VERSION "HNNBNNNYNNNNNNNNNNNNNNNNNNNNNNNNNNNNNNNNNN/4/%%%/4/'%**4NNN///"

NS_ :

BS_:

BU_: Radar MPC2

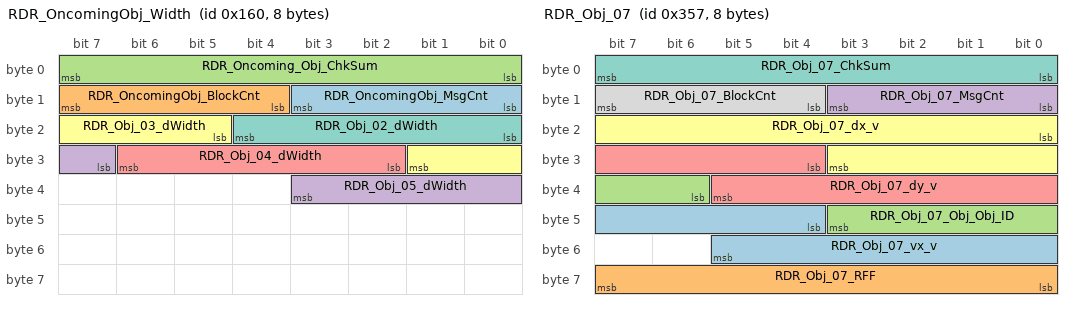
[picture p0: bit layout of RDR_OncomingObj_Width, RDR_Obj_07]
BO_ 352 RDR_OncomingObj_Width: 8 Radar
 SG_ RDR_OncomingObj_MsgCnt : 8|4@1+ (1,0) [0|15] ""  MPC2
 SG_ RDR_OncomingObj_BlockCnt : 12|4@1+ (1,0) [0|15] ""  MPC2
 SG_ RDR_Oncoming_Obj_ChkSum : 0|8@1+ (1,0) [0|255] ""  MPC2
 SG_ RDR_Obj_05_dWidth : 31|5@1+ (0.1,0) [0|3.1] ""  MPC2
 SG_ RDR_Obj_04_dWidth : 26|5@1+ (0.1,0) [0|3.1] ""  MPC2
 SG_ RDR_Obj_03_dWidth : 21|5@1+ (0.1,0) [0|3.1] ""  MPC2
 SG_ RDR_Obj_02_dWidth : 16|5@1+ (0.1,0) [0|3.1] ""  MPC2

BO_ 855 RDR_Obj_07: 8 Radar
 SG_ RDR_Obj_07_vx_v : 44|10@1+ (0.25,-128) [-128|127.75] "Unit_MeterPerSecon"  MPC2
 SG_ RDR_Obj_07_RFF : 56|8@1+ (1,0) [0|255] ""  MPC2
 SG_ RDR_Obj_07_Obj_Obj_ID : 38|6@1+ (1,0) [0|63] ""  MPC2
 SG_ RDR_Obj_07_MsgCnt : 8|4@1+ (1,0) [0|15] ""  MPC2
 SG_ RDR_Obj_07_dy_v : 28|10@1+ (0.0625,-32) [-32|31.9375] "Unit_Meter"  MPC2
 SG_ RDR_Obj_07_dx_v : 16|12@1+ (0.0625,0) [0|255.938] "Unit_Meter"  MPC2
 SG_ RDR_Obj_07_ChkSum : 0|8@1+ (1,0) [0|255] ""  MPC2
 SG_ RDR_Obj_07_BlockCnt : 12|4@1+ (1,0) [0|15] ""  MPC2

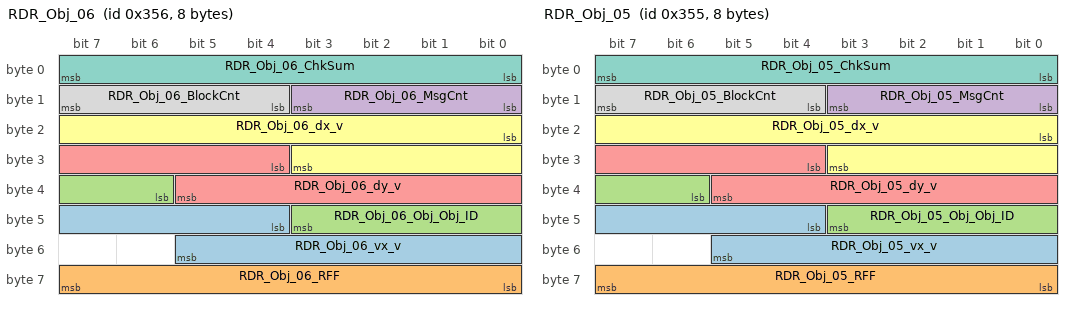
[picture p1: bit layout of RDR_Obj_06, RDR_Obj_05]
BO_ 854 RDR_Obj_06: 8 Radar
 SG_ RDR_Obj_06_vx_v : 44|10@1+ (0.25,-128) [-128|127.75] "Unit_MeterPerSecon"  MPC2
 SG_ RDR_Obj_06_RFF : 56|8@1+ (1,0) [0|255] ""  MPC2
 SG_ RDR_Obj_06_Obj_Obj_ID : 38|6@1+ (1,0) [0|63] ""  MPC2
 SG_ RDR_Obj_06_MsgCnt : 8|4@1+ (1,0) [0|155] ""  MPC2
 SG_ RDR_Obj_06_dy_v : 28|10@1+ (0.0625,-32) [-32|31.9375] "Unit_Meter"  MPC2
 SG_ RDR_Obj_06_dx_v : 16|12@1+ (0.0625,0) [0|255.938] "Unit_Meter"  MPC2
 SG_ RDR_Obj_06_ChkSum : 0|8@1+ (1,0) [0|255] ""  MPC2
 SG_ RDR_Obj_06_BlockCnt : 12|4@1+ (1,0) [0|15] ""  MPC2

BO_ 853 RDR_Obj_05: 8 Radar
 SG_ RDR_Obj_05_vx_v : 44|10@1+ (0.25,-128) [-128|127.75] "Unit_MeterPerSecon"  MPC2
 SG_ RDR_Obj_05_RFF : 56|8@1+ (1,0) [0|255] ""  MPC2
 SG_ RDR_Obj_05_Obj_Obj_ID : 38|6@1+ (1,0) [0|63] ""  MPC2
 SG_ RDR_Obj_05_MsgCnt : 8|4@1+ (1,0) [0|15] ""  MPC2
 SG_ RDR_Obj_05_dy_v : 28|10@1+ (0.0625,-32) [-32|31.9375] "Unit_Meter"  MPC2
 SG_ RDR_Obj_05_dx_v : 16|12@1+ (0.0625,0) [0|255.938] "Unit_Meter"  MPC2
 SG_ RDR_Obj_05_ChkSum : 0|8@1+ (1,0) [0|255] ""  MPC2
 SG_ RDR_Obj_05_BlockCnt : 12|4@1+ (1,0) [0|15] ""  MPC2

BO_ 7 New_Message_167: 8 Vector__XXX
 SG_ New_Signal_913 : 7|8@1+ (1,0) [0|0] "" Vector__XXX

BO_ 6 New_Message_166: 8 Vector__XXX
 SG_ New_Signal_912 : 19|8@1+ (1,0) [0|0] "" Vector__XXX

BO_ 5 New_Message_165: 8 Vector__XXX
 SG_ New_Signal_911 : 3|8@1+ (1,0) [0|0] "" Vector__XXX

BO_ 4 New_Message_164: 8 Vector__XXX
 SG_ New_Signal_910 : 39|8@1+ (1,0) [0|0] "" Vector__XXX

BO_ 3 New_Message_163: 8 Vector__XXX
 SG_ New_Signal_909 : 23|8@1+ (1,0) [0|0] "" Vector__XXX

BO_ 2 New_Message_162: 8 Vector__XXX
 SG_ New_Signal_908 : 7|8@1+ (1,0) [0|0] "" Vector__XXX

BO_ 1 New_Message_161: 8 Vector__XXX
 SG_ New_Signal_907 : 37|8@1+ (1,0) [0|0] "" Vector__XXX

BO_ 0 New_Message_160: 8 Vector__XXX
 SG_ New_Signal_906 : 12|8@1+ (1,0) [0|0] "" Vector__XXX

BO_ 2617162291 DEV_RADAR_I9: 8 Vector__XXX
 SG_ DEV_RADAR_I9_Data : 0|64@1+ (1,0) [0|1.84467440737096E+019] "" Vector__XXX

BO_ 2617162290 DEV_RADAR_I8: 8 Vector__XXX
 SG_ DEV_RADAR_I8_Data : 0|64@1+ (1,0) [0|1.84467440737096E+019] "" Vector__XXX

BO_ 2617162289 DEV_RADAR_I7: 8 Vector__XXX
 SG_ DEV_RADAR_I7_Data : 0|64@1+ (1,0) [0|1.84467440737096E+019] "" Vector__XXX

BO_ 2617162288 DEV_RADAR_I6: 8 Vector__XXX
 SG_ DEV_RADAR_I6_Data : 0|64@1+ (1,0) [0|1.84467440737096E+019] "" Vector__XXX

BO_ 2617162287 DEV_RADAR_I5: 8 Vector__XXX
 SG_ DEV_RADAR_I5_Data : 0|64@1+ (1,0) [0|1.84467440737096E+019] "" Vector__XXX

BO_ 2617162286 DEV_RADAR_I4: 8 Vector__XXX
 SG_ DEV_RADAR_I4_Data : 0|64@1+ (1,0) [0|1.84467440737096E+019] "" Vector__XXX

BO_ 2617162285 DEV_RADAR_I32: 8 Vector__XXX
 SG_ DEV_RADAR_I32_Data : 0|64@1+ (1,0) [0|1.84467440737096E+019] "" Vector__XXX

BO_ 2617162284 DEV_RADAR_I31: 8 Vector__XXX
 SG_ DEV_RADAR_I31_Data : 0|64@1+ (1,0) [0|1.84467440737096E+019] "" Vector__XXX

BO_ 2617162283 DEV_RADAR_I30: 8 Vector__XXX
 SG_ DEV_RADAR_I30_Data : 0|64@1+ (1,0) [0|1.84467440737096E+019] "" Vector__XXX

BO_ 2617162282 DEV_RADAR_I3: 8 Vector__XXX
 SG_ DEV_RADAR_I3_Data : 0|64@1+ (1,0) [0|1.84467440737096E+019] "" Vector__XXX

BO_ 2617162281 DEV_RADAR_I29: 8 Vector__XXX
 SG_ DEV_RADAR_I29_Data : 0|64@1+ (1,0) [0|1.84467440737096E+019] "" Vector__XXX

BO_ 2617162280 DEV_RADAR_I28: 8 Vector__XXX
 SG_ DEV_RADAR_I28_Data : 0|64@1+ (1,0) [0|1.84467440737096E+019] "" Vector__XXX

BO_ 2617162279 DEV_RADAR_I27: 8 Vector__XXX
 SG_ DEV_RADAR_I27_Data : 0|64@1+ (1,0) [0|1.84467440737096E+019] "" Vector__XXX

BO_ 2617162278 DEV_RADAR_I26: 8 Vector__XXX
 SG_ DEV_RADAR_I26_Data : 0|64@1+ (1,0) [0|1.84467440737096E+019] "" Vector__XXX

BO_ 2617162277 DEV_RADAR_I25: 8 Vector__XXX
 SG_ DEV_RADAR_I25_Data : 0|64@1+ (1,0) [0|1.84467440737096E+019] "" Vector__XXX

BO_ 2617162276 DEV_RADAR_I24: 8 Vector__XXX
 SG_ DEV_RADAR_I24_Data : 0|64@1+ (1,0) [0|1.84467440737096E+019] "" Vector__XXX

BO_ 2617162275 DEV_RADAR_I23: 8 Vector__XXX
 SG_ DEV_RADAR_I23_Data : 0|64@1+ (1,0) [0|1.84467440737096E+019] "" Vector__XXX

BO_ 2617162274 DEV_RADAR_I22: 8 Vector__XXX
 SG_ DEV_RADAR_I22_Data : 0|64@1+ (1,0) [0|1.84467440737096E+019] "" Vector__XXX

BO_ 2617162273 DEV_RADAR_I21: 8 Vector__XXX
 SG_ DEV_RADAR_I21_Data : 0|64@1+ (1,0) [0|1.84467440737096E+019] "" Vector__XXX

BO_ 2617162271 DEV_RADAR_I2: 8 Vector__XXX
 SG_ DEV_RADAR_I2_Data : 0|64@1+ (1,0) [0|1.84467440737096E+019] "" Vector__XXX

BO_ 2617162270 DEV_RADAR_I19: 8 Vector__XXX
 SG_ DEV_RADAR_I19_Data : 0|64@1+ (1,0) [0|1.84467440737096E+019] "" Vector__XXX

BO_ 2617162269 DEV_RADAR_I18: 8 Vector__XXX
 SG_ DEV_RADAR_I18_Data : 0|64@1+ (1,0) [0|1.84467440737096E+019] "" Vector__XXX

BO_ 2617162268 DEV_RADAR_I17: 8 Vector__XXX
 SG_ DEV_RADAR_I17_Data : 0|64@1+ (1,0) [0|1.84467440737096E+019] "" Vector__XXX

BO_ 2617162267 DEV_RADAR_I16: 8 Vector__XXX
 SG_ DEV_RADAR_I16_Data : 0|64@1+ (1,0) [0|1.84467440737096E+019] "" Vector__XXX

BO_ 2617162266 DEV_RADAR_I15: 8 Vector__XXX
 SG_ DEV_RADAR_I15_Data : 0|64@1+ (1,0) [0|1.84467440737096E+019] "" Vector__XXX

BO_ 2617162265 DEV_RADAR_I14: 8 Vector__XXX
 SG_ DEV_RADAR_I14_Data : 0|64@1+ (1,0) [0|1.84467440737096E+019] "" Vector__XXX

BO_ 2617162264 DEV_RADAR_I13: 8 Vector__XXX
 SG_ DEV_RADAR_I13_Data : 0|64@1+ (1,0) [0|1.84467440737096E+019] "" Vector__XXX

BO_ 2617162263 DEV_RADAR_I12: 8 Vector__XXX
 SG_ DEV_RADAR_I12_Data : 0|64@1+ (1,0) [0|1.84467440737096E+019] "" Vector__XXX

BO_ 2617162262 DEV_RADAR_I11: 8 Vector__XXX
 SG_ DEV_RADAR_I11_Data : 0|64@1+ (1,0) [0|1.84467440737096E+019] "" Vector__XXX

BO_ 2617162272 DEV_RADAR_I20: 8 Vector__XXX
 SG_ DEV_RADAR_I20_Data : 0|64@1+ (1,0) [0|1.84467440737096E+019] "" Vector__XXX

BO_ 2617162261 DEV_RADAR_I10: 8 Vector__XXX
 SG_ DEV_RADAR_I10_Data : 0|64@1+ (1,0) [0|1.84467440737096E+019] "" Vector__XXX

BO_ 2617162260 DEV_RADAR_I1: 8 Vector__XXX
 SG_ DEV_RADAR_I1_Data : 0|64@1+ (1,0) [0|1.84467440737096E+019] "" Vector__XXX

BO_ 2617162258 DEV_VR_Function_TX: 8 Vector__XXX
 SG_ DEV_VR_Function_TX_Data : 0|64@1+ (1,0) [0|1.84467440737096E+019] "" Vector__XXX

BO_ 2617162259 DEV_ACC_TX_15: 8 Vector__XXX
 SG_ DEV_ACC_TX_15_Data : 0|64@1+ (1,0) [0|1.84467440737096E+019] "" Vector__XXX

BO_ 2617162248 DEV_ACC_TX_06: 8 Vector__XXX
 SG_ DEV_ACC_TX_06_Data : 0|64@1+ (1,0) [0|1.84467440737096E+019] "" Vector__XXX

BO_ 2617162247 DEV_ACC_TX_05: 8 Vector__XXX
 SG_ DEV_ACC_TX_05_Data : 0|64@1+ (1,0) [0|1.84467440737096E+019] "" Vector__XXX

BO_ 2617162246 DEV_ACC_TX_04: 8 Vector__XXX
 SG_ DEV_ACC_TX_04_Data : 0|64@1+ (1,0) [0|1.84467440737096E+019] "" Vector__XXX

BO_ 2617162245 DEV_ACC_TX_03: 8 Vector__XXX
 SG_ DEV_ACC_TX_03_Data : 0|64@1+ (1,0) [0|1.84467440737096E+019] "" Vector__XXX

BO_ 2617162256 DEV_ACC_TX_14: 8 Vector__XXX
 SG_ DEV_ACC_TX_14_Data : 0|64@1+ (1,0) [0|1.84467440737096E+019] "" Vector__XXX

BO_ 2617162254 DEV_ACC_TX_12: 8 Vector__XXX
 SG_ DEV_ACC_TX_12_Data : 0|64@1+ (1,0) [0|1.84467440737096E+019] "" Vector__XXX

BO_ 2617162253 DEV_ACC_TX_11: 8 Vector__XXX
 SG_ DEV_ACC_TX_11_Data : 0|64@1+ (1,0) [0|1.84467440737096E+019] "" Vector__XXX

BO_ 2617162252 DEV_ACC_TX_10: 8 Vector__XXX
 SG_ DEV_ACC_TX_10_Data : 0|64@1+ (1,0) [0|1.84467440737096E+019] "" Vector__XXX

BO_ 2617162251 DEV_ACC_TX_09: 8 Vector__XXX
 SG_ DEV_ACC_TX_09_Data : 0|64@1+ (1,0) [0|1.84467440737096E+019] "" Vector__XXX

BO_ 2617162250 DEV_ACC_TX_08: 8 Vector__XXX
 SG_ DEV_ACC_TX_08_Data : 0|64@1+ (1,0) [0|1.84467440737096E+019] "" Vector__XXX

BO_ 2617162249 DEV_ACC_TX_07: 8 Vector__XXX
 SG_ DEV_ACC_TX_07_Data : 0|64@1+ (1,0) [0|1.84467440737096E+019] "" Vector__XXX

BO_ 2617162244 DEV_ACC_TX_02: 8 Vector__XXX
 SG_ DEV_ACC_TX_02_Data : 0|64@1+ (1,0) [0|1.84467440737096E+019] "" Vector__XXX

BO_ 2617162243 DEV_ACC_TX_01: 8 Vector__XXX
 SG_ DEV_ACC_TX_01_Data : 0|64@1+ (1,0) [0|1.84467440737096E+019] "" Vector__XXX

BO_ 2617162255 DEV_ACC_TX_13: 8 Vector__XXX
 SG_ DEV_ACC_TX_13_Data : 0|64@1+ (1,0) [0|1.84467440737096E+019] "" Vector__XXX

BO_ 2617162257 DEV_VIDEO_Sync_TX: 8 Vector__XXX
 SG_ DEV_VIDEO_Sync_TX_Data : 0|64@1+ (1,0) [0|1.84467E+019] "" Vector__XXX

BO_ 2281601536 Dev_Video_SyncVisor_TX: 8 MPC2
 SG_ ImgTimeDelay : 32|32@1+ (0.1,0) [0|429496729.5] "ms" Vector__XXX
 SG_ ImgFrameCounter : 0|32@1+ (1,0) [0|4294967295] ""  Radar

BO_ 2617145882 BV_TRAMO_01: 8 MPC2
 SG_ BV_Tramo_Yaw : 18|14@1- (2E-005,0) [-0.16384|0.16382] "Unit_Radia" Vector__XXX
 SG_ BV_Tramo_Roll : 32|14@1- (2E-005,0) [-0.16384|0.16382] "Unit_Radia" Vector__XXX
 SG_ BV_Tramo_Pitch : 4|14@1- (2E-005,0) [-0.16384|0.16384] "Unit_Radia" Vector__XXX
 SG_ BV_Tramo_Counter : 48|4@1+ (1,0) [0|15] "" Vector__XXX
 SG_ BV_Tramo_Blockzaehler : 0|4@1+ (1,0) [0|15] "" Vector__XXX

BO_ 2617145883 BV_SUMO_01: 8 MPC2
 SG_ BV_Sumo_ver_Kruemm_Aend : 37|26@1- (1E-008,0) [-0.33554432|0.33554431] "Unit_per_square_meter" Vector__XXX
 SG_ BV_Sumo_ver_Kruemm : 11|26@1- (1E-008,0) [-0.33554432|0.33554431] "Unit_per_meter" Vector__XXX
 SG_ BV_Sumo_Vorausschau : 4|7@1+ (1,0) [0|127] "Unit_meter" Vector__XXX
 SG_ BV_Sumo_Blockzaehler : 0|4@1+ (1,0) [0|15] "" Vector__XXX

BO_ 2617146880 XCP_Kamera_DTO_01: 8 MPC2
 SG_ XCP_Kamera_DTO_01_Data : 0|64@1+ (1,0) [0|1.84467440737096E+019] "" Vector__XXX

BO_ 2617146881 XCP_Kamera_CRO_01: 8 Vector__XXX
 SG_ XCP_Kamera_CRO_01_Data : 0|64@1+ (1,0) [0|1.84467440737096E+019] ""  MPC2

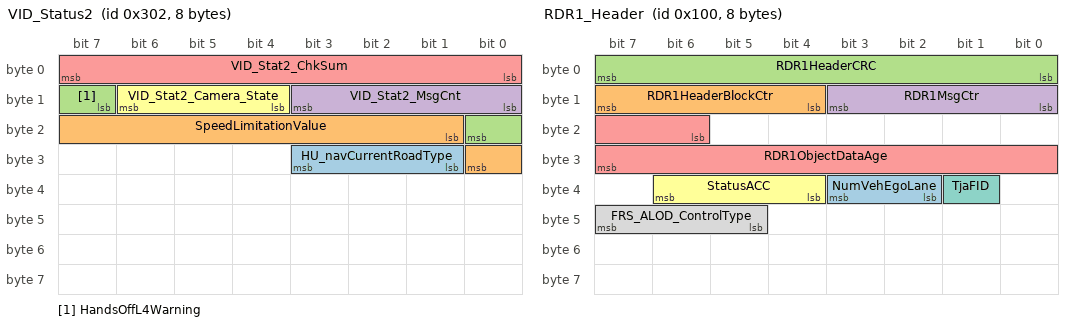
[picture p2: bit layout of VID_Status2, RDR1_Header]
BO_ 770 VID_Status2: 8 MPC2
 SG_ HU_navCurrentRoadType : 25|3@1+ (1,0) [0|7] ""  Radar
 SG_ SpeedLimitationValue : 17|8@1+ (1,0) [0|254] "Km/h"  Radar
 SG_ HandsOffL4Warning : 15|2@1+ (1,0) [0|3] ""  Radar
 SG_ VID_Stat2_MsgCnt : 8|4@1+ (1,0) [0|15] ""  Radar
 SG_ VID_Stat2_ChkSum : 0|8@1+ (1,0) [0|255] ""  Radar
 SG_ VID_Stat2_Camera_State : 12|3@1+ (1,0) [0|7] ""  Radar

BO_ 256 RDR1_Header: 8 Radar
 SG_ NumVehEgoLane : 34|2@1+ (1,0) [0|3] ""  MPC2
 SG_ RDR1HeaderBlockCtr : 12|4@1+ (1,0) [0|15] ""  MPC2
 SG_ RDR1HeaderCRC : 0|8@1+ (1,0) [0|255] ""  MPC2
 SG_ RDR1MsgCtr : 8|4@1+ (1,0) [0|15] ""  MPC2
 SG_ RDR1ObjectDataAge : 22|10@1+ (0.0009765625,0) [0|0.998046875] "Seconds"  MPC2
 SG_ StatusACC : 36|3@1+ (1,0) [0|7] ""  MPC2
 SG_ TjaFID : 33|1@1+ (1,0) [0|1] ""  MPC2
 SG_ FRS_ALOD_ControlType : 45|3@1+ (1,0) [0|7] ""  MPC2

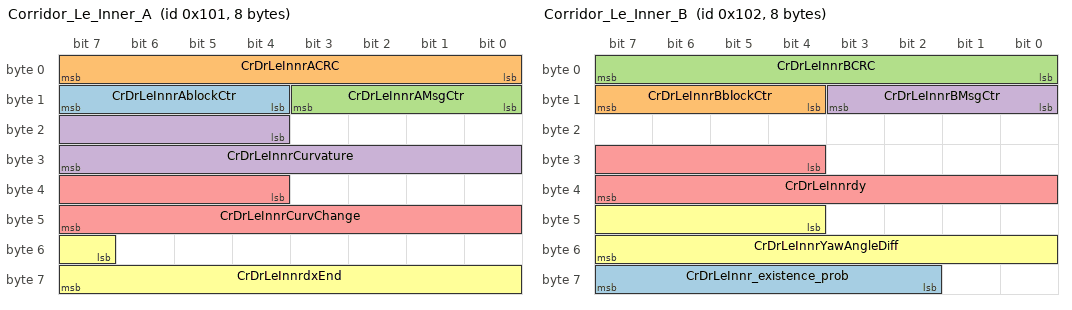
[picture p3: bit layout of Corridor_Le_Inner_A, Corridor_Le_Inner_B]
BO_ 257 Corridor_Le_Inner_A: 8 Radar
 SG_ CrDrLeInnrAblockCtr : 12|4@1+ (1,0) [0|15] ""  MPC2
 SG_ CrDrLeInnrACRC : 0|8@1+ (1,0) [0|255] ""  MPC2
 SG_ CrDrLeInnrAMsgCtr : 8|4@1+ (1,0) [0|15] ""  MPC2
 SG_ CrDrLeInnrCurvature : 20|12@1+ (1,-2047) [-2047|2048] "per_meter"  MPC2
 SG_ CrDrLeInnrCurvChange : 36|12@1+ (1,-2047) [-2047|2048] "per_square_meter"  MPC2
 SG_ CrDrLeInnrdxEnd : 55|9@1+ (0.25,0) [0|127.75] "Unit_Meter"  MPC2

BO_ 258 Corridor_Le_Inner_B: 8 Radar
 SG_ CrDrLeInnr_existence_prob : 58|6@1+ (0.015625,0) [0|0.984375] ""  MPC2
 SG_ CrDrLeInnrBblockCtr : 12|4@1+ (1,0) [0|15] ""  MPC2
 SG_ CrDrLeInnrBCRC : 0|8@1+ (1,0) [0|255] ""  MPC2
 SG_ CrDrLeInnrBMsgCtr : 8|4@1+ (1,0) [0|15] ""  MPC2
 SG_ CrDrLeInnrdy : 28|12@1+ (0.00390625,-8) [-8|7.99609375] "Unit_Meter"  MPC2
 SG_ CrDrLeInnrYawAngleDiff : 44|12@1+ (0.00048828125,-1) [-1|0.99951171875] "Radians"  MPC2

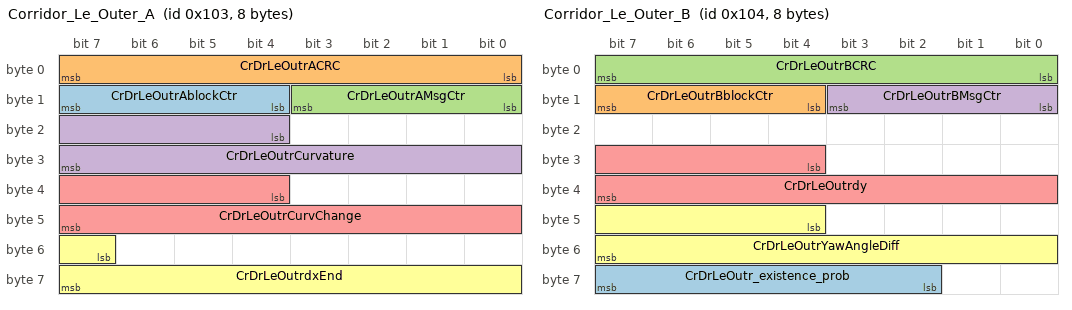
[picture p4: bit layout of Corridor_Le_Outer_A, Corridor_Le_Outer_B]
BO_ 259 Corridor_Le_Outer_A: 8 Radar
 SG_ CrDrLeOutrAblockCtr : 12|4@1+ (1,0) [0|15] ""  MPC2
 SG_ CrDrLeOutrACRC : 0|8@1+ (1,0) [0|255] ""  MPC2
 SG_ CrDrLeOutrAMsgCtr : 8|4@1+ (1,0) [0|15] ""  MPC2
 SG_ CrDrLeOutrCurvature : 20|12@1+ (1,-2047) [-2047|2048] "per_meter"  MPC2
 SG_ CrDrLeOutrCurvChange : 36|12@1+ (1,-2047) [-2047|2048] "per_square_meter"  MPC2
 SG_ CrDrLeOutrdxEnd : 55|9@1+ (0.25,0) [0|127.75] "Unit_Meter"  MPC2

BO_ 260 Corridor_Le_Outer_B: 8 Radar
 SG_ CrDrLeOutr_existence_prob : 58|6@1+ (0.015625,0) [0|0.984375] ""  MPC2
 SG_ CrDrLeOutrBblockCtr : 12|4@1+ (1,0) [0|15] ""  MPC2
 SG_ CrDrLeOutrBCRC : 0|8@1+ (1,0) [0|255] ""  MPC2
 SG_ CrDrLeOutrBMsgCtr : 8|4@1+ (1,0) [0|15] ""  MPC2
 SG_ CrDrLeOutrdy : 28|12@1+ (0.00390625,-8) [-8|7.99609375] "Unit_Meter"  MPC2
 SG_ CrDrLeOutrYawAngleDiff : 44|12@1+ (0.00048828125,-1) [-1|0.99951171875] "Radians"  MPC2

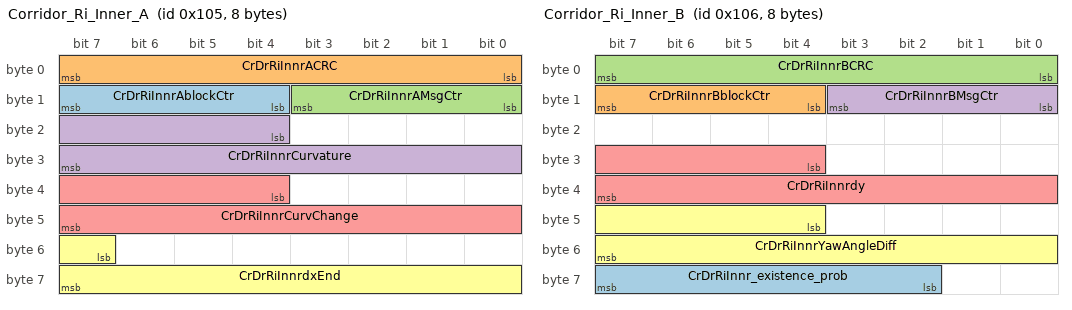
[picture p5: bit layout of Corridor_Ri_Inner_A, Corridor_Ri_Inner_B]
BO_ 261 Corridor_Ri_Inner_A: 8 Radar
 SG_ CrDrRiInnrAblockCtr : 12|4@1+ (1,0) [0|15] ""  MPC2
 SG_ CrDrRiInnrACRC : 0|8@1+ (1,0) [0|255] ""  MPC2
 SG_ CrDrRiInnrAMsgCtr : 8|4@1+ (1,0) [0|15] ""  MPC2
 SG_ CrDrRiInnrCurvature : 20|12@1+ (1,-2047) [-2047|2048] "per_meter"  MPC2
 SG_ CrDrRiInnrCurvChange : 36|12@1+ (1,-2047) [-2047|2048] "per_square_meter"  MPC2
 SG_ CrDrRiInnrdxEnd : 55|9@1+ (0.25,0) [0|127.75] "Unit_Meter"  MPC2

BO_ 262 Corridor_Ri_Inner_B: 8 Radar
 SG_ CrDrRiInnr_existence_prob : 58|6@1+ (0.015625,0) [0|0.984375] ""  MPC2
 SG_ CrDrRiInnrBblockCtr : 12|4@1+ (1,0) [0|15] ""  MPC2
 SG_ CrDrRiInnrBCRC : 0|8@1+ (1,0) [0|255] ""  MPC2
 SG_ CrDrRiInnrBMsgCtr : 8|4@1+ (1,0) [0|15] ""  MPC2
 SG_ CrDrRiInnrdy : 28|12@1+ (0.00390625,-8) [-8|7.99609375] "Unit_Meter"  MPC2
 SG_ CrDrRiInnrYawAngleDiff : 44|12@1+ (0.00048828125,-1) [-1|0.99951171875] "Radians"  MPC2

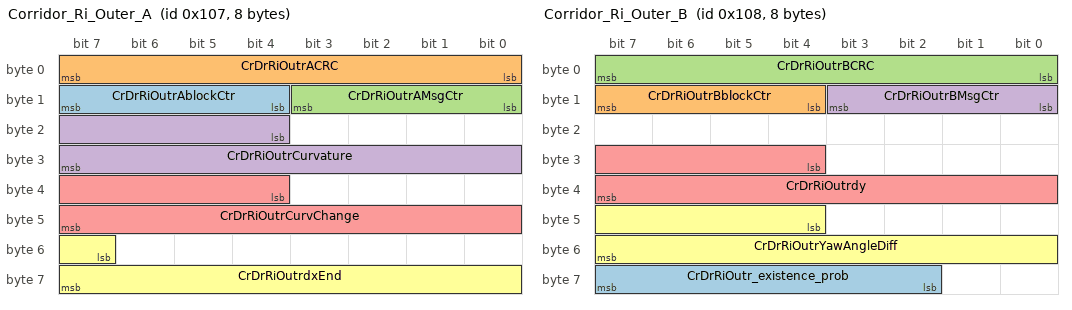
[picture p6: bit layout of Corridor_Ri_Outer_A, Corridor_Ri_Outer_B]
BO_ 263 Corridor_Ri_Outer_A: 8 Radar
 SG_ CrDrRiOutrAblockCtr : 12|4@1+ (1,0) [0|15] ""  MPC2
 SG_ CrDrRiOutrACRC : 0|8@1+ (1,0) [0|255] ""  MPC2
 SG_ CrDrRiOutrAMsgCtr : 8|4@1+ (1,0) [0|15] ""  MPC2
 SG_ CrDrRiOutrCurvature : 20|12@1+ (1,-2047) [-2047|2048] "per_meter"  MPC2
 SG_ CrDrRiOutrCurvChange : 36|12@1+ (1,-2047) [-2047|2048] "per_square_meter"  MPC2
 SG_ CrDrRiOutrdxEnd : 55|9@1+ (0.25,0) [0|127.75] "Unit_Meter"  MPC2

BO_ 264 Corridor_Ri_Outer_B: 8 Radar
 SG_ CrDrRiOutr_existence_prob : 58|6@1+ (0.015625,0) [0|0.984375] ""  MPC2
 SG_ CrDrRiOutrBblockCtr : 12|4@1+ (1,0) [0|15] ""  MPC2
 SG_ CrDrRiOutrBCRC : 0|8@1+ (1,0) [0|255] ""  MPC2
 SG_ CrDrRiOutrBMsgCtr : 8|4@1+ (1,0) [0|15] ""  MPC2
 SG_ CrDrRiOutrdy : 28|12@1+ (0.00390625,-8) [-8|7.99609375] "Unit_Meter"  MPC2
 SG_ CrDrRiOutrYawAngleDiff : 44|12@1+ (0.00048828125,-1) [-1|0.99951171875] "Radians"  MPC2

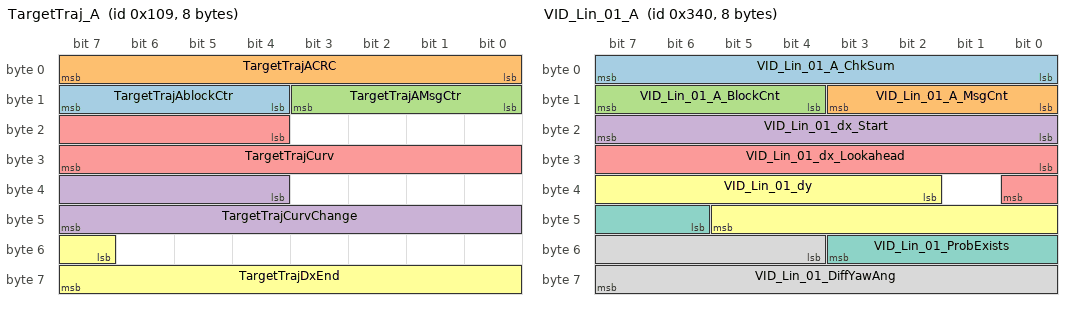
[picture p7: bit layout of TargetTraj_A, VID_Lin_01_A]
BO_ 265 TargetTraj_A: 8 Radar
 SG_ TargetTrajAblockCtr : 12|4@1+ (1,0) [0|15] ""  MPC2
 SG_ TargetTrajACRC : 0|8@1+ (1,0) [0|255] ""  MPC2
 SG_ TargetTrajAMsgCtr : 8|4@1+ (1,0) [0|15] ""  MPC2
 SG_ TargetTrajCurvChange : 36|12@1+ (1,-2047) [-2047|2048] ""  MPC2
 SG_ TargetTrajCurv : 20|12@1+ (1,-2047) [-2047|2048] ""  MPC2
 SG_ TargetTrajDxEnd : 55|9@1+ (0.25,0) [0|127.75] "Unit_Meter"  MPC2

BO_ 266 TargetTraj_B: 8 Radar
 SG_ TargetTrajBblockCtr : 12|4@1+ (1,0) [0|15] ""  MPC2
 SG_ TargetTrajBCRC : 0|8@1+ (1,0) [0|255] ""  MPC2
 SG_ TargetTrajBMsgCtr : 8|4@1+ (1,0) [0|15] ""  MPC2
 SG_ TargetTrajDy : 52|12@1+ (0.00390625,-8) [-8|7.99609375] "Unit_Meter"  MPC2
 SG_ TargetTrajExistnceProb : 26|6@1+ (0.015625,0) [0|0.984375] ""  MPC2
 SG_ TargetTrajYawAngleDiff : 36|12@1+ (0.00048828125,-1) [-1|0.99951171875] "Radians"  MPC2

BO_ 769 VID_Status: 8 MPC2
 SG_ VID_Stat_ChkSum : 0|8@1+ (1,0) [0|255] ""  Radar
 SG_ VID_Stat_MsgCnt : 8|4@1+ (1,0) [0|15] ""  Radar
 SG_ VID_Stat_BlockCnt : 12|4@1+ (1,0) [0|15] ""  Radar
 SG_ VID_Stat_ObjDataAge : 16|10@1+ (0.0009765625,0) [0|0.998046875] "Unit_Secon"  Radar
 SG_ VID_Stat_Upd_Cnt : 26|4@1+ (1,0) [0|15] ""  Radar
 SG_ VID_Stat_Intruder : 30|1@1+ (1,0) [0|1] ""  Radar
 SG_ VID_LDA_Counter : 32|4@1+ (1,0) [0|15] ""  Radar
 SG_ VID_Stat_MOD_Cnt : 36|4@1+ (1,0) [0|15] ""  Radar
 SG_ VID_Stat_PED_Warning : 40|2@1+ (1,0) [0|3] ""  Radar
 SG_ VID_Stat_RFD_notAvail : 42|2@1+ (1,0) [0|3] ""  Radar
 SG_ VID_Stat_PED_Config : 44|3@1+ (1,0) [0|7] ""  Radar
 SG_ VID_Stat_LaneDataAge : 47|10@1+ (0.0009765625,0) [0|0.998046875] "Unit_Secon"  Radar
 SG_ VID_Stat_blindness_det : 61|1@1+ (1,0) [0|1] ""  Radar
 SG_ VID_Stat_Freesight_nOK : 60|1@1+ (1,0) [0|1] ""  Radar
 SG_ VID_Stat_Error : 62|1@1+ (1,0) [0|1] ""  Radar
 SG_ VID_Stat_NotAvail : 63|1@1+ (1,0) [0|1] ""  Radar
 SG_ VID_Stat_TJAICAStatus : 57|3@1+ (1,0) [0|7] ""  Radar

BO_ 832 VID_Lin_01_A: 8 MPC2
 SG_ VID_Lin_01_A_ChkSum : 0|8@1+ (1,0) [0|255] ""  Radar
 SG_ VID_Lin_01_A_MsgCnt : 8|4@1+ (1,0) [0|15] ""  Radar
 SG_ VID_Lin_01_A_BlockCnt : 12|4@1+ (1,0) [0|15] ""  Radar
 SG_ VID_Lin_01_dx_Start : 16|8@1+ (0.25,0) [0|63.75] "Unit_Meter"  Radar
 SG_ VID_Lin_01_dx_Lookahead : 24|9@1+ (0.25,0) [0|127.75] "Unit_Meter"  Radar
 SG_ VID_Lin_01_dy : 34|12@1+ (0.00390625,-8) [-8|7.99609375] "Unit_Meter"  Radar
 SG_ VID_Lin_01_ProbExists : 46|6@1+ (0.015625,0) [0|0.984375] "Unit_Meter"  Radar
 SG_ VID_Lin_01_DiffYawAng : 52|12@1+ (0.00048828125,-1) [-1|0.99951171875] "Unit_Radia"  Radar

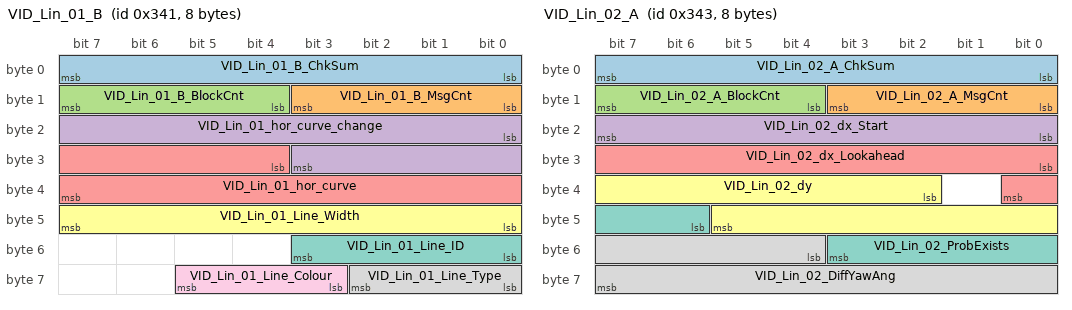
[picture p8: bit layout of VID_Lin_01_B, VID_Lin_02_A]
BO_ 833 VID_Lin_01_B: 8 MPC2
 SG_ VID_Lin_01_B_ChkSum : 0|8@1+ (1,0) [0|255] ""  Radar
 SG_ VID_Lin_01_B_MsgCnt : 8|4@1+ (1,0) [0|15] ""  Radar
 SG_ VID_Lin_01_B_BlockCnt : 12|4@1+ (1,0) [0|15] ""  Radar
 SG_ VID_Lin_01_hor_curve_change : 16|12@1+ (1,-2047) [-2047|2048] ""  Radar
 SG_ VID_Lin_01_hor_curve : 28|12@1+ (1,-2047) [-2047|2048] ""  Radar
 SG_ VID_Lin_01_Line_Width : 40|8@1+ (0.00390625,0) [0|0.99609375] "Unit_Meter"  Radar
 SG_ VID_Lin_01_Line_ID : 48|4@1+ (1,0) [1|15] ""  Radar
 SG_ VID_Lin_01_Line_Type : 56|3@1+ (1,0) [0|7] ""  Radar
 SG_ VID_Lin_01_Line_Colour : 59|3@1+ (1,0) [0|7] ""  Radar

BO_ 835 VID_Lin_02_A: 8 MPC2
 SG_ VID_Lin_02_A_ChkSum : 0|8@1+ (1,0) [0|255] ""  Radar
 SG_ VID_Lin_02_A_MsgCnt : 8|4@1+ (1,0) [0|15] ""  Radar
 SG_ VID_Lin_02_A_BlockCnt : 12|4@1+ (1,0) [0|15] ""  Radar
 SG_ VID_Lin_02_dx_Start : 16|8@1+ (0.25,0) [0|63.75] "Unit_Meter"  Radar
 SG_ VID_Lin_02_dx_Lookahead : 24|9@1+ (0.25,0) [0|127.75] "Unit_Meter"  Radar
 SG_ VID_Lin_02_dy : 34|12@1+ (0.00390625,-8) [-8|7.99609375] "Unit_Meter"  Radar
 SG_ VID_Lin_02_ProbExists : 46|6@1+ (0.015625,0) [0|0.984375] "Unit_Meter"  Radar
 SG_ VID_Lin_02_DiffYawAng : 52|12@1+ (0.00048828125,-1) [-1|0.99951171875] "Unit_Radia"  Radar

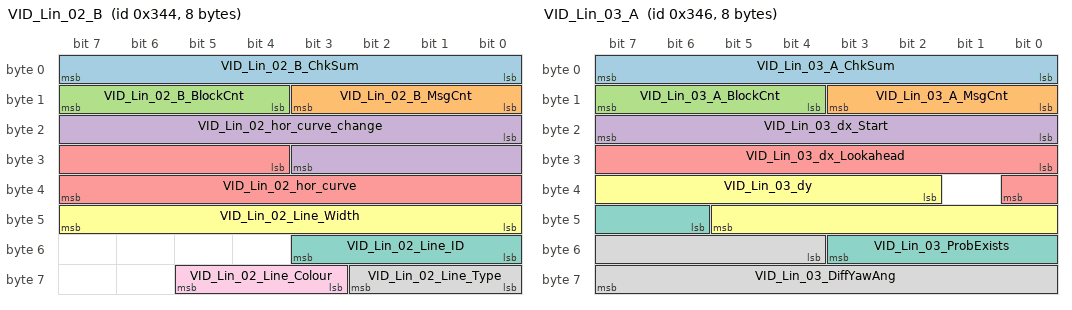
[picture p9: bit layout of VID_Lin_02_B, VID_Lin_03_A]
BO_ 836 VID_Lin_02_B: 8 MPC2
 SG_ VID_Lin_02_B_ChkSum : 0|8@1+ (1,0) [0|255] ""  Radar
 SG_ VID_Lin_02_B_MsgCnt : 8|4@1+ (1,0) [0|15] ""  Radar
 SG_ VID_Lin_02_B_BlockCnt : 12|4@1+ (1,0) [0|15] ""  Radar
 SG_ VID_Lin_02_hor_curve_change : 16|12@1+ (1,-2047) [-2047|2048] ""  Radar
 SG_ VID_Lin_02_hor_curve : 28|12@1+ (1,-2047) [-2047|2048] ""  Radar
 SG_ VID_Lin_02_Line_Width : 40|8@1+ (0.00390625,0) [0|0.99609375] "Unit_Meter"  Radar
 SG_ VID_Lin_02_Line_ID : 48|4@1+ (1,0) [1|15] ""  Radar
 SG_ VID_Lin_02_Line_Type : 56|3@1+ (1,0) [0|7] ""  Radar
 SG_ VID_Lin_02_Line_Colour : 59|3@1+ (1,0) [0|7] ""  Radar

BO_ 838 VID_Lin_03_A: 8 MPC2
 SG_ VID_Lin_03_A_ChkSum : 0|8@1+ (1,0) [0|255] ""  Radar
 SG_ VID_Lin_03_A_MsgCnt : 8|4@1+ (1,0) [0|15] ""  Radar
 SG_ VID_Lin_03_A_BlockCnt : 12|4@1+ (1,0) [0|15] ""  Radar
 SG_ VID_Lin_03_dx_Start : 16|8@1+ (0.25,0) [0|63.75] "Unit_Meter"  Radar
 SG_ VID_Lin_03_dx_Lookahead : 24|9@1+ (0.25,0) [0|127.75] "Unit_Meter"  Radar
 SG_ VID_Lin_03_dy : 34|12@1+ (0.00390625,-8) [-8|7.99609375] "Unit_Meter"  Radar
 SG_ VID_Lin_03_ProbExists : 46|6@1+ (0.015625,0) [0|0.984375] "Unit_Meter"  Radar
 SG_ VID_Lin_03_DiffYawAng : 52|12@1+ (0.00048828125,-1) [-1|0.99951171875] "Unit_Radia"  Radar

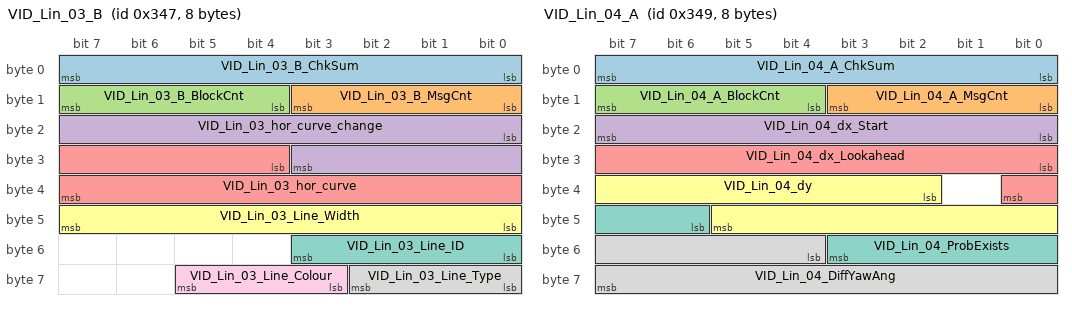
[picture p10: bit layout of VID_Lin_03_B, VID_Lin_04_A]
BO_ 839 VID_Lin_03_B: 8 MPC2
 SG_ VID_Lin_03_B_ChkSum : 0|8@1+ (1,0) [0|255] ""  Radar
 SG_ VID_Lin_03_B_MsgCnt : 8|4@1+ (1,0) [0|15] ""  Radar
 SG_ VID_Lin_03_B_BlockCnt : 12|4@1+ (1,0) [0|15] ""  Radar
 SG_ VID_Lin_03_hor_curve_change : 16|12@1+ (1,-2047) [-2047|2048] ""  Radar
 SG_ VID_Lin_03_hor_curve : 28|12@1+ (1,-2047) [-2047|2048] ""  Radar
 SG_ VID_Lin_03_Line_Width : 40|8@1+ (0.00390625,0) [0|0.99609375] "Unit_Meter"  Radar
 SG_ VID_Lin_03_Line_ID : 48|4@1+ (1,0) [1|15] ""  Radar
 SG_ VID_Lin_03_Line_Type : 56|3@1+ (1,0) [0|7] ""  Radar
 SG_ VID_Lin_03_Line_Colour : 59|3@1+ (1,0) [0|7] ""  Radar

BO_ 841 VID_Lin_04_A: 8 MPC2
 SG_ VID_Lin_04_A_ChkSum : 0|8@1+ (1,0) [0|255] ""  Radar
 SG_ VID_Lin_04_A_MsgCnt : 8|4@1+ (1,0) [0|15] ""  Radar
 SG_ VID_Lin_04_A_BlockCnt : 12|4@1+ (1,0) [0|15] ""  Radar
 SG_ VID_Lin_04_dx_Start : 16|8@1+ (0.25,0) [0|63.75] "Unit_Meter"  Radar
 SG_ VID_Lin_04_dx_Lookahead : 24|9@1+ (0.25,0) [0|127.75] "Unit_Meter"  Radar
 SG_ VID_Lin_04_dy : 34|12@1+ (0.00390625,-8) [-8|7.99609375] "Unit_Meter"  Radar
 SG_ VID_Lin_04_ProbExists : 46|6@1+ (0.015625,0) [0|0.984375] "Unit_Meter"  Radar
 SG_ VID_Lin_04_DiffYawAng : 52|12@1+ (0.00048828125,-1) [-1|0.99951171875] "Unit_Radia"  Radar

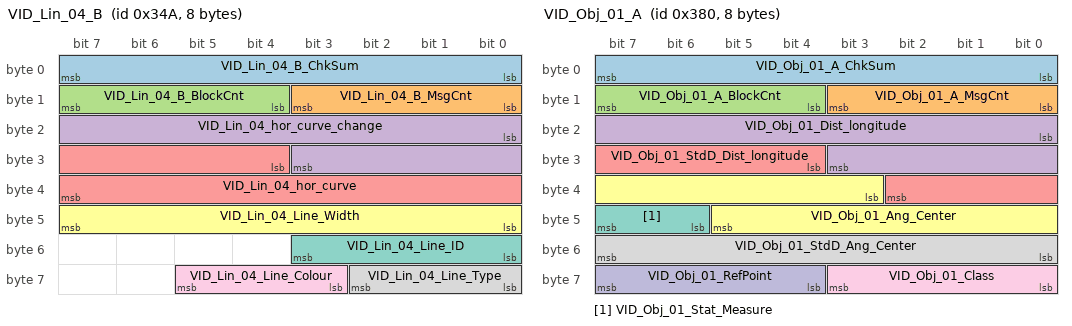
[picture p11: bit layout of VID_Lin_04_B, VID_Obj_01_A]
BO_ 842 VID_Lin_04_B: 8 MPC2
 SG_ VID_Lin_04_B_ChkSum : 0|8@1+ (1,0) [0|255] ""  Radar
 SG_ VID_Lin_04_B_MsgCnt : 8|4@1+ (1,0) [0|15] ""  Radar
 SG_ VID_Lin_04_B_BlockCnt : 12|4@1+ (1,0) [0|15] ""  Radar
 SG_ VID_Lin_04_hor_curve_change : 16|12@1+ (1,-2047) [-2047|2048] ""  Radar
 SG_ VID_Lin_04_hor_curve : 28|12@1+ (1,-2047) [-2047|2048] ""  Radar
 SG_ VID_Lin_04_Line_Width : 40|8@1+ (0.00390625,0) [0|0.99609375] "Unit_Meter"  Radar
 SG_ VID_Lin_04_Line_ID : 48|4@1+ (1,0) [1|15] ""  Radar
 SG_ VID_Lin_04_Line_Type : 56|3@1+ (1,0) [0|7] ""  Radar
 SG_ VID_Lin_04_Line_Colour : 59|3@1+ (1,0) [0|7] ""  Radar

BO_ 1385 VID_Mounting: 8 MPC2
 SG_ VID_MountPos_MsgCnt : 8|4@1+ (1,0) [0|15] "" Vector__XXX
 SG_ VID_MountPos_ChkSum : 0|8@1+ (1,0) [0|255] "" Vector__XXX
 SG_ VID_MountPos_x : 12|12@1+ (0.0009765625,-1.5) [-1.5|2.498046875] "Unit_Meter"  Radar
 SG_ VID_MountPos_y : 24|12@1+ (0.0009765625,-2) [-2|1.998046875] "Unit_Meter"  Radar
 SG_ VID_MountPos_z : 36|12@1+ (0.0009765625,-1) [-1|2.998046875] "Unit_Meter"  Radar

BO_ 896 VID_Obj_01_A: 8 MPC2
 SG_ VID_Obj_01_A_ChkSum : 0|8@1+ (1,0) [0|255] ""  Radar
 SG_ VID_Obj_01_A_MsgCnt : 8|4@1+ (1,0) [0|15] ""  Radar
 SG_ VID_Obj_01_A_BlockCnt : 12|4@1+ (1,0) [0|15] ""  Radar
 SG_ VID_Obj_01_Dist_longitude : 16|12@1+ (0.0625,0) [0|255.875] "Unit_Meter"  Radar
 SG_ VID_Obj_01_StdD_Dist_longitude : 28|7@1+ (0.25,0) [0|31.5] "Unit_Meter"  Radar
 SG_ VID_Obj_01_Ang_Center : 35|11@1+ (0.00048828125,-0.5) [-0.5|0.4990234375] "Unit_Radia"  Radar
 SG_ VID_Obj_01_Stat_Measure : 46|2@1+ (1,0) [0|3] ""  Radar
 SG_ VID_Obj_01_StdD_Ang_Center : 48|8@1+ (0.0009765625,0) [0|0.248046875] "Unit_Radia"  Radar
 SG_ VID_Obj_01_Class : 56|4@1+ (1,0) [0|15] ""  Radar
 SG_ VID_Obj_01_RefPoint : 60|4@1+ (1,0) [0|15] ""  Radar

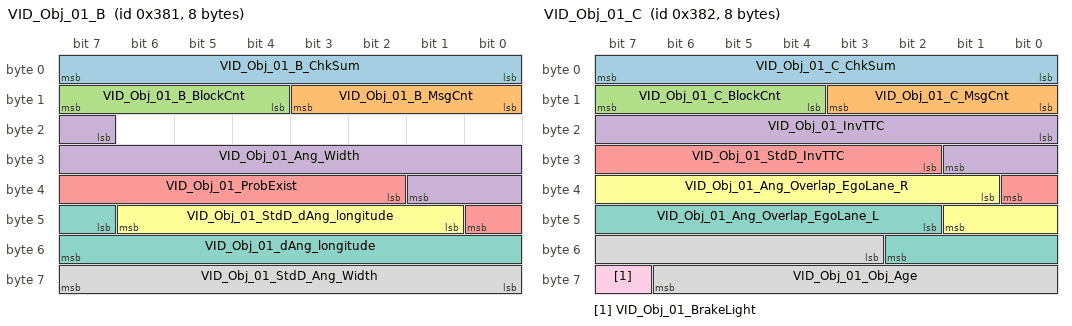
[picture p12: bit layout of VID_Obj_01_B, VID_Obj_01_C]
BO_ 897 VID_Obj_01_B: 8 MPC2
 SG_ VID_Obj_01_B_ChkSum : 0|8@1+ (1,0) [0|255] ""  Radar
 SG_ VID_Obj_01_B_MsgCnt : 8|4@1+ (1,0) [0|15] ""  Radar
 SG_ VID_Obj_01_B_BlockCnt : 12|4@1+ (1,0) [0|15] ""  Radar
 SG_ VID_Obj_01_Ang_Width : 23|11@1+ (0.00048828125,0) [0|0.9990234375] "Unit_Radia"  Radar
 SG_ VID_Obj_01_ProbExist : 34|7@1+ (0.0078125,0.015625) [0.015625|1] ""  Radar
 SG_ VID_Obj_01_StdD_dAng_longitude : 41|6@1+ (0.01,0) [0|0.62] "Unit_RadiaPerSecon"  Radar
 SG_ VID_Obj_01_dAng_longitude : 47|9@1+ (0.005,-1.25) [-1.25|1.3] "Unit_RadiaPerSecon"  Radar
 SG_ VID_Obj_01_StdD_Ang_Width : 56|8@1+ (0.0009765625,0) [0|0.248046875] "Unit_Radia"  Radar

BO_ 898 VID_Obj_01_C: 8 MPC2
 SG_ VID_Obj_01_C_ChkSum : 0|8@1+ (1,0) [0|255] ""  Radar
 SG_ VID_Obj_01_C_MsgCnt : 8|4@1+ (1,0) [0|15] ""  Radar
 SG_ VID_Obj_01_C_BlockCnt : 12|4@1+ (1,0) [0|15] ""  Radar
 SG_ VID_Obj_01_InvTTC : 16|10@1+ (0.015625,-8) [-8|7.96875] "Unit_Hertz"  Radar
 SG_ VID_Obj_01_StdD_InvTTC : 26|7@1+ (0.0625,0) [0|7.875] "Unit_Hertz"  Radar
 SG_ VID_Obj_01_Ang_Overlap_EgoLane_R : 33|9@1+ (0.0009765625,-0.25) [-0.25|0.248046875] "Unit_Radia"  Radar
 SG_ VID_Obj_01_Ang_Overlap_EgoLane_L : 42|9@1+ (0.0009765625,-0.25) [-0.25|0.248046875] "Unit_Radia"  Radar
 SG_ VID_Obj_01_Obj_Age : 51|12@1+ (1,0) [0|4094] ""  Radar
 SG_ VID_Obj_01_BrakeLight : 63|1@1+ (1,0) [0|1] ""  Radar

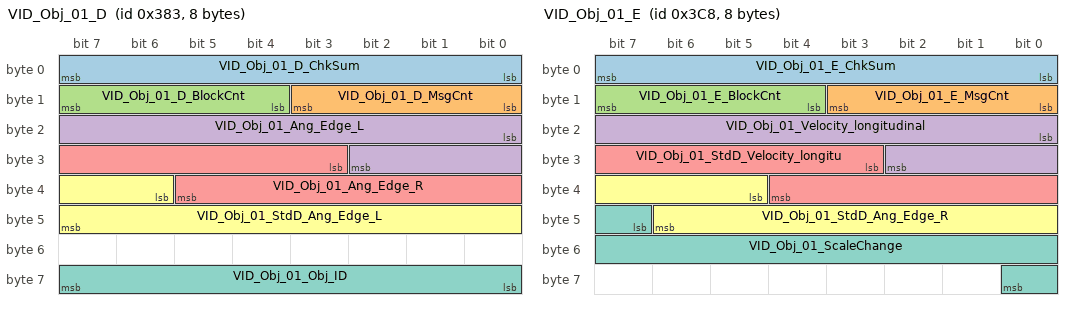
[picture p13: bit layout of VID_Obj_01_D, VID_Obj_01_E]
BO_ 899 VID_Obj_01_D: 8 MPC2
 SG_ VID_Obj_01_D_ChkSum : 0|8@1+ (1,0) [0|255] ""  Radar
 SG_ VID_Obj_01_D_MsgCnt : 8|4@1+ (1,0) [0|15] ""  Radar
 SG_ VID_Obj_01_D_BlockCnt : 12|4@1+ (1,0) [0|15] ""  Radar
 SG_ VID_Obj_01_Ang_Edge_L : 16|11@1+ (0.00048828125,-0.5) [-0.5|0.49951171875] "Unit_Radia"  Radar
 SG_ VID_Obj_01_Ang_Edge_R : 27|11@1+ (0.00048828125,-0.5) [-0.5|0.49951171875] "Unit_Radia"  Radar
 SG_ VID_Obj_01_StdD_Ang_Edge_L : 38|10@1+ (0.00048828125,-0.25) [-0.25|0.24951171875] "Unit_Radia"  Radar
 SG_ VID_Obj_01_Obj_ID : 56|8@1+ (1,0) [1|254] ""  Radar

BO_ 968 VID_Obj_01_E: 8 MPC2
 SG_ VID_Obj_01_E_ChkSum : 0|8@1+ (1,0) [0|255] ""  Radar
 SG_ VID_Obj_01_E_MsgCnt : 8|4@1+ (1,0) [0|15] ""  Radar
 SG_ VID_Obj_01_E_BlockCnt : 12|4@1+ (1,0) [0|15] ""  Radar
 SG_ VID_Obj_01_Velocity_longitudinal : 16|11@1+ (0.01388889,-12) [-12|12.00000192] "Unit_MeterPerSecon"  Radar
 SG_ VID_Obj_01_StdD_Velocity_longitu : 27|10@1+ (0.00694444,0) [0|6.0069406] "Unit_MeterPerSecon"  Radar
 SG_ VID_Obj_01_StdD_Ang_Edge_R : 37|10@1+ (0.00048828125,-0.25) [-0.25|0.24951171875] "Unit_Radia"  Radar
 SG_ VID_Obj_01_ScaleChange : 47|10@1+ (0.001,0.5) [0.5|1.5] ""  Radar

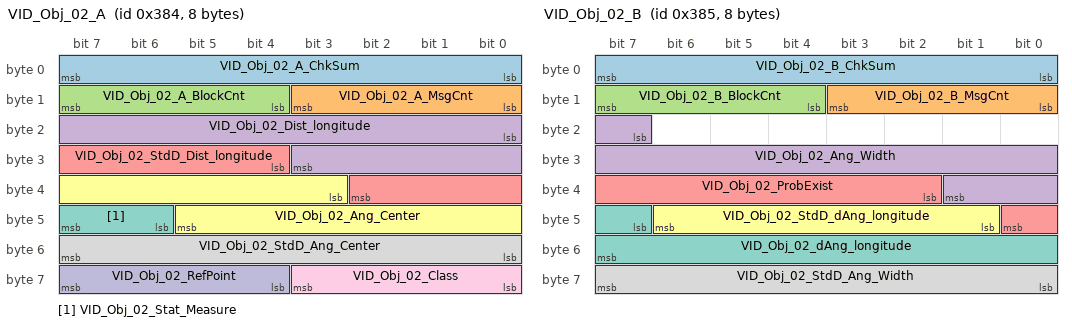
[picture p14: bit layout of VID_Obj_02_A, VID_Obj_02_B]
BO_ 900 VID_Obj_02_A: 8 MPC2
 SG_ VID_Obj_02_A_ChkSum : 0|8@1+ (1,0) [0|255] ""  Radar
 SG_ VID_Obj_02_A_MsgCnt : 8|4@1+ (1,0) [0|15] ""  Radar
 SG_ VID_Obj_02_A_BlockCnt : 12|4@1+ (1,0) [0|15] ""  Radar
 SG_ VID_Obj_02_Dist_longitude : 16|12@1+ (0.0625,0) [0|255.875] "Unit_Meter"  Radar
 SG_ VID_Obj_02_StdD_Dist_longitude : 28|7@1+ (0.25,0) [0|31.5] "Unit_Meter"  Radar
 SG_ VID_Obj_02_Ang_Center : 35|11@1+ (0.00048828125,-0.5) [-0.5|0.4990234375] "Unit_Radia"  Radar
 SG_ VID_Obj_02_Stat_Measure : 46|2@1+ (1,0) [0|3] ""  Radar
 SG_ VID_Obj_02_StdD_Ang_Center : 48|8@1+ (0.0009765625,0) [0|0.248046875] "Unit_Radia"  Radar
 SG_ VID_Obj_02_Class : 56|4@1+ (1,0) [0|15] ""  Radar
 SG_ VID_Obj_02_RefPoint : 60|4@1+ (1,0) [0|15] ""  Radar

BO_ 901 VID_Obj_02_B: 8 MPC2
 SG_ VID_Obj_02_B_ChkSum : 0|8@1+ (1,0) [0|255] ""  Radar
 SG_ VID_Obj_02_B_MsgCnt : 8|4@1+ (1,0) [0|15] ""  Radar
 SG_ VID_Obj_02_B_BlockCnt : 12|4@1+ (1,0) [0|15] ""  Radar
 SG_ VID_Obj_02_Ang_Width : 23|11@1+ (0.00048828125,0) [0|0.9990234375] "Unit_Radia"  Radar
 SG_ VID_Obj_02_ProbExist : 34|7@1+ (0.0078125,0.015625) [0.015625|1] ""  Radar
 SG_ VID_Obj_02_StdD_dAng_longitude : 41|6@1+ (0.01,0) [0|0.62] "Unit_RadiaPerSecon"  Radar
 SG_ VID_Obj_02_dAng_longitude : 47|9@1+ (0.005,-1.25) [-1.25|1.3] "Unit_RadiaPerSecon"  Radar
 SG_ VID_Obj_02_StdD_Ang_Width : 56|8@1+ (0.0009765625,0) [0|0.248046875] "Unit_Radia"  Radar

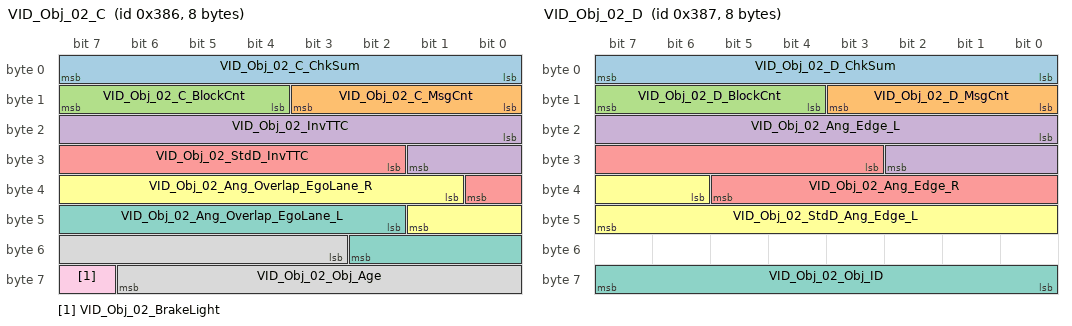
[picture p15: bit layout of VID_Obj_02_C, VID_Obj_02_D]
BO_ 902 VID_Obj_02_C: 8 MPC2
 SG_ VID_Obj_02_C_ChkSum : 0|8@1+ (1,0) [0|255] ""  Radar
 SG_ VID_Obj_02_C_MsgCnt : 8|4@1+ (1,0) [0|15] ""  Radar
 SG_ VID_Obj_02_C_BlockCnt : 12|4@1+ (1,0) [0|15] ""  Radar
 SG_ VID_Obj_02_InvTTC : 16|10@1+ (0.015625,-8) [-8|7.96875] "Unit_Hertz"  Radar
 SG_ VID_Obj_02_StdD_InvTTC : 26|7@1+ (0.0625,0) [0|7.875] "Unit_Hertz"  Radar
 SG_ VID_Obj_02_Ang_Overlap_EgoLane_R : 33|9@1+ (0.0009765625,-0.25) [-0.25|0.248046875] "Unit_Radia"  Radar
 SG_ VID_Obj_02_Ang_Overlap_EgoLane_L : 42|9@1+ (0.0009765625,-0.25) [-0.25|0.248046875] "Unit_Radia"  Radar
 SG_ VID_Obj_02_Obj_Age : 51|12@1+ (1,0) [0|4094] ""  Radar
 SG_ VID_Obj_02_BrakeLight : 63|1@1+ (1,0) [0|1] ""  Radar

BO_ 903 VID_Obj_02_D: 8 MPC2
 SG_ VID_Obj_02_D_ChkSum : 0|8@1+ (1,0) [0|255] ""  Radar
 SG_ VID_Obj_02_D_MsgCnt : 8|4@1+ (1,0) [0|15] ""  Radar
 SG_ VID_Obj_02_D_BlockCnt : 12|4@1+ (1,0) [0|15] ""  Radar
 SG_ VID_Obj_02_Ang_Edge_L : 16|11@1+ (0.00048828125,-0.5) [-0.5|0.49951171875] "Unit_Radia"  Radar
 SG_ VID_Obj_02_Ang_Edge_R : 27|11@1+ (0.00048828125,-0.5) [-0.5|0.49951171875] "Unit_Radia"  Radar
 SG_ VID_Obj_02_StdD_Ang_Edge_L : 38|10@1+ (0.00048828125,-0.25) [-0.25|0.24951171875] "Unit_Radia"  Radar
 SG_ VID_Obj_02_Obj_ID : 56|8@1+ (1,0) [1|254] ""  Radar

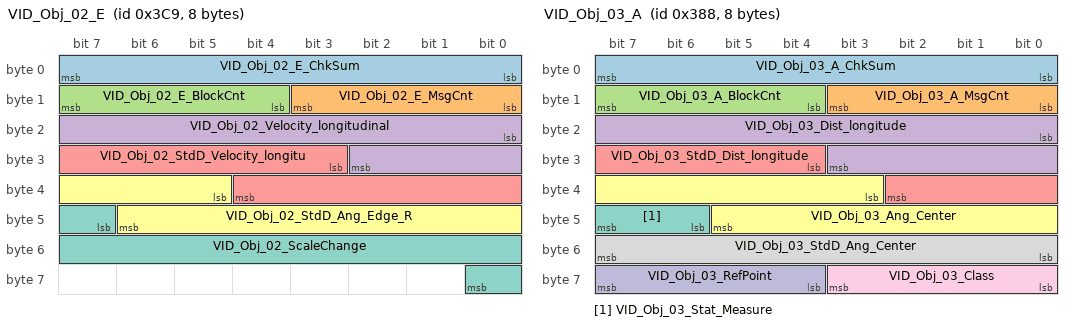
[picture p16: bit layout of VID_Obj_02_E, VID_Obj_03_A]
BO_ 969 VID_Obj_02_E: 8 MPC2
 SG_ VID_Obj_02_E_ChkSum : 0|8@1+ (1,0) [0|255] ""  Radar
 SG_ VID_Obj_02_E_MsgCnt : 8|4@1+ (1,0) [0|15] ""  Radar
 SG_ VID_Obj_02_E_BlockCnt : 12|4@1+ (1,0) [0|15] ""  Radar
 SG_ VID_Obj_02_Velocity_longitudinal : 16|11@1+ (0.01388889,-12) [-12|12.00000192] "Unit_MeterPerSecon"  Radar
 SG_ VID_Obj_02_StdD_Velocity_longitu : 27|10@1+ (0.00694444,0) [0|6.0069406] "Unit_MeterPerSecon"  Radar
 SG_ VID_Obj_02_StdD_Ang_Edge_R : 37|10@1+ (0.00048828125,-0.25) [-0.25|0.24951171875] "Unit_Radia"  Radar
 SG_ VID_Obj_02_ScaleChange : 47|10@1+ (0.001,0.5) [0.5|1.5] ""  Radar

BO_ 904 VID_Obj_03_A: 8 MPC2
 SG_ VID_Obj_03_A_ChkSum : 0|8@1+ (1,0) [0|255] ""  Radar
 SG_ VID_Obj_03_A_MsgCnt : 8|4@1+ (1,0) [0|15] ""  Radar
 SG_ VID_Obj_03_A_BlockCnt : 12|4@1+ (1,0) [0|15] ""  Radar
 SG_ VID_Obj_03_Dist_longitude : 16|12@1+ (0.0625,0) [0|255.875] "Unit_Meter"  Radar
 SG_ VID_Obj_03_StdD_Dist_longitude : 28|7@1+ (0.25,0) [0|31.5] "Unit_Meter"  Radar
 SG_ VID_Obj_03_Ang_Center : 35|11@1+ (0.00048828125,-0.5) [-0.5|0.4990234375] "Unit_Radia"  Radar
 SG_ VID_Obj_03_Stat_Measure : 46|2@1+ (1,0) [0|3] ""  Radar
 SG_ VID_Obj_03_StdD_Ang_Center : 48|8@1+ (0.0009765625,0) [0|0.248046875] "Unit_Radia"  Radar
 SG_ VID_Obj_03_Class : 56|4@1+ (1,0) [0|15] ""  Radar
 SG_ VID_Obj_03_RefPoint : 60|4@1+ (1,0) [0|15] ""  Radar

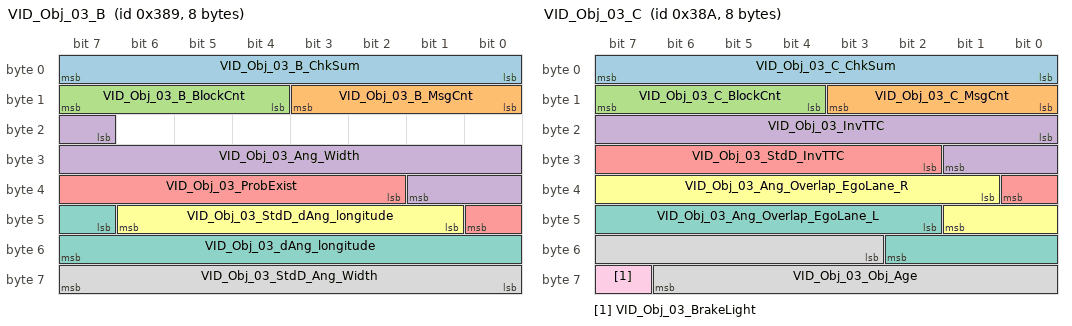
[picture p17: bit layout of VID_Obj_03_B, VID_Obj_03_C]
BO_ 905 VID_Obj_03_B: 8 MPC2
 SG_ VID_Obj_03_B_ChkSum : 0|8@1+ (1,0) [0|255] ""  Radar
 SG_ VID_Obj_03_B_MsgCnt : 8|4@1+ (1,0) [0|15] ""  Radar
 SG_ VID_Obj_03_B_BlockCnt : 12|4@1+ (1,0) [0|15] ""  Radar
 SG_ VID_Obj_03_Ang_Width : 23|11@1+ (0.00048828125,0) [0|0.9990234375] "Unit_Radia"  Radar
 SG_ VID_Obj_03_ProbExist : 34|7@1+ (0.0078125,0.015625) [0.015625|1] ""  Radar
 SG_ VID_Obj_03_StdD_dAng_longitude : 41|6@1+ (0.01,0) [0|0.62] "Unit_RadiaPerSecon"  Radar
 SG_ VID_Obj_03_dAng_longitude : 47|9@1+ (0.005,-1.25) [-1.25|1.3] "Unit_RadiaPerSecon"  Radar
 SG_ VID_Obj_03_StdD_Ang_Width : 56|8@1+ (0.0009765625,0) [0|0.248046875] "Unit_Radia"  Radar

BO_ 906 VID_Obj_03_C: 8 MPC2
 SG_ VID_Obj_03_C_ChkSum : 0|8@1+ (1,0) [0|255] ""  Radar
 SG_ VID_Obj_03_C_MsgCnt : 8|4@1+ (1,0) [0|15] ""  Radar
 SG_ VID_Obj_03_C_BlockCnt : 12|4@1+ (1,0) [0|15] ""  Radar
 SG_ VID_Obj_03_InvTTC : 16|10@1+ (0.015625,-8) [-8|7.96875] "Unit_Hertz"  Radar
 SG_ VID_Obj_03_StdD_InvTTC : 26|7@1+ (0.0625,0) [0|7.875] "Unit_Hertz"  Radar
 SG_ VID_Obj_03_Ang_Overlap_EgoLane_R : 33|9@1+ (0.0009765625,-0.25) [-0.25|0.248046875] "Unit_Radia"  Radar
 SG_ VID_Obj_03_Ang_Overlap_EgoLane_L : 42|9@1+ (0.0009765625,-0.25) [-0.25|0.248046875] "Unit_Radia"  Radar
 SG_ VID_Obj_03_Obj_Age : 51|12@1+ (1,0) [0|4094] ""  Radar
 SG_ VID_Obj_03_BrakeLight : 63|1@1+ (1,0) [0|1] ""  Radar

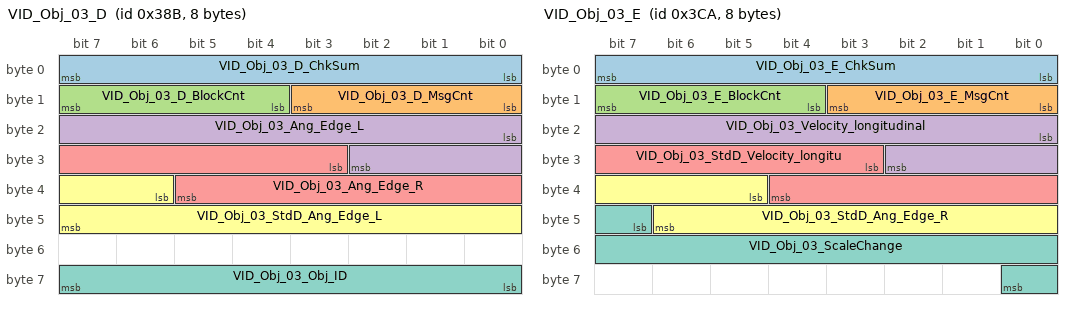
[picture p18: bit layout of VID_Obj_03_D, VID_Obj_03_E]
BO_ 907 VID_Obj_03_D: 8 MPC2
 SG_ VID_Obj_03_D_ChkSum : 0|8@1+ (1,0) [0|255] ""  Radar
 SG_ VID_Obj_03_D_MsgCnt : 8|4@1+ (1,0) [0|15] ""  Radar
 SG_ VID_Obj_03_D_BlockCnt : 12|4@1+ (1,0) [0|15] ""  Radar
 SG_ VID_Obj_03_Ang_Edge_L : 16|11@1+ (0.00048828125,-0.5) [-0.5|0.49951171875] "Unit_Radia"  Radar
 SG_ VID_Obj_03_Ang_Edge_R : 27|11@1+ (0.00048828125,-0.5) [-0.5|0.49951171875] "Unit_Radia"  Radar
 SG_ VID_Obj_03_StdD_Ang_Edge_L : 38|10@1+ (0.00048828125,-0.25) [-0.25|0.24951171875] "Unit_Radia"  Radar
 SG_ VID_Obj_03_Obj_ID : 56|8@1+ (1,0) [1|254] ""  Radar

BO_ 970 VID_Obj_03_E: 8 MPC2
 SG_ VID_Obj_03_E_ChkSum : 0|8@1+ (1,0) [0|255] ""  Radar
 SG_ VID_Obj_03_E_MsgCnt : 8|4@1+ (1,0) [0|15] ""  Radar
 SG_ VID_Obj_03_E_BlockCnt : 12|4@1+ (1,0) [0|15] ""  Radar
 SG_ VID_Obj_03_Velocity_longitudinal : 16|11@1+ (0.01388889,-12) [-12|12.00000192] "Unit_MeterPerSecon"  Radar
 SG_ VID_Obj_03_StdD_Velocity_longitu : 27|10@1+ (0.00694444,0) [0|6.0069406] "Unit_MeterPerSecon"  Radar
 SG_ VID_Obj_03_StdD_Ang_Edge_R : 37|10@1+ (0.00048828125,-0.25) [-0.25|0.24951171875] "Unit_Radia"  Radar
 SG_ VID_Obj_03_ScaleChange : 47|10@1+ (0.001,0.5) [0.5|1.5] ""  Radar

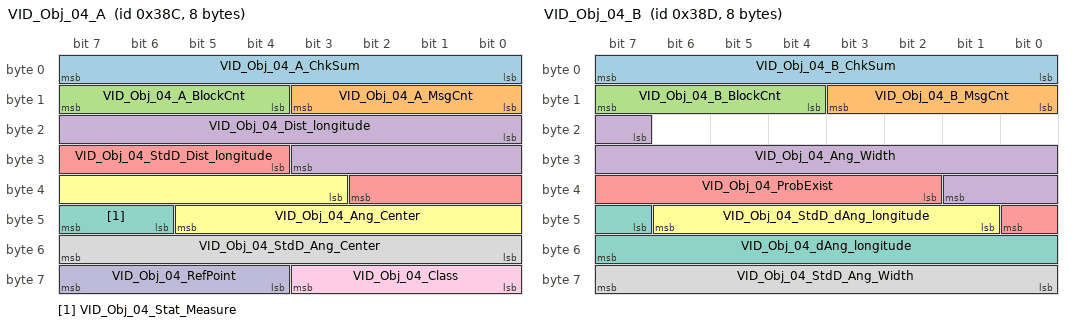
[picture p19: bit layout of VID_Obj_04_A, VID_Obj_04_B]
BO_ 908 VID_Obj_04_A: 8 MPC2
 SG_ VID_Obj_04_A_ChkSum : 0|8@1+ (1,0) [0|255] ""  Radar
 SG_ VID_Obj_04_A_MsgCnt : 8|4@1+ (1,0) [0|15] ""  Radar
 SG_ VID_Obj_04_A_BlockCnt : 12|4@1+ (1,0) [0|15] ""  Radar
 SG_ VID_Obj_04_Dist_longitude : 16|12@1+ (0.0625,0) [0|255.875] "Unit_Meter"  Radar
 SG_ VID_Obj_04_StdD_Dist_longitude : 28|7@1+ (0.25,0) [0|31.5] "Unit_Meter"  Radar
 SG_ VID_Obj_04_Ang_Center : 35|11@1+ (0.00048828125,-0.5) [-0.5|0.4990234375] "Unit_Radia"  Radar
 SG_ VID_Obj_04_Stat_Measure : 46|2@1+ (1,0) [0|3] ""  Radar
 SG_ VID_Obj_04_StdD_Ang_Center : 48|8@1+ (0.0009765625,0) [0|0.248046875] "Unit_Radia"  Radar
 SG_ VID_Obj_04_Class : 56|4@1+ (1,0) [0|15] ""  Radar
 SG_ VID_Obj_04_RefPoint : 60|4@1+ (1,0) [0|15] ""  Radar

BO_ 909 VID_Obj_04_B: 8 MPC2
 SG_ VID_Obj_04_B_ChkSum : 0|8@1+ (1,0) [0|255] ""  Radar
 SG_ VID_Obj_04_B_MsgCnt : 8|4@1+ (1,0) [0|15] ""  Radar
 SG_ VID_Obj_04_B_BlockCnt : 12|4@1+ (1,0) [0|15] ""  Radar
 SG_ VID_Obj_04_Ang_Width : 23|11@1+ (0.00048828125,0) [0|0.9990234375] "Unit_Radia"  Radar
 SG_ VID_Obj_04_ProbExist : 34|7@1+ (0.0078125,0.015625) [0.015625|1] ""  Radar
 SG_ VID_Obj_04_StdD_dAng_longitude : 41|6@1+ (0.01,0) [0|0.62] "Unit_RadiaPerSecon"  Radar
 SG_ VID_Obj_04_dAng_longitude : 47|9@1+ (0.005,-1.25) [-1.25|1.3] "Unit_RadiaPerSecon"  Radar
 SG_ VID_Obj_04_StdD_Ang_Width : 56|8@1+ (0.0009765625,0) [0|0.248046875] "Unit_Radia"  Radar

CM_ "MRR_MPC2xx_FusionCan";
CM_ BU_ Radar "Front Radar ECU (MRR1.5)";
CM_ BU_ MPC2 "Video ECU (MPC2 Premium/Plus)";
CM_ SG_ 855 RDR_Obj_07_vx_v " Relative velocity in longitudinal direction (dx) relative to the ego vehicle trajectory and the detected 3D-object block ";
CM_ SG_ 855 RDR_Obj_07_RFF "ID of the video object that has been fused with the current object";
CM_ SG_ 855 RDR_Obj_07_Obj_Obj_ID "Object/Track ID (internal)";
CM_ SG_ 855 RDR_Obj_07_MsgCnt "Message counter (rolling counter)";
CM_ SG_ 855 RDR_Obj_07_dy_v "Lateral distance (dy) relative to the ego vehicle trajectory and the detected 3D-object block";
CM_ SG_ 855 RDR_Obj_07_dx_v "Longitudinal distance (dx) relative to the ego vehicle trajectory and the detected 3D-object block";
CM_ SG_ 855 RDR_Obj_07_ChkSum "CRC8 Checksum";
CM_ SG_ 855 RDR_Obj_07_BlockCnt "Control signal to synchronize segmented blocks of object data";
CM_ SG_ 854 RDR_Obj_06_vx_v "Relative velocity in longitudinal direction (dx) relative to the ego vehicle trajectory and the detected 3D-object block 
";
CM_ SG_ 854 RDR_Obj_06_RFF "ID of the video object that has been fused with the current object";
CM_ SG_ 854 RDR_Obj_06_Obj_Obj_ID "Object/Track ID (internal)";
CM_ SG_ 854 RDR_Obj_06_MsgCnt "Message counter (rolling counter)";
CM_ SG_ 854 RDR_Obj_06_dy_v "Lateral distance (dy) relative to the ego vehicle trajectory and the detected 3D-object block";
CM_ SG_ 854 RDR_Obj_06_dx_v "Longitudinal distance (dx) relative to the ego vehicle trajectory and the detected 3D-object block";
CM_ SG_ 854 RDR_Obj_06_ChkSum "CRC8 Checksum";
CM_ SG_ 854 RDR_Obj_06_BlockCnt "Control signal to synchronize segmented blocks of object data";
CM_ SG_ 853 RDR_Obj_05_vx_v "Relative velocity in longitudinal direction (dx) relative to the ego vehicle trajectory and the detected 3D-object block ";
CM_ SG_ 853 RDR_Obj_05_RFF "ID of the video object that has been fused with the current object";
CM_ SG_ 853 RDR_Obj_05_Obj_Obj_ID "Object/Track ID (internal)";
CM_ SG_ 853 RDR_Obj_05_MsgCnt "Message counter (rolling counter)";
CM_ SG_ 853 RDR_Obj_05_dy_v "Lateral distance (dy) relative to the ego vehicle trajectory and the detected 3D-object block";
CM_ SG_ 853 RDR_Obj_05_dx_v "Longitudinal distance (dx) relative to the ego vehicle trajectory and the detected 3D-object block";
CM_ SG_ 853 RDR_Obj_05_ChkSum "CRC8 Checksum";
CM_ SG_ 853 RDR_Obj_05_BlockCnt "Control signal to synchronize segmented blocks of object data";
CM_ SG_ 2281601536 ImgFrameCounter "Zugriff auf den aktuellen Bildzähler vom OMAP aus (HAL-Funktion).";
CM_ BO_ 2617145883 "sumo kruemmung und kruemmung änderung";
CM_ SG_ 2617145883 BV_Sumo_ver_Kruemm_Aend "sumo kruemmung aenderung (per square meter)";
CM_ SG_ 2617145883 BV_Sumo_ver_Kruemm "sumo kruemmung (per meter)";
CM_ SG_ 770 VID_Stat2_MsgCnt "Message counter (rolling counter)";
CM_ SG_ 770 VID_Stat2_ChkSum "CRC8 Checksum";
CM_ SG_ 770 VID_Stat2_Camera_State "Operation State of the Camera";
CM_ SG_ 256 FRS_ALOD_ControlType "The type of the automatic longitude driving";
CM_ SG_ 257 CrDrLeInnrAblockCtr "Block counter for synchronisation
";
CM_ SG_ 257 CrDrLeInnrACRC "CRC
";
CM_ SG_ 257 CrDrLeInnrAMsgCtr "Alive Counter
";
CM_ SG_ 257 CrDrLeInnrCurvature "Inner curvature of the predicted corridor on left side
";
CM_ SG_ 257 CrDrLeInnrCurvChange "Inner curvature change of the predicted corridor on left side
";
CM_ SG_ 257 CrDrLeInnrdxEnd "Inner curvature lateral position of the predicted corridor on left side
";
CM_ SG_ 258 CrDrLeInnr_existence_prob "Existance probability of the predicted inner corridor on left side
";
CM_ SG_ 258 CrDrLeInnrBblockCtr "Block counter for synchronisation
";
CM_ SG_ 258 CrDrLeInnrBCRC "CRC
";
CM_ SG_ 258 CrDrLeInnrBMsgCtr "Alive Counter
";
CM_ SG_ 258 CrDrLeInnrdy "Inner curvature longitudinal position on left side
";
CM_ SG_ 258 CrDrLeInnrYawAngleDiff "Yaw angle difference of inner corridor with reference to vehicle position on left side
";
CM_ SG_ 259 CrDrLeOutrAblockCtr "Block counter for synchronisation
";
CM_ SG_ 259 CrDrLeOutrACRC "CRC
";
CM_ SG_ 259 CrDrLeOutrAMsgCtr "Alive Counter
";
CM_ SG_ 259 CrDrLeOutrCurvature "Outer curvature of the predicted corridor on left side
";
CM_ SG_ 259 CrDrLeOutrCurvChange "Outer curvature change of the predicted corridor on left side
";
CM_ SG_ 259 CrDrLeOutrdxEnd "Outer curvature lateral position of the predicted corridor on left side
";
CM_ SG_ 260 CrDrLeOutr_existence_prob "Existance probability of the predicted inner corridor on left side
";
CM_ SG_ 260 CrDrLeOutrBblockCtr "Block counter for synchronisation
";
CM_ SG_ 260 CrDrLeOutrBCRC "CRC
";
CM_ SG_ 260 CrDrLeOutrBMsgCtr "Alive Counter
";
CM_ SG_ 260 CrDrLeOutrdy "Outer curvature longitudinal position
";
CM_ SG_ 260 CrDrLeOutrYawAngleDiff "Yaw angle difference of Outer corridor with reference to vehicle position on left side
";
CM_ SG_ 261 CrDrRiInnrAblockCtr "Block counter for synchronisation
";
CM_ SG_ 261 CrDrRiInnrACRC "CRC
";
CM_ SG_ 261 CrDrRiInnrAMsgCtr "Alive Counter
";
CM_ SG_ 261 CrDrRiInnrCurvature "Inner curvature of the predicted corridor on right side
";
CM_ SG_ 261 CrDrRiInnrdxEnd "Inner curvature lateral position of the predicted corridor on right side
";
CM_ SG_ 262 CrDrRiInnr_existence_prob "Existance probability of the predicted inner corridor on right side
";
CM_ SG_ 262 CrDrRiInnrBblockCtr "Block counter for synchronisation
";
CM_ SG_ 262 CrDrRiInnrBCRC "CRC
";
CM_ SG_ 262 CrDrRiInnrBMsgCtr "Alive Counter
";
CM_ SG_ 262 CrDrRiInnrdy "Inner curvature longitudinal position on right side
";
CM_ SG_ 262 CrDrRiInnrYawAngleDiff "Yaw angle difference of inner corridor with reference to vehicle position on right
";
CM_ SG_ 263 CrDrRiOutrAblockCtr "Block counter for synchronisation
";
CM_ SG_ 263 CrDrRiOutrACRC "CRC
";
CM_ SG_ 263 CrDrRiOutrAMsgCtr "Alive Counter
";
CM_ SG_ 263 CrDrRiOutrCurvature "Outer curvature of the predicted corridor on right side
";
CM_ SG_ 263 CrDrRiOutrCurvChange "Outer curvature change of the predicted corridor on right side
";
CM_ SG_ 263 CrDrRiOutrdxEnd "Outer curvature lateral position of the predicted corridor on left side
";
CM_ SG_ 264 CrDrRiOutr_existence_prob "Existance probability of the predicted inner corridor on right side
";
CM_ SG_ 264 CrDrRiOutrBblockCtr "Block counter for synchronisation
";
CM_ SG_ 264 CrDrRiOutrBCRC "CRC
";
CM_ SG_ 264 CrDrRiOutrBMsgCtr "Alive Counter
";
CM_ SG_ 264 CrDrRiOutrdy "Outer curvature longitudinal position on right side
";
CM_ SG_ 264 CrDrRiOutrYawAngleDiff "Yaw angle difference of Outer corridor with reference to vehicle position on right side
";
CM_ SG_ 265 TargetTrajAblockCtr "Block counter for synchronisation
";
CM_ SG_ 265 TargetTrajACRC "Check Sum
";
CM_ SG_ 265 TargetTrajAMsgCtr "Alive counter
";
CM_ SG_ 265 TargetTrajCurvChange "Change in curvature of the target trajectory
";
CM_ SG_ 265 TargetTrajCurv "Target Trajectory Curvature
";
CM_ SG_ 266 TargetTrajBblockCtr "Block counter for synchronisation
";
CM_ SG_ 266 TargetTrajBCRC "Check Sum
";
CM_ SG_ 266 TargetTrajBMsgCtr "Alive counter
";
CM_ SG_ 266 TargetTrajExistnceProb "Existance Probability of the determined target trajectory
";
CM_ SG_ 266 TargetTrajYawAngleDiff "Yaw Angle difference of the Target Trajectory
";
CM_ SG_ 769 VID_Stat_ChkSum "CRC8 Checksum";
CM_ SG_ 769 VID_Stat_MsgCnt "Message counter (rolling counter)";
CM_ SG_ 769 VID_Stat_BlockCnt "Control signal to synchronize segmented blocks of object data";
CM_ SG_ 769 VID_Stat_ObjDataAge "Time differece between middle of measurement and broadcast on the vehicle bus";
CM_ SG_ 769 VID_Stat_Upd_Cnt "Update counter for Object and Line data";
CM_ SG_ 769 VID_Stat_Intruder "Bit is set if any object enters the monitored area (lane in front of the vehicle)";
CM_ SG_ 769 VID_LDA_Counter "Counter that represents the analyzed frame (encoded) for LDA";
CM_ SG_ 769 VID_Stat_MOD_Cnt "Counter that represents the analyzed frame (encoded) for LDA";
CM_ SG_ 769 VID_Stat_PED_Warning "System status for pedestrian warning";
CM_ SG_ 769 VID_Stat_RFD_notAvail "Intruder detection is temporary not available";
CM_ SG_ 769 VID_Stat_PED_Config "System configuration for PED protection (predictive protection)";
CM_ SG_ 769 VID_Stat_LaneDataAge "Time differece between middle of measurement and broadcast on the vehicle bus";
CM_ SG_ 769 VID_Stat_blindness_det "Blindness detection: Blindness was detected after freesight has been detected earlier";
CM_ SG_ 769 VID_Stat_Freesight_nOK "Blindness detection: Freesight has not been detected yet (after KL15 cycle)
Nach KL15-Ein konnte Freisichtprüfung noch nicht erfüllt werden";
CM_ SG_ 769 VID_Stat_Error "VideoSGU has detected an error with pending DTC";
CM_ SG_ 769 VID_Stat_NotAvail "VideoSGU has detected a temporary non availability without pending DTC";
CM_ SG_ 832 VID_Lin_01_A_ChkSum "CRC8 Checksum";
CM_ SG_ 832 VID_Lin_01_A_MsgCnt "Message counter (rolling counter)";
CM_ SG_ 832 VID_Lin_01_A_BlockCnt "Control signal to synchronize segmented blocks of object data";
CM_ SG_ 832 VID_Lin_01_dx_Start "Longitudinal distance (dx) to center of vehicle coordinate system";
CM_ SG_ 832 VID_Lin_01_dx_Lookahead "Longitudinal distance (dx) of the last measurement sample, Phys. output '0 m' if vehicle has already crossed the start of the line";
CM_ SG_ 832 VID_Lin_01_dy "Lateral distance (dy) to center of vehicle coordinate system";
CM_ SG_ 832 VID_Lin_01_ProbExists "Probability of existance for a line (or marking)
Conversion factor 2^-6";
CM_ SG_ 832 VID_Lin_01_DiffYawAng "Angle between vehicle longitudinal axis (x) and the tangent on the starting point of the track
Conversion factor 2^-11";
CM_ SG_ 833 VID_Lin_01_B_ChkSum "CRC8 Checksum";
CM_ SG_ 833 VID_Lin_01_B_MsgCnt "Message counter (rolling counter)";
CM_ SG_ 833 VID_Lin_01_B_BlockCnt "Control signal to synchronize segmented blocks of object data";
CM_ SG_ 833 VID_Lin_01_hor_curve_change "change of the horizontal curvature of the line";
CM_ SG_ 833 VID_Lin_01_hor_curve "horizontal curvature of the line";
CM_ SG_ 833 VID_Lin_01_Line_Width "Width of the line.";
CM_ SG_ 833 VID_Lin_01_Line_ID "Left master line: Line ID (image processing)";
CM_ SG_ 833 VID_Lin_01_Line_Type "Style of the line";
CM_ SG_ 833 VID_Lin_01_Line_Colour "Colour of the line";
CM_ SG_ 835 VID_Lin_02_A_ChkSum "CRC8 Checksum";
CM_ SG_ 835 VID_Lin_02_A_MsgCnt "Message counter (rolling counter)";
CM_ SG_ 835 VID_Lin_02_A_BlockCnt "Control signal to synchronize segmented blocks of object data";
CM_ SG_ 835 VID_Lin_02_dx_Start "Longitudinal distance (dx) to center of vehicle coordinate system";
CM_ SG_ 835 VID_Lin_02_dx_Lookahead "Longitudinal distance (dx) of the last measurement sample, Phys. output '0 m' if vehicle has already crossed the start of the line";
CM_ SG_ 835 VID_Lin_02_dy "Lateral distance (dy) to center of vehicle coordinate system";
CM_ SG_ 835 VID_Lin_02_ProbExists "Probability of existance for a line (or marking)
Conversion factor 2^-6";
CM_ SG_ 835 VID_Lin_02_DiffYawAng "Angle between vehicle longitudinal axis (x) and the tangent on the starting point of the track
Conversion factor 2^-11";
CM_ SG_ 836 VID_Lin_02_B_ChkSum "CRC8 Checksum";
CM_ SG_ 836 VID_Lin_02_B_MsgCnt "Message counter (rolling counter)";
CM_ SG_ 836 VID_Lin_02_B_BlockCnt "Control signal to synchronize segmented blocks of object data";
CM_ SG_ 836 VID_Lin_02_hor_curve_change "change of the horizontal curvature of the line";
CM_ SG_ 836 VID_Lin_02_hor_curve "horizontal curvature of the line";
CM_ SG_ 836 VID_Lin_02_Line_Width "Width of the line.";
CM_ SG_ 836 VID_Lin_02_Line_ID "Right master line: Line ID (image processing)";
CM_ SG_ 836 VID_Lin_02_Line_Type "Style of the line";
CM_ SG_ 836 VID_Lin_02_Line_Colour "Colour of the line";
CM_ SG_ 838 VID_Lin_03_A_ChkSum "CRC8 Checksum";
CM_ SG_ 838 VID_Lin_03_A_MsgCnt "Message counter (rolling counter)";
CM_ SG_ 838 VID_Lin_03_A_BlockCnt "Control signal to synchronize segmented blocks of object data";
CM_ SG_ 838 VID_Lin_03_dx_Start "Longitudinal distance (dx) to center of vehicle coordinate system";
CM_ SG_ 838 VID_Lin_03_dx_Lookahead "Longitudinal distance (dx) of the last measurement sample, Phys. output '0 m' if vehicle has already crossed the start of the line";
CM_ SG_ 838 VID_Lin_03_dy "Lateral distance (dy) to center of vehicle coordinate system";
CM_ SG_ 838 VID_Lin_03_ProbExists "Probability of existance for a line (or marking)
Conversion factor 2^-6";
CM_ SG_ 838 VID_Lin_03_DiffYawAng "Angle between vehicle longitudinal axis (x) and the tangent on the starting point of the track
Conversion factor 2^-11";
CM_ SG_ 839 VID_Lin_03_B_ChkSum "CRC8 Checksum";
CM_ SG_ 839 VID_Lin_03_B_MsgCnt "Message counter (rolling counter)";
CM_ SG_ 839 VID_Lin_03_B_BlockCnt "Control signal to synchronize segmented blocks of object data";
CM_ SG_ 839 VID_Lin_03_hor_curve_change "change of the horizontal curvature of the line";
CM_ SG_ 839 VID_Lin_03_hor_curve "horizontal curvature of the line
Multiplikation des Rohwerts mit 2^-16";
CM_ SG_ 839 VID_Lin_03_Line_Width "Width of the line.";
CM_ SG_ 839 VID_Lin_03_Line_ID "Line ID (image processing)";
CM_ SG_ 839 VID_Lin_03_Line_Type "Style of the line";
CM_ SG_ 839 VID_Lin_03_Line_Colour "Colour of the line";
CM_ SG_ 841 VID_Lin_04_A_ChkSum "CRC8 Checksum";
CM_ SG_ 841 VID_Lin_04_A_MsgCnt "Message counter (rolling counter)";
CM_ SG_ 841 VID_Lin_04_A_BlockCnt "Control signal to synchronize segmented blocks of object data";
CM_ SG_ 841 VID_Lin_04_dx_Start "Longitudinal distance (dx) to center of vehicle coordinate system";
CM_ SG_ 841 VID_Lin_04_dx_Lookahead "Longitudinal distance (dx) of the last measurement sample, Phys. output '0 m' if vehicle has already crossed the start of the line";
CM_ SG_ 841 VID_Lin_04_dy "Lateral distance (dy) to center of vehicle coordinate system";
CM_ SG_ 841 VID_Lin_04_ProbExists "Probability of existance for a line (or marking)
Conversion factor 2^-6";
CM_ SG_ 841 VID_Lin_04_DiffYawAng "Angle between vehicle longitudinal axis (x) and the tangent on the starting point of the track
Conversion factor 2^-11";
CM_ SG_ 842 VID_Lin_04_B_ChkSum "CRC8 Checksum";
CM_ SG_ 842 VID_Lin_04_B_MsgCnt "Message counter (rolling counter)";
CM_ SG_ 842 VID_Lin_04_B_BlockCnt "Control signal to synchronize segmented blocks of object data";
CM_ SG_ 842 VID_Lin_04_hor_curve_change "change of the horizontal curvature of the line";
CM_ SG_ 842 VID_Lin_04_hor_curve "horizontal curvature of the line";
CM_ SG_ 842 VID_Lin_04_Line_Width "Width of the line.";
CM_ SG_ 842 VID_Lin_04_Line_ID "Line ID (image processing)";
CM_ SG_ 842 VID_Lin_04_Line_Type "Style of the line";
CM_ SG_ 842 VID_Lin_04_Line_Colour "Colour of the line";
CM_ SG_ 1385 VID_MountPos_MsgCnt "Message counter (rolling counter)";
CM_ SG_ 1385 VID_MountPos_ChkSum "CRC8 Checksum";
CM_ SG_ 1385 VID_MountPos_x "Camera position in coordinate system (Vehicle mesh position). 
- x-coordinates of the optical camera focus point
- Conversion factor 2base: 2^-10";
CM_ SG_ 1385 VID_MountPos_y "Camera position in coordinate system (Vehicle mesh position). 
- y-coordinates of the optical camera focus point
- Conversion factor 2base: 2^-10";
CM_ SG_ 1385 VID_MountPos_z "Camera position in coordinate system (Vehicle mesh position). 
- z-coordinates of the optical camera focus point
- Conversion factor 2base: 2^-10";
CM_ SG_ 896 VID_Obj_01_A_ChkSum "CRC8 Checksum";
CM_ SG_ 896 VID_Obj_01_A_MsgCnt "Message counter (rolling counter)";
CM_ SG_ 896 VID_Obj_01_A_BlockCnt "Control signal to synchronize segmented blocks of object data";
CM_ SG_ 896 VID_Obj_01_Dist_longitude "Longitudinal distance relative to vehicle coordinate system";
CM_ SG_ 896 VID_Obj_01_StdD_Dist_longitude "Standard deviation for VID_Obj_01_Dist_longitude";
CM_ SG_ 896 VID_Obj_01_Ang_Center "Center of the recorded side of the 3D-object box (positive angle left of x-axis).
(Mono-Video: Rear view for vehicles). In combination with Obj_Angle_low the center
base point of the objectis described.
Coordinate system: transformed";
CM_ SG_ 896 VID_Obj_01_Stat_Measure "Object measured tracked

0 Object not measured but predicted based on 3D-model
1 Object was measured in current sample cycle
2 Object not measured but re-matched based on feature tracking";
CM_ SG_ 896 VID_Obj_01_StdD_Ang_Center "Standard deviation for VID_Obj_01_Ang_Center";
CM_ SG_ 896 VID_Obj_01_Class "Object class";
CM_ SG_ 896 VID_Obj_01_RefPoint "Index of the reference point for the 3D-object box
Info: The wording front/rear right/left relates to the indicated object orientation.
If this data is not available then a orienntation can be chosen.";
CM_ SG_ 897 VID_Obj_01_B_ChkSum "CRC8 Checksum";
CM_ SG_ 897 VID_Obj_01_B_MsgCnt "Message counter (rolling counter)";
CM_ SG_ 897 VID_Obj_01_B_BlockCnt "Control signal to synchronize segmented blocks of object data";
CM_ SG_ 897 VID_Obj_01_Ang_Width "Width of the recorded side of the 3D-object box (positive angle left of x-axis)
Monovideo: Rear view for vehicles
Coordinate system: Transformed coordinate system with camera being origin
! Ego-movement has to be compensated !";
CM_ SG_ 897 VID_Obj_01_ProbExist "Probability for the existence of an object for the given time and position (in 3sigma-area)";
CM_ SG_ 897 VID_Obj_01_StdD_dAng_longitude "Standard deviation for VID_Obj_01_dAng_longitude";
CM_ SG_ 897 VID_Obj_01_dAng_longitude "Lateral velocity of the object (related to the reference point), calculated as change of angle in the frame";
CM_ SG_ 897 VID_Obj_01_StdD_Ang_Width "Standard deviation for VID_Obj_01_Ang_Width";
CM_ SG_ 898 VID_Obj_01_C_ChkSum "CRC8 Checksum";
CM_ SG_ 898 VID_Obj_01_C_MsgCnt "Message counter (rolling counter)";
CM_ SG_ 898 VID_Obj_01_C_BlockCnt "Control signal to synchronize segmented blocks of object data";
CM_ SG_ 898 VID_Obj_01_InvTTC "Inverted value of the time-to-collision with the vertical plane of the camera ";
CM_ SG_ 898 VID_Obj_01_StdD_InvTTC "Standard deviation for VID_Obj_01_InvTTC";
CM_ SG_ 898 VID_Obj_01_Ang_Overlap_EgoLane_R "Object Line Assignment (angle based indicator for the overlap of a an object with the ego lane from the right corner)";
CM_ SG_ 898 VID_Obj_01_Ang_Overlap_EgoLane_L "Object Line Assignment (angle based indicator for the overlap of a an object with the ego lane from the left corner)";
CM_ SG_ 898 VID_Obj_01_Obj_Age "Cycle counter for the existence of the object (object sampled)";
CM_ SG_ 898 VID_Obj_01_BrakeLight "Brake light recognized on the object";
CM_ SG_ 899 VID_Obj_01_D_ChkSum "CRC8 Checksum";
CM_ SG_ 899 VID_Obj_01_D_MsgCnt "Message counter (rolling counter)";
CM_ SG_ 899 VID_Obj_01_D_BlockCnt "Control signal to synchronize segmented blocks of object data";
CM_ SG_ 899 VID_Obj_01_Ang_Edge_L "Angle of the left edge of the object
Conversion factor 2^-11";
CM_ SG_ 899 VID_Obj_01_Ang_Edge_R "Angle of the right edge of the object
Conversion factor 2^-11";
CM_ SG_ 899 VID_Obj_01_StdD_Ang_Edge_L "Standard deviation for the Angle of the left edge of the object";
CM_ SG_ 899 VID_Obj_01_Obj_ID "ID of the object";
CM_ SG_ 968 VID_Obj_01_E_ChkSum "CRC8 Checksum";
CM_ SG_ 968 VID_Obj_01_E_MsgCnt "Message counter (rolling counter)";
CM_ SG_ 968 VID_Obj_01_E_BlockCnt "Control signal to synchronize segmented blocks of object data";
CM_ SG_ 968 VID_Obj_01_Velocity_longitudinal "Longitudinal velocity of the detected object (Vehicle coordinate system)";
CM_ SG_ 968 VID_Obj_01_StdD_Velocity_longitu "Standard deviation of the Longitudinal velocity of the detected object (Vehicle coordinate system)";
CM_ SG_ 968 VID_Obj_01_StdD_Ang_Edge_R "Standard deviation for the Angle of the right edge of the object";
CM_ SG_ 968 VID_Obj_01_ScaleChange "In order to fuse a video object with a radar object at higher distance (>60m), a higher resolution for the  relative velocity is needed in that range. This signal indicates the required change of the scale.";
CM_ SG_ 900 VID_Obj_02_A_ChkSum "CRC8 Checksum";
CM_ SG_ 900 VID_Obj_02_A_MsgCnt "Message counter (rolling counter)";
CM_ SG_ 900 VID_Obj_02_A_BlockCnt "Control signal to synchronize segmented blocks of object data";
CM_ SG_ 900 VID_Obj_02_Dist_longitude "Longitudinal distance relative to vehicle coordinate system";
CM_ SG_ 900 VID_Obj_02_StdD_Dist_longitude "Standard deviation for VID_Obj_02_Dist_longitude";
CM_ SG_ 900 VID_Obj_02_Ang_Center "Center of the recorded side of the 3D-object box (positive angle left of x-axis).
(Mono-Video: Rear view for vehicles). In combination with Obj_Angle_low the center
base point of the objectis described.
Coordinate system: transformed";
CM_ SG_ 900 VID_Obj_02_Stat_Measure "Object measured tracked

0 Object not measured but predicted based on 3D-model
1 Object was measured in current sample cycle
2 Object not measured but re-matched based on feature tracking";
CM_ SG_ 900 VID_Obj_02_StdD_Ang_Center "Standard deviation for VID_Obj_02_Ang_Center";
CM_ SG_ 900 VID_Obj_02_Class "Object class";
CM_ SG_ 900 VID_Obj_02_RefPoint "Index of the reference point for the 3D-object box
Info: The wording front/rear right/left relates to the indicated object orientation.
If this data is not available then a orienntation can be chosen.";
CM_ SG_ 901 VID_Obj_02_B_ChkSum "CRC8 Checksum";
CM_ SG_ 901 VID_Obj_02_B_MsgCnt "Message counter (rolling counter)";
CM_ SG_ 901 VID_Obj_02_B_BlockCnt "Control signal to synchronize segmented blocks of object data";
CM_ SG_ 901 VID_Obj_02_Ang_Width "Width of the recorded side of the 3D-object box (positive angle left of x-axis)
Monovideo: Rear view for vehicles
Coordinate system: Transformed coordinate system with camera being origin
! Ego-movement has to be compensated !";
CM_ SG_ 901 VID_Obj_02_ProbExist "Probability for the existence of an object for the given time and position (in 3sigma-area)";
CM_ SG_ 901 VID_Obj_02_StdD_dAng_longitude "Standard deviation for VID_Obj_02_dAng_longitude";
CM_ SG_ 901 VID_Obj_02_dAng_longitude "Lateral velocity of the object (related to the reference point), calculated as change of angle in the frame";
CM_ SG_ 901 VID_Obj_02_StdD_Ang_Width "Standard deviation for VID_Obj_02_Ang_Width";
CM_ SG_ 902 VID_Obj_02_C_ChkSum "CRC8 Checksum";
CM_ SG_ 902 VID_Obj_02_C_MsgCnt "Message counter (rolling counter)";
CM_ SG_ 902 VID_Obj_02_C_BlockCnt "Control signal to synchronize segmented blocks of object data";
CM_ SG_ 902 VID_Obj_02_InvTTC "Inverted value of the time-to-collision with the vertical plane of the camera ";
CM_ SG_ 902 VID_Obj_02_StdD_InvTTC "Standard deviation for VID_Obj_02_InvTTC";
CM_ SG_ 902 VID_Obj_02_Ang_Overlap_EgoLane_R "Object Line Assignment (angle based indicator for the overlap of a an object with the ego lane from the right corner)";
CM_ SG_ 902 VID_Obj_02_Ang_Overlap_EgoLane_L "Object Line Assignment (angle based indicator for the overlap of a an object with the ego lane from the left corner)";
CM_ SG_ 902 VID_Obj_02_Obj_Age "Cycle counter for the existence of the object (object sampled)";
CM_ SG_ 902 VID_Obj_02_BrakeLight "Brake light recognized on the object";
CM_ SG_ 903 VID_Obj_02_D_ChkSum "CRC8 Checksum";
CM_ SG_ 903 VID_Obj_02_D_MsgCnt "Message counter (rolling counter)";
CM_ SG_ 903 VID_Obj_02_D_BlockCnt "Control signal to synchronize segmented blocks of object data";
CM_ SG_ 903 VID_Obj_02_Ang_Edge_L "Angle of the left edge of the object
Conversion factor 2^-11";
CM_ SG_ 903 VID_Obj_02_Ang_Edge_R "Angle of the right edge of the object
Conversion factor 2^-11";
CM_ SG_ 903 VID_Obj_02_StdD_Ang_Edge_L "Standard deviation for the Angle of the left edge of the object";
CM_ SG_ 903 VID_Obj_02_Obj_ID "ID of the object";
CM_ SG_ 969 VID_Obj_02_E_ChkSum "CRC8 Checksum";
CM_ SG_ 969 VID_Obj_02_E_MsgCnt "Message counter (rolling counter)";
CM_ SG_ 969 VID_Obj_02_E_BlockCnt "Control signal to synchronize segmented blocks of object data";
CM_ SG_ 969 VID_Obj_02_Velocity_longitudinal "Longitudinal velocity of the detected object (Vehicle coordinate system)";
CM_ SG_ 969 VID_Obj_02_StdD_Velocity_longitu "Standard deviation of the Longitudinal velocity of the detected object (Vehicle coordinate system)";
CM_ SG_ 969 VID_Obj_02_StdD_Ang_Edge_R "Standard deviation for the Angle of the right edge of the object";
CM_ SG_ 969 VID_Obj_02_ScaleChange "In order to fuse a video object with a radar object at higher distance (>60m), a higher resolution for the  relative velocity is needed in that range. This signal indicates the required change of the scale.";
CM_ SG_ 904 VID_Obj_03_A_ChkSum "CRC8 Checksum";
CM_ SG_ 904 VID_Obj_03_A_MsgCnt "Message counter (rolling counter)";
CM_ SG_ 904 VID_Obj_03_A_BlockCnt "Control signal to synchronize segmented blocks of object data";
CM_ SG_ 904 VID_Obj_03_Dist_longitude "Longitudinal distance relative to vehicle coordinate system";
CM_ SG_ 904 VID_Obj_03_StdD_Dist_longitude "Standard deviation for VID_Obj_03_Dist_longitude";
CM_ SG_ 904 VID_Obj_03_Ang_Center "Center of the recorded side of the 3D-object box (positive angle left of x-axis).
(Mono-Video: Rear view for vehicles). In combination with Obj_Angle_low the center
base point of the objectis described.
Coordinate system: transformed";
CM_ SG_ 904 VID_Obj_03_Stat_Measure "Object measured tracked

0 Object not measured but predicted based on 3D-model
1 Object was measured in current sample cycle
2 Object not measured but re-matched based on feature tracking";
CM_ SG_ 904 VID_Obj_03_StdD_Ang_Center "Standard deviation for VID_Obj_03_Ang_Center";
CM_ SG_ 904 VID_Obj_03_Class "Object class";
CM_ SG_ 904 VID_Obj_03_RefPoint "Index of the reference point for the 3D-object box
Info: The wording front/rear right/left relates to the indicated object orientation.
If this data is not available then a orienntation can be chosen.";
CM_ SG_ 905 VID_Obj_03_B_ChkSum "CRC8 Checksum";
CM_ SG_ 905 VID_Obj_03_B_MsgCnt "Message counter (rolling counter)";
CM_ SG_ 905 VID_Obj_03_B_BlockCnt "Control signal to synchronize segmented blocks of object data";
CM_ SG_ 905 VID_Obj_03_Ang_Width "Width of the recorded side of the 3D-object box (positive angle left of x-axis)
Monovideo: Rear view for vehicles
Coordinate system: Transformed coordinate system with camera being origin
! Ego-movement has to be compensated !";
CM_ SG_ 905 VID_Obj_03_ProbExist "Probability for the existence of an object for the given time and position (in 3sigma-area)";
CM_ SG_ 905 VID_Obj_03_StdD_dAng_longitude "Standard deviation for VID_Obj_03_dAng_longitude";
CM_ SG_ 905 VID_Obj_03_dAng_longitude "Lateral velocity of the object (related to the reference point), calculated as change of angle in the frame";
CM_ SG_ 905 VID_Obj_03_StdD_Ang_Width "Standard deviation for VID_Obj_03_Ang_Width";
CM_ SG_ 906 VID_Obj_03_C_ChkSum "CRC8 Checksum";
CM_ SG_ 906 VID_Obj_03_C_MsgCnt "Message counter (rolling counter)";
CM_ SG_ 906 VID_Obj_03_C_BlockCnt "Control signal to synchronize segmented blocks of object data";
CM_ SG_ 906 VID_Obj_03_InvTTC "Inverted value of the time-to-collision with the vertical plane of the camera ";
CM_ SG_ 906 VID_Obj_03_StdD_InvTTC "Standard deviation for VID_Obj_03_InvTTC";
CM_ SG_ 906 VID_Obj_03_Ang_Overlap_EgoLane_R "Object Line Assignment (angle based indicator for the overlap of a an object with the ego lane from the right corner)";
CM_ SG_ 906 VID_Obj_03_Ang_Overlap_EgoLane_L "Object Line Assignment (angle based indicator for the overlap of a an object with the ego lane from the left corner)";
CM_ SG_ 906 VID_Obj_03_Obj_Age "Cycle counter for the existence of the object (object sampled)";
CM_ SG_ 906 VID_Obj_03_BrakeLight "Brake light recognized on the object";
CM_ SG_ 907 VID_Obj_03_D_ChkSum "CRC8 Checksum";
CM_ SG_ 907 VID_Obj_03_D_MsgCnt "Message counter (rolling counter)";
CM_ SG_ 907 VID_Obj_03_D_BlockCnt "Control signal to synchronize segmented blocks of object data";
CM_ SG_ 907 VID_Obj_03_Ang_Edge_L "Angle of the left edge of the object
Conversion factor 2^-11";
CM_ SG_ 907 VID_Obj_03_Ang_Edge_R "Angle of the right edge of the object
Conversion factor 2^-11";
CM_ SG_ 907 VID_Obj_03_StdD_Ang_Edge_L "Standard deviation for the Angle of the left edge of the object";
CM_ SG_ 907 VID_Obj_03_Obj_ID "ID of the object";
CM_ SG_ 970 VID_Obj_03_E_ChkSum "CRC8 Checksum";
CM_ SG_ 970 VID_Obj_03_E_MsgCnt "Message counter (rolling counter)";
CM_ SG_ 970 VID_Obj_03_E_BlockCnt "Control signal to synchronize segmented blocks of object data";
CM_ SG_ 970 VID_Obj_03_Velocity_longitudinal "Longitudinal velocity of the detected object (Vehicle coordinate system)";
CM_ SG_ 970 VID_Obj_03_StdD_Velocity_longitu "Standard deviation of the Longitudinal velocity of the detected object (Vehicle coordinate system)";
CM_ SG_ 970 VID_Obj_03_StdD_Ang_Edge_R "Standard deviation for the Angle of the right edge of the object";
CM_ SG_ 970 VID_Obj_03_ScaleChange "In order to fuse a video object with a radar object at higher distance (>60m), a higher resolution for the  relative velocity is needed in that range. This signal indicates the required change of the scale.";
CM_ SG_ 908 VID_Obj_04_A_ChkSum "CRC8 Checksum";
CM_ SG_ 908 VID_Obj_04_A_MsgCnt "Message counter (rolling counter)";
CM_ SG_ 908 VID_Obj_04_A_BlockCnt "Control signal to synchronize segmented blocks of object data";
CM_ SG_ 908 VID_Obj_04_Dist_longitude "Longitudinal distance relative to vehicle coordinate system";
CM_ SG_ 908 VID_Obj_04_StdD_Dist_longitude "Standard deviation for VID_Obj_04_Dist_longitude";
CM_ SG_ 908 VID_Obj_04_Ang_Center "Center of the recorded side of the 3D-object box (positive angle left of x-axis).
(Mono-Video: Rear view for vehicles). In combination with Obj_Angle_low the center
base point of the objectis described.
Coordinate system: transformed";
CM_ SG_ 908 VID_Obj_04_Stat_Measure "Object measured tracked

0 Object not measured but predicted based on 3D-model
1 Object was measured in current sample cycle
2 Object not measured but re-matched based on feature tracking";
CM_ SG_ 908 VID_Obj_04_StdD_Ang_Center "Standard deviation for VID_Obj_04_Ang_Center";
CM_ SG_ 908 VID_Obj_04_Class "Object class";
CM_ SG_ 908 VID_Obj_04_RefPoint "Index of the reference point for the 3D-object box
Info: The wording front/rear right/left relates to the indicated object orientation.
If this data is not available then a orienntation can be chosen.";
CM_ SG_ 909 VID_Obj_04_B_ChkSum "CRC8 Checksum";
CM_ SG_ 909 VID_Obj_04_B_MsgCnt "Message counter (rolling counter)";
CM_ SG_ 909 VID_Obj_04_B_BlockCnt "Control signal to synchronize segmented blocks of object data";
CM_ SG_ 909 VID_Obj_04_Ang_Width "Width of the recorded side of the 3D-object box (positive angle left of x-axis)
Monovideo: Rear view for vehicles
Coordinate system: Transformed coordinate system with camera being origin
! Ego-movement has to be compensated !";
CM_ SG_ 909 VID_Obj_04_ProbExist "Probability for the existence of an object for the given time and position (in 3sigma-area)";
CM_ SG_ 909 VID_Obj_04_StdD_dAng_longitude "Standard deviation for VID_Obj_04_dAng_longitude";
CM_ SG_ 909 VID_Obj_04_dAng_longitude "Lateral velocity of the object (related to the reference point), calculated as change of angle in the frame";
CM_ SG_ 909 VID_Obj_04_StdD_Ang_Width "Standard deviation for VID_Obj_04_Ang_Width";
BA_DEF_  "BusType" STRING ;
BA_DEF_ BO_  "PF_Msg_ID" HEX 0 4095;
BA_DEF_ BO_  "PF_Msg_Name" STRING ;
BA_DEF_ SG_  "PF_Sig_Name" STRING ;
BA_DEF_  "DBName" STRING ;
BA_DEF_  "GenNWMApBusSleep" STRING ;
BA_DEF_  "GenNWMApCanNormal" STRING ;
BA_DEF_  "GenNWMApCanOff" STRING ;
BA_DEF_  "GenNWMApCanOn" STRING ;
BA_DEF_  "GenNWMApCanSleep" STRING ;
BA_DEF_  "GenNWMApCanWakeUp" STRING ;
BA_DEF_  "GenNWMGotoMode_Awake" STRING ;
BA_DEF_  "GenNWMGotoMode_BusSleep" STRING ;
BA_DEF_  "GenNWMSleepTime" INT 0 1000000;
BA_DEF_  "GenNWMTalkNM" STRING ;
BA_DEF_  "Manufacturer" STRING ;
BA_DEF_  "NmType" STRING ;
BA_DEF_  "VersionDay" INT 1 31;
BA_DEF_  "VersionMonth" INT 1 12;
BA_DEF_  "VersionWeek" INT 1 52;
BA_DEF_  "VersionYear" INT 0 99;
BA_DEF_  "VersionNumber" INT 0 65535;
BA_DEF_  "Baudrate" INT 0 1000000;
BA_DEF_  "SamplePointMin" INT 1 100;
BA_DEF_  "SamplePointMax" INT 1 100;
BA_DEF_  "SyncJumpWidthMin" INT 1 4;
BA_DEF_  "SyncJumpWidthMax" INT 1 4;
BA_DEF_ BU_  "GenNodAutoGenDsp" ENUM  "No","Yes";
BA_DEF_ BU_  "GenNodAutoGenSnd" ENUM  "No","Yes";
BA_DEF_ BU_  "GenNodSleepTime" INT 0 1000000;
BA_DEF_ BU_  "ILUsed" ENUM  "No","Yes";
BA_DEF_ BU_  "NodeLayerModules" STRING ;
BA_DEF_ BU_  "NmhNode" ENUM  "No","Yes";
BA_DEF_ BU_  "NmNode" ENUM  "No","Yes";
BA_DEF_ BO_  "DiagRequest" ENUM  "No","Yes";
BA_DEF_ BO_  "DiagResponse" ENUM  "No","Yes";
BA_DEF_ BO_  "DiagState" ENUM  "No","Yes";
BA_DEF_ BO_  "GenMsgCycleTime" INT 0 65535;
BA_DEF_ BO_  "GenMsgDelayTime" INT 0 100000;
BA_DEF_ BO_  "GenMsgILSupport" ENUM  "No","Yes";
BA_DEF_ BO_  "GenMsgPDUConstants" STRING ;
BA_DEF_ BO_  "GenMsgSendType" ENUM  "Cyclic","not_used","not_used","not_used","not_used","not_used","not_used","IfActive","NoMsgSendType";
BA_DEF_ BO_  "GenMsgStartDelayTime" INT 0 100000;
BA_DEF_ BO_  "NmMessage" ENUM  "No","Yes";
BA_DEF_ BO_  "NmhMessage" ENUM  "No","Yes";
BA_DEF_ BO_  "MsgType" ENUM  "Application","NM ","NMH","TP2.0","ISO-TP ","BAP","EID";
BA_DEF_ SG_  "GenSigActiveRepetitions" INT -2147483648 2147483647;
BA_DEF_ SG_  "GenSigSendType" ENUM  "Cyclic","OnWrite","OnWriteWithRepetition","OnChange","OnChangeWithRepetition","IfActive","IfActiveWithRepetition","NoSigSendType","OnChangeAndIfActive","OnChangeAndIfActiveWithRepetition";
BA_DEF_ SG_  "GenSigStartValue" INT -2147483648 2147483647;
BA_DEF_ SG_  "NWMWakeupAllowed" ENUM  "No","Yes";
BA_DEF_ SG_  "GenSigFuncType" ENUM  "NoFunction","MsgCounter","CRC-8","XOR","XOR-2","DatedBit","SW-Kl15","CHK","Constant","Protocol","CRC-8-SAE_J1850";
BA_DEF_ SG_  "GenSigSwitchedByIgnition" ENUM  "No","Yes";
BA_DEF_ SG_  "Fehlerwert" HEX 0 2147483647;
BA_DEF_ SG_  "GenSigMissingSourceValue" HEX 0 2147483647;
BA_DEF_ SG_  "SystemSignalLongSymbol" STRING ;
BA_DEF_REL_ BU_SG_REL_  "GenSigTimeoutTime" INT 0 65535;
BA_DEF_DEF_  "BusType" "";
BA_DEF_DEF_  "PF_Msg_ID" 0;
BA_DEF_DEF_  "PF_Msg_Name" "";
BA_DEF_DEF_  "PF_Sig_Name" ".";
BA_DEF_DEF_  "DBName" "";
BA_DEF_DEF_  "GenNWMApBusSleep" "";
BA_DEF_DEF_  "GenNWMApCanNormal" "";
BA_DEF_DEF_  "GenNWMApCanOff" "";
BA_DEF_DEF_  "GenNWMApCanOn" "";
BA_DEF_DEF_  "GenNWMApCanSleep" "";
BA_DEF_DEF_  "GenNWMApCanWakeUp" "";
BA_DEF_DEF_  "GenNWMGotoMode_Awake" "";
BA_DEF_DEF_  "GenNWMGotoMode_BusSleep" "";
BA_DEF_DEF_  "GenNWMSleepTime" 0;
BA_DEF_DEF_  "GenNWMTalkNM" "";
BA_DEF_DEF_  "Manufacturer" "";
BA_DEF_DEF_  "NmType" "None";
BA_DEF_DEF_  "VersionDay" 21;
BA_DEF_DEF_  "VersionMonth" 5;
BA_DEF_DEF_  "VersionWeek" 21;
BA_DEF_DEF_  "VersionYear" 13;
BA_DEF_DEF_  "VersionNumber" 0;
BA_DEF_DEF_  "Baudrate" 0;
BA_DEF_DEF_  "SamplePointMin" 1;
BA_DEF_DEF_  "SamplePointMax" 1;
BA_DEF_DEF_  "SyncJumpWidthMin" 1;
BA_DEF_DEF_  "SyncJumpWidthMax" 1;
BA_DEF_DEF_  "GenNodAutoGenDsp" "Yes";
BA_DEF_DEF_  "GenNodAutoGenSnd" "Yes";
BA_DEF_DEF_  "GenNodSleepTime" 0;
BA_DEF_DEF_  "ILUsed" "Yes";
BA_DEF_DEF_  "NodeLayerModules" "";
BA_DEF_DEF_  "NmhNode" "Yes";
BA_DEF_DEF_  "NmNode" "No";
BA_DEF_DEF_  "DiagRequest" "No";
BA_DEF_DEF_  "DiagResponse" "No";
BA_DEF_DEF_  "DiagState" "No";
BA_DEF_DEF_  "GenMsgCycleTime" 0;
BA_DEF_DEF_  "GenMsgDelayTime" 0;
BA_DEF_DEF_  "GenMsgILSupport" "No";
BA_DEF_DEF_  "GenMsgPDUConstants" "";
BA_DEF_DEF_  "GenMsgSendType" "NoMsgSendType";
BA_DEF_DEF_  "GenMsgStartDelayTime" 0;
BA_DEF_DEF_  "NmMessage" "No";
BA_DEF_DEF_  "NmhMessage" "No";
BA_DEF_DEF_  "MsgType" "Application";
BA_DEF_DEF_  "GenSigActiveRepetitions" 0;
BA_DEF_DEF_  "GenSigSendType" "NoSigSendType";
BA_DEF_DEF_  "GenSigStartValue" 0;
BA_DEF_DEF_  "NWMWakeupAllowed" "No";
BA_DEF_DEF_  "GenSigFuncType" "NoFunction";
BA_DEF_DEF_  "GenSigSwitchedByIgnition" "Yes";
BA_DEF_DEF_  "Fehlerwert" 0;
BA_DEF_DEF_  "GenSigMissingSourceValue" 0;
BA_DEF_DEF_REL_ "GenSigTimeoutTime" 0;
BA_DEF_DEF_  "SystemSignalLongSymbol" "";
BA_ "BusType" "CAN";
BA_ "SyncJumpWidthMax" 4;
BA_ "SyncJumpWidthMin" 2;
BA_ "SamplePointMax" 84;
BA_ "SamplePointMin" 80;
BA_ "Baudrate" 500000;
BA_ "Manufacturer" "VAG";
BA_ "GenNWMSleepTime" 4000;
BA_ "DBName" "SFCAN";
BA_ "NmhNode" BU_ Radar 0;
BA_ "GenNodSleepTime" BU_ Radar 4000;
BA_ "NmhNode" BU_ MPC2 0;
BA_ "GenNodSleepTime" BU_ MPC2 4000;
BA_ "PF_Msg_Name" BO_ 855 "RDR1_Obj_07";
BA_ "GenMsgSendType" BO_ 855 7;
BA_ "PF_Msg_Name" BO_ 854 "RDR1_Obj_06";
BA_ "GenMsgSendType" BO_ 854 7;
BA_ "GenMsgSendType" BO_ 853 7;
BA_ "PF_Msg_Name" BO_ 853 "RDR1_Obj_05";
BA_ "MsgType" BO_ 2617162255 6;
BA_ "MsgType" BO_ 2281601536 6;
BA_ "PF_Msg_Name" BO_ 2617145882 "BV_TRAMO_01";
BA_ "GenMsgCycleTime" BO_ 2617145882 40;
BA_ "GenMsgSendType" BO_ 2617145882 0;
BA_ "GenMsgCycleTime" BO_ 2617145883 40;
BA_ "GenMsgSendType" BO_ 2617145883 0;
BA_ "GenMsgSendType" BO_ 770 0;
BA_ "GenMsgPDUConstants" BO_ 770 "0x8e,0xf0,0xda,0x97,0x7c,0x5b,0x65,0x07,0x82,0xf6,0xa6,0x66,0x36,0x96,0x2e,0x6f";
BA_ "GenMsgILSupport" BO_ 770 1;
BA_ "GenMsgCycleTime" BO_ 770 80;
BA_ "PF_Msg_Name" BO_ 770 "Kamera_Status";
BA_ "PF_Msg_ID" BO_ 770 792;
BA_ "GenMsgSendType" BO_ 256 0;
BA_ "GenMsgCycleTime" BO_ 256 40;
BA_ "GenMsgSendType" BO_ 257 7;
BA_ "GenMsgSendType" BO_ 258 7;
BA_ "GenMsgSendType" BO_ 259 7;
BA_ "GenMsgSendType" BO_ 260 7;
BA_ "GenMsgSendType" BO_ 261 7;
BA_ "GenMsgSendType" BO_ 262 7;
BA_ "GenMsgSendType" BO_ 263 7;
BA_ "GenMsgSendType" BO_ 264 7;
BA_ "GenMsgSendType" BO_ 265 7;
BA_ "GenMsgSendType" BO_ 266 7;
BA_ "GenMsgSendType" BO_ 769 0;
BA_ "GenMsgPDUConstants" BO_ 769 "0x8e,0xf0,0xda,0x97,0x7c,0x5b,0x65,0x07,0x82,0xf6,0xa6,0x66,0x36,0x96,0x2e,0x6f";
BA_ "GenMsgILSupport" BO_ 769 1;
BA_ "GenMsgDelayTime" BO_ 769 30;
BA_ "GenMsgCycleTime" BO_ 769 100;
BA_ "PF_Msg_Name" BO_ 769 "BV1_Header";
BA_ "PF_Msg_ID" BO_ 769 513;
BA_ "GenMsgSendType" BO_ 832 0;
BA_ "GenMsgPDUConstants" BO_ 832 "0x6c,0xe7,0xc3,0x5a,0xf7,0x79,0x7d,0x04,0xbf,0xd9,0x07,0xdb,0x0a,0xa9,0xe9,0x4c";
BA_ "GenMsgILSupport" BO_ 832 1;
BA_ "GenMsgDelayTime" BO_ 832 30;
BA_ "GenMsgCycleTime" BO_ 832 100;
BA_ "PF_Msg_Name" BO_ 832 "BV1_Lin_01_A";
BA_ "PF_Msg_ID" BO_ 832 576;
BA_ "GenMsgSendType" BO_ 833 0;
BA_ "GenMsgPDUConstants" BO_ 833 "0x86,0x0d,0xbd,0xab,0x23,0xa5,0xea,0xe1,0x2c,0x51,0x0a,0x73,0x0b,0xe0,0xa8,0x9e";
BA_ "GenMsgILSupport" BO_ 833 1;
BA_ "GenMsgDelayTime" BO_ 833 30;
BA_ "GenMsgCycleTime" BO_ 833 100;
BA_ "PF_Msg_Name" BO_ 833 "BV1_Lin_01_B";
BA_ "PF_Msg_ID" BO_ 833 577;
BA_ "GenMsgSendType" BO_ 835 0;
BA_ "GenMsgPDUConstants" BO_ 835 "0x72,0x57,0x59,0x0c,0xb5,0x56,0xcf,0x8b,0x17,0x06,0xac,0x6d,0x1e,0x6a,0xe7,0x23";
BA_ "GenMsgILSupport" BO_ 835 1;
BA_ "GenMsgDelayTime" BO_ 835 30;
BA_ "GenMsgCycleTime" BO_ 835 100;
BA_ "PF_Msg_Name" BO_ 835 "BV1_Lin_02_A";
BA_ "PF_Msg_ID" BO_ 835 579;
BA_ "GenMsgSendType" BO_ 836 0;
BA_ "GenMsgPDUConstants" BO_ 836 "0x33,0xd4,0x06,0x78,0x88,0xc1,0x53,0x03,0xe9,0xe3,0x2c,0xf0,0x39,0x8c,0xde,0xc9";
BA_ "GenMsgILSupport" BO_ 836 1;
BA_ "GenMsgDelayTime" BO_ 836 30;
BA_ "GenMsgCycleTime" BO_ 836 100;
BA_ "PF_Msg_Name" BO_ 836 "BV1_Lin_02_B";
BA_ "PF_Msg_ID" BO_ 836 580;
BA_ "GenMsgSendType" BO_ 838 0;
BA_ "GenMsgPDUConstants" BO_ 838 "0x0e,0x0b,0x58,0x9e,0x3a,0x61,0xe3,0x1f,0xcf,0x76,0xd0,0x30,0xd5,0xe8,0x69,0x28";
BA_ "GenMsgILSupport" BO_ 838 1;
BA_ "GenMsgDelayTime" BO_ 838 30;
BA_ "GenMsgCycleTime" BO_ 838 100;
BA_ "PF_Msg_Name" BO_ 838 "BV1_Lin_03_A";
BA_ "PF_Msg_ID" BO_ 838 582;
BA_ "GenMsgSendType" BO_ 839 0;
BA_ "GenMsgPDUConstants" BO_ 839 "0xa2,0x75,0xa6,0xa1,0xaf,0x26,0x06,0x77,0x29,0x58,0x60,0xe4,0x68,0xc1,0x89,0x8a";
BA_ "GenMsgILSupport" BO_ 839 1;
BA_ "GenMsgDelayTime" BO_ 839 30;
BA_ "GenMsgCycleTime" BO_ 839 100;
BA_ "PF_Msg_Name" BO_ 839 "BV1_Lin_03_B";
BA_ "PF_Msg_ID" BO_ 839 583;
BA_ "GenMsgSendType" BO_ 841 0;
BA_ "GenMsgPDUConstants" BO_ 841 "0x1b,0x86,0x99,0xd3,0xf6,0x1d,0x9a,0x37,0x46,0x92,0xb9,0xa4,0xc9,0x41,0x4b,0x11";
BA_ "GenMsgILSupport" BO_ 841 1;
BA_ "GenMsgDelayTime" BO_ 841 30;
BA_ "GenMsgCycleTime" BO_ 841 100;
BA_ "PF_Msg_Name" BO_ 841 "BV1_Lin_04_A";
BA_ "PF_Msg_ID" BO_ 841 585;
BA_ "GenMsgSendType" BO_ 842 0;
BA_ "GenMsgPDUConstants" BO_ 842 "0x8d,0x89,0x82,0xcf,0x18,0x3b,0xdc,0x6a,0x2c,0x8f,0x43,0xb2,0x27,0x7b,0x40,0xb6";
BA_ "GenMsgILSupport" BO_ 842 1;
BA_ "GenMsgDelayTime" BO_ 842 30;
BA_ "GenMsgCycleTime" BO_ 842 100;
BA_ "PF_Msg_Name" BO_ 842 "BV1_Lin_04_B";
BA_ "PF_Msg_ID" BO_ 842 586;
BA_ "GenMsgSendType" BO_ 1385 0;
BA_ "GenMsgILSupport" BO_ 1385 1;
BA_ "GenMsgCycleTime" BO_ 1385 1000;
BA_ "PF_Msg_Name" BO_ 1385 "BV1_Position";
BA_ "PF_Msg_ID" BO_ 1385 1641;
BA_ "GenMsgSendType" BO_ 896 0;
BA_ "GenMsgPDUConstants" BO_ 896 "0x62,0xa0,0x0a,0x7c,0x55,0x1f,0x49,0xf6,0x15,0x43,0x33,0x2e,0x78,0xc0,0x53,0x74";
BA_ "GenMsgILSupport" BO_ 896 1;
BA_ "GenMsgDelayTime" BO_ 896 30;
BA_ "GenMsgCycleTime" BO_ 896 100;
BA_ "PF_Msg_Name" BO_ 896 "BV_Obj_01_A";
BA_ "PF_Msg_ID" BO_ 896 640;
BA_ "GenMsgSendType" BO_ 897 0;
BA_ "GenMsgPDUConstants" BO_ 897 "0x62,0xa0,0x0a,0x7c,0x55,0x1f,0x49,0xf6,0x15,0x43,0x33,0x2e,0x78,0xc0,0x53,0x74";
BA_ "GenMsgILSupport" BO_ 897 1;
BA_ "GenMsgDelayTime" BO_ 897 30;
BA_ "GenMsgCycleTime" BO_ 897 100;
BA_ "PF_Msg_Name" BO_ 897 "BV_Obj_01_B";
BA_ "PF_Msg_ID" BO_ 897 641;
BA_ "GenMsgSendType" BO_ 898 0;
BA_ "GenMsgPDUConstants" BO_ 898 "0x62,0xa0,0x0a,0x7c,0x55,0x1f,0x49,0xf6,0x15,0x43,0x33,0x2e,0x78,0xc0,0x53,0x74";
BA_ "GenMsgILSupport" BO_ 898 1;
BA_ "GenMsgDelayTime" BO_ 898 30;
BA_ "GenMsgCycleTime" BO_ 898 100;
BA_ "PF_Msg_Name" BO_ 898 "BV_Obj_01_C";
BA_ "PF_Msg_ID" BO_ 898 642;
BA_ "GenMsgSendType" BO_ 899 0;
BA_ "GenMsgPDUConstants" BO_ 899 "0x62,0xa0,0x0a,0x7c,0x55,0x1f,0x49,0xf6,0x15,0x43,0x33,0x2e,0x78,0xc0,0x53,0x74";
BA_ "GenMsgILSupport" BO_ 899 1;
BA_ "GenMsgDelayTime" BO_ 899 30;
BA_ "GenMsgCycleTime" BO_ 899 100;
BA_ "PF_Msg_Name" BO_ 899 "BV_Obj_01_D";
BA_ "PF_Msg_ID" BO_ 899 643;
BA_ "GenMsgSendType" BO_ 968 0;
BA_ "GenMsgPDUConstants" BO_ 968 "0x62,0xa0,0x0a,0x7c,0x55,0x1f,0x49,0xf6,0x15,0x43,0x33,0x2e,0x78,0xc0,0x53,0x74";
BA_ "GenMsgILSupport" BO_ 968 1;
BA_ "GenMsgDelayTime" BO_ 968 30;
BA_ "GenMsgCycleTime" BO_ 968 100;
BA_ "PF_Msg_Name" BO_ 968 "BV_Obj_01_E";
BA_ "PF_Msg_ID" BO_ 968 712;
BA_ "GenMsgSendType" BO_ 900 0;
BA_ "GenMsgPDUConstants" BO_ 900 "0x62,0xa0,0x0a,0x7c,0x55,0x1f,0x49,0xf6,0x15,0x43,0x33,0x2e,0x78,0xc0,0x53,0x74";
BA_ "GenMsgILSupport" BO_ 900 1;
BA_ "GenMsgDelayTime" BO_ 900 30;
BA_ "GenMsgCycleTime" BO_ 900 100;
BA_ "PF_Msg_Name" BO_ 900 "BV_Obj_02_A";
BA_ "PF_Msg_ID" BO_ 900 644;
BA_ "GenMsgSendType" BO_ 901 0;
BA_ "GenMsgPDUConstants" BO_ 901 "0x62,0xa0,0x0a,0x7c,0x55,0x1f,0x49,0xf6,0x15,0x43,0x33,0x2e,0x78,0xc0,0x53,0x74";
BA_ "GenMsgILSupport" BO_ 901 1;
BA_ "GenMsgDelayTime" BO_ 901 30;
BA_ "GenMsgCycleTime" BO_ 901 100;
BA_ "PF_Msg_Name" BO_ 901 "BV_Obj_02_B";
BA_ "PF_Msg_ID" BO_ 901 645;
BA_ "GenMsgSendType" BO_ 902 0;
BA_ "GenMsgPDUConstants" BO_ 902 "0x62,0xa0,0x0a,0x7c,0x55,0x1f,0x49,0xf6,0x15,0x43,0x33,0x2e,0x78,0xc0,0x53,0x74";
BA_ "GenMsgILSupport" BO_ 902 1;
BA_ "GenMsgDelayTime" BO_ 902 30;
BA_ "GenMsgCycleTime" BO_ 902 100;
BA_ "PF_Msg_Name" BO_ 902 "BV_Obj_02_C";
BA_ "PF_Msg_ID" BO_ 902 646;
BA_ "GenMsgSendType" BO_ 903 0;
BA_ "GenMsgPDUConstants" BO_ 903 "0x62,0xa0,0x0a,0x7c,0x55,0x1f,0x49,0xf6,0x15,0x43,0x33,0x2e,0x78,0xc0,0x53,0x74";
BA_ "GenMsgILSupport" BO_ 903 1;
BA_ "GenMsgDelayTime" BO_ 903 30;
BA_ "GenMsgCycleTime" BO_ 903 100;
BA_ "PF_Msg_Name" BO_ 903 "BV_Obj_02_D";
BA_ "PF_Msg_ID" BO_ 903 647;
BA_ "GenMsgSendType" BO_ 969 0;
BA_ "GenMsgPDUConstants" BO_ 969 "0x62,0xa0,0x0a,0x7c,0x55,0x1f,0x49,0xf6,0x15,0x43,0x33,0x2e,0x78,0xc0,0x53,0x74";
BA_ "GenMsgILSupport" BO_ 969 1;
BA_ "GenMsgDelayTime" BO_ 969 30;
BA_ "GenMsgCycleTime" BO_ 969 100;
BA_ "PF_Msg_Name" BO_ 969 "BV_Obj_02_E";
BA_ "PF_Msg_ID" BO_ 969 713;
BA_ "GenMsgSendType" BO_ 904 0;
BA_ "GenMsgPDUConstants" BO_ 904 "0x62,0xa0,0x0a,0x7c,0x55,0x1f,0x49,0xf6,0x15,0x43,0x33,0x2e,0x78,0xc0,0x53,0x74";
BA_ "GenMsgILSupport" BO_ 904 1;
BA_ "GenMsgDelayTime" BO_ 904 30;
BA_ "GenMsgCycleTime" BO_ 904 100;
BA_ "PF_Msg_Name" BO_ 904 "BV_Obj_03_A";
BA_ "PF_Msg_ID" BO_ 904 648;
BA_ "GenMsgSendType" BO_ 905 0;
BA_ "GenMsgPDUConstants" BO_ 905 "0x62,0xa0,0x0a,0x7c,0x55,0x1f,0x49,0xf6,0x15,0x43,0x33,0x2e,0x78,0xc0,0x53,0x74";
BA_ "GenMsgILSupport" BO_ 905 1;
BA_ "GenMsgDelayTime" BO_ 905 30;
BA_ "GenMsgCycleTime" BO_ 905 100;
BA_ "PF_Msg_Name" BO_ 905 "BV_Obj_03_B";
BA_ "PF_Msg_ID" BO_ 905 649;
BA_ "GenMsgSendType" BO_ 906 0;
BA_ "GenMsgPDUConstants" BO_ 906 "0x62,0xa0,0x0a,0x7c,0x55,0x1f,0x49,0xf6,0x15,0x43,0x33,0x2e,0x78,0xc0,0x53,0x74";
BA_ "GenMsgILSupport" BO_ 906 1;
BA_ "GenMsgDelayTime" BO_ 906 30;
BA_ "GenMsgCycleTime" BO_ 906 100;
BA_ "PF_Msg_Name" BO_ 906 "BV_Obj_03_C";
BA_ "PF_Msg_ID" BO_ 906 650;
BA_ "GenMsgSendType" BO_ 907 0;
BA_ "GenMsgPDUConstants" BO_ 907 "0x62,0xa0,0x0a,0x7c,0x55,0x1f,0x49,0xf6,0x15,0x43,0x33,0x2e,0x78,0xc0,0x53,0x74";
BA_ "GenMsgILSupport" BO_ 907 1;
BA_ "GenMsgDelayTime" BO_ 907 30;
BA_ "GenMsgCycleTime" BO_ 907 100;
BA_ "PF_Msg_Name" BO_ 907 "BV_Obj_03_D";
BA_ "PF_Msg_ID" BO_ 907 651;
BA_ "GenMsgSendType" BO_ 970 0;
BA_ "GenMsgPDUConstants" BO_ 970 "0x62,0xa0,0x0a,0x7c,0x55,0x1f,0x49,0xf6,0x15,0x43,0x33,0x2e,0x78,0xc0,0x53,0x74";
BA_ "GenMsgILSupport" BO_ 970 1;
BA_ "GenMsgDelayTime" BO_ 970 30;
BA_ "GenMsgCycleTime" BO_ 970 100;
BA_ "PF_Msg_Name" BO_ 970 "BV_Obj_03_E";
BA_ "PF_Msg_ID" BO_ 970 714;
BA_ "GenMsgSendType" BO_ 908 0;
BA_ "GenMsgPDUConstants" BO_ 908 "0x62,0xa0,0x0a,0x7c,0x55,0x1f,0x49,0xf6,0x15,0x43,0x33,0x2e,0x78,0xc0,0x53,0x74";
BA_ "GenMsgILSupport" BO_ 908 1;
BA_ "GenMsgDelayTime" BO_ 908 30;
BA_ "GenMsgCycleTime" BO_ 908 100;
BA_ "PF_Msg_Name" BO_ 908 "BV_Obj_04_A";
BA_ "PF_Msg_ID" BO_ 908 652;
BA_ "GenMsgSendType" BO_ 909 0;
BA_ "GenMsgPDUConstants" BO_ 909 "0x62,0xa0,0x0a,0x7c,0x55,0x1f,0x49,0xf6,0x15,0x43,0x33,0x2e,0x78,0xc0,0x53,0x74";
BA_ "GenMsgILSupport" BO_ 909 1;
BA_ "GenMsgDelayTime" BO_ 909 30;
BA_ "GenMsgCycleTime" BO_ 909 100;
BA_ "PF_Msg_Name" BO_ 909 "BV_Obj_04_B";
BA_ "PF_Msg_ID" BO_ 909 653;
BA_ "GenSigStartValue" SG_ 855 RDR_Obj_07_vx_v 512;
BA_ "GenSigSendType" SG_ 855 RDR_Obj_07_vx_v 0;
BA_ "GenSigSendType" SG_ 855 RDR_Obj_07_RFF 0;
BA_ "GenSigSendType" SG_ 855 RDR_Obj_07_Obj_Obj_ID 0;
BA_ "GenSigSendType" SG_ 855 RDR_Obj_07_MsgCnt 0;
BA_ "GenSigStartValue" SG_ 855 RDR_Obj_07_dy_v 512;
BA_ "GenSigSendType" SG_ 855 RDR_Obj_07_dy_v 0;
BA_ "GenSigSendType" SG_ 855 RDR_Obj_07_dx_v 0;
BA_ "GenSigSendType" SG_ 855 RDR_Obj_07_ChkSum 0;
BA_ "GenSigSendType" SG_ 855 RDR_Obj_07_BlockCnt 0;
BA_ "GenSigSendType" SG_ 854 RDR_Obj_06_vx_v 0;
BA_ "GenSigStartValue" SG_ 854 RDR_Obj_06_vx_v 512;
BA_ "GenSigSendType" SG_ 854 RDR_Obj_06_RFF 0;
BA_ "GenSigSendType" SG_ 854 RDR_Obj_06_Obj_Obj_ID 0;
BA_ "GenSigSendType" SG_ 854 RDR_Obj_06_MsgCnt 0;
BA_ "GenSigStartValue" SG_ 854 RDR_Obj_06_dy_v 512;
BA_ "GenSigSendType" SG_ 854 RDR_Obj_06_dx_v 0;
BA_ "GenSigSendType" SG_ 854 RDR_Obj_06_ChkSum 0;
BA_ "GenSigSendType" SG_ 854 RDR_Obj_06_BlockCnt 0;
BA_ "GenSigStartValue" SG_ 853 RDR_Obj_05_vx_v 512;
BA_ "GenSigSendType" SG_ 853 RDR_Obj_05_vx_v 0;
BA_ "PF_Sig_Name" SG_ 853 RDR_Obj_05_vx_v "RDR1_Obj_05_vx_v";
BA_ "GenSigSendType" SG_ 853 RDR_Obj_05_RFF 0;
BA_ "PF_Sig_Name" SG_ 853 RDR_Obj_05_RFF "RDR1_Obj_05_RFF";
BA_ "GenSigSendType" SG_ 853 RDR_Obj_05_Obj_Obj_ID 0;
BA_ "PF_Sig_Name" SG_ 853 RDR_Obj_05_Obj_Obj_ID "RDR1_Obj_05_Nummer";
BA_ "GenSigFuncType" SG_ 853 RDR_Obj_05_MsgCnt 1;
BA_ "GenSigSendType" SG_ 853 RDR_Obj_05_MsgCnt 0;
BA_ "PF_Sig_Name" SG_ 853 RDR_Obj_05_MsgCnt "RDR1_Obj_05_BZ";
BA_ "GenSigStartValue" SG_ 853 RDR_Obj_05_dy_v 512;
BA_ "GenSigSendType" SG_ 853 RDR_Obj_05_dy_v 0;
BA_ "PF_Sig_Name" SG_ 853 RDR_Obj_05_dy_v "RDR1_Obj_05_dy_v";
BA_ "GenSigSendType" SG_ 853 RDR_Obj_05_dx_v 0;
BA_ "PF_Sig_Name" SG_ 853 RDR_Obj_05_dx_v "RDR1_Obj_05_dx_v";
BA_ "GenSigFuncType" SG_ 853 RDR_Obj_05_ChkSum 2;
BA_ "PF_Sig_Name" SG_ 853 RDR_Obj_05_ChkSum "RDR1_Obj_05_CRC";
BA_ "GenSigSendType" SG_ 853 RDR_Obj_05_BlockCnt 0;
BA_ "PF_Sig_Name" SG_ 853 RDR_Obj_05_BlockCnt "RDR1_Obj_05_BlockZaehler";
BA_ "PF_Sig_Name" SG_ 2281601536 ImgTimeDelay "ImgTimeDelay";
BA_ "PF_Sig_Name" SG_ 2281601536 ImgFrameCounter "ImgFrameCounter";
BA_ "PF_Sig_Name" SG_ 2617145882 BV_Tramo_Yaw "BV_Tramo_Yaw";
BA_ "PF_Sig_Name" SG_ 2617145882 BV_Tramo_Roll "BV_Tramo_Roll";
BA_ "PF_Sig_Name" SG_ 2617145882 BV_Tramo_Pitch "BV_Tramo_Pitch";
BA_ "PF_Sig_Name" SG_ 2617145882 BV_Tramo_Counter "BV_Tramo_Counter";
BA_ "PF_Sig_Name" SG_ 2617145882 BV_Tramo_Blockzaehler "BV_Tramo_Blockzaehler";
BA_ "PF_Sig_Name" SG_ 2617145883 BV_Sumo_ver_Kruemm_Aend "BV_Sumo_ver_Kruemm_Aend";
BA_ "PF_Sig_Name" SG_ 2617145883 BV_Sumo_Blockzaehler "BV_Sumo_Blockzaehler";
BA_ "PF_Sig_Name" SG_ 2617146880 XCP_Kamera_DTO_01_Data "XCP_Kamera_DTO_01_Data";
BA_ "PF_Sig_Name" SG_ 2617146881 XCP_Kamera_CRO_01_Data "XCP_Kamera_CRO_01_Data";
BA_ "GenSigStartValue" SG_ 770 SpeedLimitationValue 255;
BA_ "PF_Sig_Name" SG_ 770 VID_Stat2_MsgCnt "N/A";
BA_ "GenSigSendType" SG_ 770 VID_Stat2_MsgCnt 0;
BA_ "GenSigFuncType" SG_ 770 VID_Stat2_MsgCnt 1;
BA_ "PF_Sig_Name" SG_ 770 VID_Stat2_ChkSum "N/A";
BA_ "GenSigSendType" SG_ 770 VID_Stat2_ChkSum 0;
BA_ "GenSigFuncType" SG_ 770 VID_Stat2_ChkSum 2;
BA_ "GenSigSendType" SG_ 770 VID_Stat2_Camera_State 0;
BA_ "PF_Sig_Name" SG_ 770 VID_Stat2_Camera_State "Kamera_Systemzustand";
BA_ "GenSigFuncType" SG_ 769 VID_Stat_ChkSum 2;
BA_ "GenSigSendType" SG_ 769 VID_Stat_ChkSum 0;
BA_ "PF_Sig_Name" SG_ 769 VID_Stat_ChkSum "BV1_Header_CRC";
BA_ "GenSigFuncType" SG_ 769 VID_Stat_MsgCnt 1;
BA_ "GenSigSendType" SG_ 769 VID_Stat_MsgCnt 0;
BA_ "PF_Sig_Name" SG_ 769 VID_Stat_MsgCnt "BV1_Header_BZ";
BA_ "PF_Sig_Name" SG_ 769 VID_Stat_BlockCnt "BV1_Header_BlockZaehler";
BA_ "GenSigSendType" SG_ 769 VID_Stat_BlockCnt 3;
BA_ "GenSigSendType" SG_ 769 VID_Stat_ObjDataAge 0;
BA_ "PF_Sig_Name" SG_ 769 VID_Stat_ObjDataAge "BV1_Objektdatenalter";
BA_ "GenSigSendType" SG_ 769 VID_Stat_Upd_Cnt 0;
BA_ "PF_Sig_Name" SG_ 769 VID_Stat_Upd_Cnt "BV1_Update_Zaehler";
BA_ "GenSigSendType" SG_ 769 VID_Stat_Intruder 0;
BA_ "PF_Sig_Name" SG_ 769 VID_Stat_Intruder "BV_Objekt_Master_RFD_intruder";
BA_ "GenSigSendType" SG_ 769 VID_LDA_Counter 0;
BA_ "PF_Sig_Name" SG_ 769 VID_LDA_Counter "BV_LDA_Counter";
BA_ "GenSigSendType" SG_ 769 VID_Stat_MOD_Cnt 0;
BA_ "PF_Sig_Name" SG_ 769 VID_Stat_MOD_Cnt "BV_MOD_Counter";
BA_ "Fehlerwert" SG_ 769 VID_Stat_PED_Warning 3;
BA_ "GenSigSendType" SG_ 769 VID_Stat_PED_Warning 0;
BA_ "PF_Sig_Name" SG_ 769 VID_Stat_PED_Warning "FGW_Status";
BA_ "Fehlerwert" SG_ 769 VID_Stat_RFD_notAvail 3;
BA_ "GenSigSendType" SG_ 769 VID_Stat_RFD_notAvail 0;
BA_ "PF_Sig_Name" SG_ 769 VID_Stat_RFD_notAvail "BV1_RFD_nicht_verfuegbar";
BA_ "GenSigSendType" SG_ 769 VID_Stat_PED_Config 0;
BA_ "PF_Sig_Name" SG_ 769 VID_Stat_PED_Config "FGS_Konfiguration";
BA_ "GenSigSendType" SG_ 769 VID_Stat_LaneDataAge 0;
BA_ "PF_Sig_Name" SG_ 769 VID_Stat_LaneDataAge "BV1_Spurdatenalter";
BA_ "GenSigSendType" SG_ 769 VID_Stat_blindness_det 0;
BA_ "PF_Sig_Name" SG_ 769 VID_Stat_blindness_det "BV_blindness_detected";
BA_ "GenSigSendType" SG_ 769 VID_Stat_Freesight_nOK 0;
BA_ "PF_Sig_Name" SG_ 769 VID_Stat_Freesight_nOK "BV_Freisicht_niO";
BA_ "GenSigSendType" SG_ 769 VID_Stat_Error 0;
BA_ "PF_Sig_Name" SG_ 769 VID_Stat_Error "BV_relevanter_Fehler";
BA_ "GenSigSendType" SG_ 769 VID_Stat_NotAvail 0;
BA_ "PF_Sig_Name" SG_ 769 VID_Stat_NotAvail "BV_relevante_Nichtverfuegbarkeit";
BA_ "GenSigFuncType" SG_ 832 VID_Lin_01_A_ChkSum 2;
BA_ "GenSigSendType" SG_ 832 VID_Lin_01_A_ChkSum 0;
BA_ "PF_Sig_Name" SG_ 832 VID_Lin_01_A_ChkSum "BV1_Lin_01_A_CRC";
BA_ "GenSigFuncType" SG_ 832 VID_Lin_01_A_MsgCnt 1;
BA_ "GenSigSendType" SG_ 832 VID_Lin_01_A_MsgCnt 0;
BA_ "PF_Sig_Name" SG_ 832 VID_Lin_01_A_MsgCnt "BV1_Lin_01_A_BZ";
BA_ "GenSigSendType" SG_ 832 VID_Lin_01_A_BlockCnt 3;
BA_ "PF_Sig_Name" SG_ 832 VID_Lin_01_A_BlockCnt "BV1_Lin_01_A_BlockZaehler";
BA_ "GenSigSendType" SG_ 832 VID_Lin_01_dx_Start 0;
BA_ "PF_Sig_Name" SG_ 832 VID_Lin_01_dx_Start "BV_Linie_01_dx_Beginn";
BA_ "GenSigSendType" SG_ 832 VID_Lin_01_dx_Lookahead 0;
BA_ "PF_Sig_Name" SG_ 832 VID_Lin_01_dx_Lookahead "BV_Linie_01_dx_Vorausschau";
BA_ "GenSigStartValue" SG_ 832 VID_Lin_01_dy 2048;
BA_ "GenSigSendType" SG_ 832 VID_Lin_01_dy 0;
BA_ "PF_Sig_Name" SG_ 832 VID_Lin_01_dy "BV_Linie_01_dy";
BA_ "GenSigSendType" SG_ 832 VID_Lin_01_ProbExists 0;
BA_ "PF_Sig_Name" SG_ 832 VID_Lin_01_ProbExists "BV_Linie_01_Existenzmass";
BA_ "GenSigStartValue" SG_ 832 VID_Lin_01_DiffYawAng 2048;
BA_ "GenSigSendType" SG_ 832 VID_Lin_01_DiffYawAng 0;
BA_ "PF_Sig_Name" SG_ 832 VID_Lin_01_DiffYawAng "BV_Linie_01_Gierw_diff";
BA_ "GenSigFuncType" SG_ 833 VID_Lin_01_B_ChkSum 2;
BA_ "GenSigSendType" SG_ 833 VID_Lin_01_B_ChkSum 0;
BA_ "PF_Sig_Name" SG_ 833 VID_Lin_01_B_ChkSum "BV1_Lin_01_B_CRC";
BA_ "GenSigFuncType" SG_ 833 VID_Lin_01_B_MsgCnt 1;
BA_ "GenSigSendType" SG_ 833 VID_Lin_01_B_MsgCnt 0;
BA_ "PF_Sig_Name" SG_ 833 VID_Lin_01_B_MsgCnt "BV1_Lin_01_B_BZ";
BA_ "GenSigSendType" SG_ 833 VID_Lin_01_B_BlockCnt 3;
BA_ "PF_Sig_Name" SG_ 833 VID_Lin_01_B_BlockCnt "BV1_Lin_01_B_BlockZaehler";
BA_ "GenSigStartValue" SG_ 833 VID_Lin_01_hor_curve_change 2047;
BA_ "GenSigSendType" SG_ 833 VID_Lin_01_hor_curve_change 0;
BA_ "PF_Sig_Name" SG_ 833 VID_Lin_01_hor_curve_change "BV_Linie_01_hor_Kruemm_Aend";
BA_ "GenSigStartValue" SG_ 833 VID_Lin_01_hor_curve 2047;
BA_ "GenSigSendType" SG_ 833 VID_Lin_01_hor_curve 0;
BA_ "PF_Sig_Name" SG_ 833 VID_Lin_01_hor_curve "BV_Linie_01_hor_Kruemmung";
BA_ "GenSigSendType" SG_ 833 VID_Lin_01_Line_Width 0;
BA_ "PF_Sig_Name" SG_ 833 VID_Lin_01_Line_Width "BV_Linie_01_Linienbreite";
BA_ "GenSigSendType" SG_ 833 VID_Lin_01_Line_ID 0;
BA_ "PF_Sig_Name" SG_ 833 VID_Lin_01_Line_ID "BV_Linie_01_Liniennummer";
BA_ "GenSigSendType" SG_ 833 VID_Lin_01_Line_Type 0;
BA_ "PF_Sig_Name" SG_ 833 VID_Lin_01_Line_Type "BV_Linie_01_Typ";
BA_ "GenSigSendType" SG_ 833 VID_Lin_01_Line_Colour 0;
BA_ "PF_Sig_Name" SG_ 833 VID_Lin_01_Line_Colour "BV_Linie_01_Farbe";
BA_ "GenSigFuncType" SG_ 835 VID_Lin_02_A_ChkSum 2;
BA_ "GenSigSendType" SG_ 835 VID_Lin_02_A_ChkSum 0;
BA_ "PF_Sig_Name" SG_ 835 VID_Lin_02_A_ChkSum "BV1_Lin_02_A_CRC";
BA_ "GenSigFuncType" SG_ 835 VID_Lin_02_A_MsgCnt 1;
BA_ "GenSigSendType" SG_ 835 VID_Lin_02_A_MsgCnt 0;
BA_ "PF_Sig_Name" SG_ 835 VID_Lin_02_A_MsgCnt "BV1_Lin_02_A_BZ";
BA_ "GenSigSendType" SG_ 835 VID_Lin_02_A_BlockCnt 3;
BA_ "PF_Sig_Name" SG_ 835 VID_Lin_02_A_BlockCnt "BV1_Lin_02_A_BlockZaehler";
BA_ "GenSigSendType" SG_ 835 VID_Lin_02_dx_Start 0;
BA_ "PF_Sig_Name" SG_ 835 VID_Lin_02_dx_Start "BV_Linie_02_dx_Beginn";
BA_ "GenSigSendType" SG_ 835 VID_Lin_02_dx_Lookahead 0;
BA_ "PF_Sig_Name" SG_ 835 VID_Lin_02_dx_Lookahead "BV_Linie_02_dx_Vorausschau";
BA_ "GenSigStartValue" SG_ 835 VID_Lin_02_dy 2048;
BA_ "GenSigSendType" SG_ 835 VID_Lin_02_dy 0;
BA_ "PF_Sig_Name" SG_ 835 VID_Lin_02_dy "BV_Linie_02_dy";
BA_ "GenSigSendType" SG_ 835 VID_Lin_02_ProbExists 0;
BA_ "PF_Sig_Name" SG_ 835 VID_Lin_02_ProbExists "BV_Linie_02_Existenzmass";
BA_ "GenSigStartValue" SG_ 835 VID_Lin_02_DiffYawAng 2048;
BA_ "GenSigSendType" SG_ 835 VID_Lin_02_DiffYawAng 0;
BA_ "PF_Sig_Name" SG_ 835 VID_Lin_02_DiffYawAng "BV_Linie_02_Gierw_diff";
BA_ "GenSigFuncType" SG_ 836 VID_Lin_02_B_ChkSum 2;
BA_ "GenSigSendType" SG_ 836 VID_Lin_02_B_ChkSum 0;
BA_ "PF_Sig_Name" SG_ 836 VID_Lin_02_B_ChkSum "BV1_Lin_02_B_CRC";
BA_ "GenSigFuncType" SG_ 836 VID_Lin_02_B_MsgCnt 1;
BA_ "GenSigSendType" SG_ 836 VID_Lin_02_B_MsgCnt 0;
BA_ "PF_Sig_Name" SG_ 836 VID_Lin_02_B_MsgCnt "BV1_Lin_02_B_BZ";
BA_ "GenSigSendType" SG_ 836 VID_Lin_02_B_BlockCnt 3;
BA_ "PF_Sig_Name" SG_ 836 VID_Lin_02_B_BlockCnt "BV1_Lin_02_B_BlockZaehler";
BA_ "GenSigStartValue" SG_ 836 VID_Lin_02_hor_curve_change 2047;
BA_ "GenSigSendType" SG_ 836 VID_Lin_02_hor_curve_change 0;
BA_ "PF_Sig_Name" SG_ 836 VID_Lin_02_hor_curve_change "BV_Linie_02_hor_Kruemm_Aend";
BA_ "GenSigStartValue" SG_ 836 VID_Lin_02_hor_curve 2047;
BA_ "GenSigSendType" SG_ 836 VID_Lin_02_hor_curve 0;
BA_ "PF_Sig_Name" SG_ 836 VID_Lin_02_hor_curve "BV_Linie_02_hor_Kruemmung";
BA_ "GenSigSendType" SG_ 836 VID_Lin_02_Line_Width 0;
BA_ "PF_Sig_Name" SG_ 836 VID_Lin_02_Line_Width "BV_Linie_02_Linienbreite";
BA_ "GenSigSendType" SG_ 836 VID_Lin_02_Line_ID 0;
BA_ "PF_Sig_Name" SG_ 836 VID_Lin_02_Line_ID "BV_Linie_02_Liniennummer";
BA_ "GenSigSendType" SG_ 836 VID_Lin_02_Line_Type 0;
BA_ "PF_Sig_Name" SG_ 836 VID_Lin_02_Line_Type "BV_Linie_02_Typ";
BA_ "GenSigSendType" SG_ 836 VID_Lin_02_Line_Colour 0;
BA_ "PF_Sig_Name" SG_ 836 VID_Lin_02_Line_Colour "BV_Linie_02_Farbe";
BA_ "GenSigFuncType" SG_ 838 VID_Lin_03_A_ChkSum 2;
BA_ "GenSigSendType" SG_ 838 VID_Lin_03_A_ChkSum 0;
BA_ "PF_Sig_Name" SG_ 838 VID_Lin_03_A_ChkSum "BV1_Lin_03_A_CRC";
BA_ "GenSigFuncType" SG_ 838 VID_Lin_03_A_MsgCnt 1;
BA_ "GenSigSendType" SG_ 838 VID_Lin_03_A_MsgCnt 0;
BA_ "PF_Sig_Name" SG_ 838 VID_Lin_03_A_MsgCnt "BV1_Lin_03_A_BZ";
BA_ "GenSigSendType" SG_ 838 VID_Lin_03_A_BlockCnt 3;
BA_ "PF_Sig_Name" SG_ 838 VID_Lin_03_A_BlockCnt "BV1_Lin_03_A_BlockZaehler";
BA_ "GenSigSendType" SG_ 838 VID_Lin_03_dx_Start 0;
BA_ "PF_Sig_Name" SG_ 838 VID_Lin_03_dx_Start "BV_Linie_03_dx_Beginn";
BA_ "GenSigSendType" SG_ 838 VID_Lin_03_dx_Lookahead 0;
BA_ "PF_Sig_Name" SG_ 838 VID_Lin_03_dx_Lookahead "BV_Linie_03_dx_Vorausschau";
BA_ "GenSigStartValue" SG_ 838 VID_Lin_03_dy 2048;
BA_ "GenSigSendType" SG_ 838 VID_Lin_03_dy 0;
BA_ "PF_Sig_Name" SG_ 838 VID_Lin_03_dy "BV_Linie_03_dy";
BA_ "GenSigSendType" SG_ 838 VID_Lin_03_ProbExists 0;
BA_ "PF_Sig_Name" SG_ 838 VID_Lin_03_ProbExists "BV_Linie_03_Existenzmass";
BA_ "GenSigStartValue" SG_ 838 VID_Lin_03_DiffYawAng 2048;
BA_ "GenSigSendType" SG_ 838 VID_Lin_03_DiffYawAng 0;
BA_ "PF_Sig_Name" SG_ 838 VID_Lin_03_DiffYawAng "BV_Linie_03_Gierw_diff";
BA_ "GenSigFuncType" SG_ 839 VID_Lin_03_B_ChkSum 2;
BA_ "GenSigSendType" SG_ 839 VID_Lin_03_B_ChkSum 0;
BA_ "PF_Sig_Name" SG_ 839 VID_Lin_03_B_ChkSum "BV1_Lin_03_B_CRC";
BA_ "GenSigFuncType" SG_ 839 VID_Lin_03_B_MsgCnt 1;
BA_ "GenSigSendType" SG_ 839 VID_Lin_03_B_MsgCnt 0;
BA_ "PF_Sig_Name" SG_ 839 VID_Lin_03_B_MsgCnt "BV1_Lin_03_B_BZ";
BA_ "GenSigSendType" SG_ 839 VID_Lin_03_B_BlockCnt 3;
BA_ "PF_Sig_Name" SG_ 839 VID_Lin_03_B_BlockCnt "BV1_Lin_03_B_BlockZaehler";
BA_ "GenSigStartValue" SG_ 839 VID_Lin_03_hor_curve_change 2047;
BA_ "GenSigSendType" SG_ 839 VID_Lin_03_hor_curve_change 0;
BA_ "PF_Sig_Name" SG_ 839 VID_Lin_03_hor_curve_change "BV_Linie_03_hor_Kruemm_Aend";
BA_ "GenSigStartValue" SG_ 839 VID_Lin_03_hor_curve 2047;
BA_ "GenSigSendType" SG_ 839 VID_Lin_03_hor_curve 0;
BA_ "PF_Sig_Name" SG_ 839 VID_Lin_03_hor_curve "BV_Linie_03_hor_Kruemmung";
BA_ "GenSigSendType" SG_ 839 VID_Lin_03_Line_Width 0;
BA_ "PF_Sig_Name" SG_ 839 VID_Lin_03_Line_Width "BV_Linie_03_Linienbreite";
BA_ "GenSigSendType" SG_ 839 VID_Lin_03_Line_ID 0;
BA_ "PF_Sig_Name" SG_ 839 VID_Lin_03_Line_ID "BV_Linie_03_Liniennummer";
BA_ "GenSigSendType" SG_ 839 VID_Lin_03_Line_Type 0;
BA_ "PF_Sig_Name" SG_ 839 VID_Lin_03_Line_Type "BV_Linie_03_Typ";
BA_ "GenSigSendType" SG_ 839 VID_Lin_03_Line_Colour 0;
BA_ "PF_Sig_Name" SG_ 839 VID_Lin_03_Line_Colour "BV_Linie_03_Farbe";
BA_ "GenSigFuncType" SG_ 841 VID_Lin_04_A_ChkSum 2;
BA_ "GenSigSendType" SG_ 841 VID_Lin_04_A_ChkSum 0;
BA_ "PF_Sig_Name" SG_ 841 VID_Lin_04_A_ChkSum "BV1_Lin_04_A_CRC";
BA_ "GenSigFuncType" SG_ 841 VID_Lin_04_A_MsgCnt 1;
BA_ "GenSigSendType" SG_ 841 VID_Lin_04_A_MsgCnt 0;
BA_ "PF_Sig_Name" SG_ 841 VID_Lin_04_A_MsgCnt "BV1_Lin_04_A_BZ";
BA_ "GenSigSendType" SG_ 841 VID_Lin_04_A_BlockCnt 3;
BA_ "PF_Sig_Name" SG_ 841 VID_Lin_04_A_BlockCnt "BV1_Lin_04_A_BlockZaehler";
BA_ "GenSigSendType" SG_ 841 VID_Lin_04_dx_Start 0;
BA_ "PF_Sig_Name" SG_ 841 VID_Lin_04_dx_Start "BV_Linie_04_dx_Beginn";
BA_ "GenSigSendType" SG_ 841 VID_Lin_04_dx_Lookahead 0;
BA_ "PF_Sig_Name" SG_ 841 VID_Lin_04_dx_Lookahead "BV_Linie_04_dx_Vorausschau";
BA_ "GenSigStartValue" SG_ 841 VID_Lin_04_dy 2048;
BA_ "GenSigSendType" SG_ 841 VID_Lin_04_dy 0;
BA_ "PF_Sig_Name" SG_ 841 VID_Lin_04_dy "BV_Linie_04_dy";
BA_ "GenSigSendType" SG_ 841 VID_Lin_04_ProbExists 0;
BA_ "PF_Sig_Name" SG_ 841 VID_Lin_04_ProbExists "BV_Linie_04_Existenzmass";
BA_ "GenSigStartValue" SG_ 841 VID_Lin_04_DiffYawAng 2048;
BA_ "GenSigSendType" SG_ 841 VID_Lin_04_DiffYawAng 0;
BA_ "PF_Sig_Name" SG_ 841 VID_Lin_04_DiffYawAng "BV_Linie_04_Gierw_diff";
BA_ "GenSigFuncType" SG_ 842 VID_Lin_04_B_ChkSum 2;
BA_ "GenSigSendType" SG_ 842 VID_Lin_04_B_ChkSum 0;
BA_ "PF_Sig_Name" SG_ 842 VID_Lin_04_B_ChkSum "BV1_Lin_04_B_CRC";
BA_ "GenSigFuncType" SG_ 842 VID_Lin_04_B_MsgCnt 1;
BA_ "GenSigSendType" SG_ 842 VID_Lin_04_B_MsgCnt 0;
BA_ "PF_Sig_Name" SG_ 842 VID_Lin_04_B_MsgCnt "BV1_Lin_04_B_BZ";
BA_ "GenSigSendType" SG_ 842 VID_Lin_04_B_BlockCnt 3;
BA_ "PF_Sig_Name" SG_ 842 VID_Lin_04_B_BlockCnt "BV1_Lin_04_B_BlockZaehler";
BA_ "GenSigStartValue" SG_ 842 VID_Lin_04_hor_curve_change 2047;
BA_ "GenSigSendType" SG_ 842 VID_Lin_04_hor_curve_change 0;
BA_ "PF_Sig_Name" SG_ 842 VID_Lin_04_hor_curve_change "BV_Linie_04_hor_Kruemm_Aend";
BA_ "GenSigStartValue" SG_ 842 VID_Lin_04_hor_curve 2047;
BA_ "GenSigSendType" SG_ 842 VID_Lin_04_hor_curve 0;
BA_ "PF_Sig_Name" SG_ 842 VID_Lin_04_hor_curve "BV_Linie_04_hor_Kruemmung";
BA_ "GenSigSendType" SG_ 842 VID_Lin_04_Line_Width 0;
BA_ "PF_Sig_Name" SG_ 842 VID_Lin_04_Line_Width "BV_Linie_04_Linienbreite";
BA_ "GenSigSendType" SG_ 842 VID_Lin_04_Line_ID 0;
BA_ "PF_Sig_Name" SG_ 842 VID_Lin_04_Line_ID "BV_Linie_04_Liniennummer";
BA_ "GenSigSendType" SG_ 842 VID_Lin_04_Line_Type 0;
BA_ "PF_Sig_Name" SG_ 842 VID_Lin_04_Line_Type "BV_Linie_04_Typ";
BA_ "GenSigSendType" SG_ 842 VID_Lin_04_Line_Colour 0;
BA_ "PF_Sig_Name" SG_ 842 VID_Lin_04_Line_Colour "BV_Linie_04_Farbe";
BA_ "GenSigSendType" SG_ 1385 VID_MountPos_MsgCnt 0;
BA_ "PF_Sig_Name" SG_ 1385 VID_MountPos_MsgCnt "BV1_Position_BZ";
BA_ "GenSigSendType" SG_ 1385 VID_MountPos_ChkSum 0;
BA_ "PF_Sig_Name" SG_ 1385 VID_MountPos_ChkSum "BV1_Position_CRC";
BA_ "GenSigFuncType" SG_ 1385 VID_MountPos_ChkSum 2;
BA_ "Fehlerwert" SG_ 1385 VID_MountPos_x 4095;
BA_ "GenSigSendType" SG_ 1385 VID_MountPos_x 0;
BA_ "PF_Sig_Name" SG_ 1385 VID_MountPos_x "BV_Position_Kamera_x";
BA_ "Fehlerwert" SG_ 1385 VID_MountPos_y 4095;
BA_ "GenSigSendType" SG_ 1385 VID_MountPos_y 0;
BA_ "PF_Sig_Name" SG_ 1385 VID_MountPos_y "BV_Position_Kamera_y";
BA_ "Fehlerwert" SG_ 1385 VID_MountPos_z 4095;
BA_ "GenSigSendType" SG_ 1385 VID_MountPos_z 0;
BA_ "PF_Sig_Name" SG_ 1385 VID_MountPos_z "BV_Position_Kamera_z";
BA_ "GenSigFuncType" SG_ 896 VID_Obj_01_A_ChkSum 2;
BA_ "GenSigSendType" SG_ 896 VID_Obj_01_A_ChkSum 0;
BA_ "PF_Sig_Name" SG_ 896 VID_Obj_01_A_ChkSum "BV_Obj_01_A_CRC";
BA_ "GenSigFuncType" SG_ 896 VID_Obj_01_A_MsgCnt 1;
BA_ "GenSigSendType" SG_ 896 VID_Obj_01_A_MsgCnt 0;
BA_ "PF_Sig_Name" SG_ 896 VID_Obj_01_A_MsgCnt "BV_Obj_01_A_BZ";
BA_ "GenSigSendType" SG_ 896 VID_Obj_01_A_BlockCnt 3;
BA_ "PF_Sig_Name" SG_ 896 VID_Obj_01_A_BlockCnt "BV1_Obj_01_A_BlockZaehler";
BA_ "GenSigStartValue" SG_ 896 VID_Obj_01_Dist_longitude 4095;
BA_ "GenSigSendType" SG_ 896 VID_Obj_01_Dist_longitude 0;
BA_ "PF_Sig_Name" SG_ 896 VID_Obj_01_Dist_longitude "BV1_Obj_01_Dist_longitude";
BA_ "GenSigStartValue" SG_ 896 VID_Obj_01_StdD_Dist_longitude 127;
BA_ "GenSigSendType" SG_ 896 VID_Obj_01_StdD_Dist_longitude 0;
BA_ "PF_Sig_Name" SG_ 896 VID_Obj_01_StdD_Dist_longitude "BV1_Obj_01_Dist_longitudeStdA";
BA_ "GenSigStartValue" SG_ 896 VID_Obj_01_Ang_Center 2047;
BA_ "GenSigSendType" SG_ 896 VID_Obj_01_Ang_Center 0;
BA_ "PF_Sig_Name" SG_ 896 VID_Obj_01_Ang_Center "BV1_Obj_01_WnklMitte";
BA_ "GenSigSendType" SG_ 896 VID_Obj_01_Stat_Measure 0;
BA_ "PF_Sig_Name" SG_ 896 VID_Obj_01_Stat_Measure "BV1_Obj_01_Gemessen";
BA_ "GenSigStartValue" SG_ 896 VID_Obj_01_StdD_Ang_Center 255;
BA_ "GenSigSendType" SG_ 896 VID_Obj_01_StdD_Ang_Center 0;
BA_ "PF_Sig_Name" SG_ 896 VID_Obj_01_StdD_Ang_Center "BV1_Obj_01_WnklMitteStdA";
BA_ "GenSigStartValue" SG_ 896 VID_Obj_01_Class 15;
BA_ "GenSigSendType" SG_ 896 VID_Obj_01_Class 0;
BA_ "PF_Sig_Name" SG_ 896 VID_Obj_01_Class "BV1_Obj_01_Klasse";
BA_ "GenSigStartValue" SG_ 896 VID_Obj_01_RefPoint 15;
BA_ "GenSigSendType" SG_ 896 VID_Obj_01_RefPoint 0;
BA_ "PF_Sig_Name" SG_ 896 VID_Obj_01_RefPoint "BV1_Obj_01_Bezugspunkt";
BA_ "GenSigFuncType" SG_ 897 VID_Obj_01_B_ChkSum 2;
BA_ "GenSigSendType" SG_ 897 VID_Obj_01_B_ChkSum 0;
BA_ "PF_Sig_Name" SG_ 897 VID_Obj_01_B_ChkSum "BV_Obj_01_B_CRC";
BA_ "GenSigFuncType" SG_ 897 VID_Obj_01_B_MsgCnt 1;
BA_ "GenSigSendType" SG_ 897 VID_Obj_01_B_MsgCnt 0;
BA_ "PF_Sig_Name" SG_ 897 VID_Obj_01_B_MsgCnt "BV_Obj_01_B_BZ";
BA_ "GenSigSendType" SG_ 897 VID_Obj_01_B_BlockCnt 3;
BA_ "PF_Sig_Name" SG_ 897 VID_Obj_01_B_BlockCnt "BV1_Obj_01_B_BlockZaehler";
BA_ "GenSigStartValue" SG_ 897 VID_Obj_01_Ang_Width 2047;
BA_ "GenSigSendType" SG_ 897 VID_Obj_01_Ang_Width 0;
BA_ "PF_Sig_Name" SG_ 897 VID_Obj_01_Ang_Width "BV1_Obj_01_WnklBreite";
BA_ "GenSigStartValue" SG_ 897 VID_Obj_01_ProbExist 127;
BA_ "GenSigSendType" SG_ 897 VID_Obj_01_ProbExist 0;
BA_ "PF_Sig_Name" SG_ 897 VID_Obj_01_ProbExist "BV1_Obj_01_ExistenzMass";
BA_ "GenSigStartValue" SG_ 897 VID_Obj_01_StdD_dAng_longitude 63;
BA_ "GenSigSendType" SG_ 897 VID_Obj_01_StdD_dAng_longitude 0;
BA_ "PF_Sig_Name" SG_ 897 VID_Obj_01_StdD_dAng_longitude "BV1_Obj_01_WnklGeschwStdA";
BA_ "GenSigStartValue" SG_ 897 VID_Obj_01_dAng_longitude 511;
BA_ "GenSigSendType" SG_ 897 VID_Obj_01_dAng_longitude 0;
BA_ "PF_Sig_Name" SG_ 897 VID_Obj_01_dAng_longitude "BV1_Obj_01_WnklGeschw";
BA_ "GenSigStartValue" SG_ 897 VID_Obj_01_StdD_Ang_Width 255;
BA_ "GenSigSendType" SG_ 897 VID_Obj_01_StdD_Ang_Width 0;
BA_ "PF_Sig_Name" SG_ 897 VID_Obj_01_StdD_Ang_Width "BV1_Obj_01_WnklBreiteStdA";
BA_ "GenSigFuncType" SG_ 898 VID_Obj_01_C_ChkSum 2;
BA_ "GenSigSendType" SG_ 898 VID_Obj_01_C_ChkSum 0;
BA_ "PF_Sig_Name" SG_ 898 VID_Obj_01_C_ChkSum "BV_Obj_01_C_CRC";
BA_ "GenSigFuncType" SG_ 898 VID_Obj_01_C_MsgCnt 1;
BA_ "GenSigSendType" SG_ 898 VID_Obj_01_C_MsgCnt 0;
BA_ "PF_Sig_Name" SG_ 898 VID_Obj_01_C_MsgCnt "BV_Obj_01_C_BZ";
BA_ "GenSigSendType" SG_ 898 VID_Obj_01_C_BlockCnt 3;
BA_ "PF_Sig_Name" SG_ 898 VID_Obj_01_C_BlockCnt "BV1_Obj_01_C_BlockZaehler";
BA_ "GenSigStartValue" SG_ 898 VID_Obj_01_InvTTC 1023;
BA_ "GenSigSendType" SG_ 898 VID_Obj_01_InvTTC 0;
BA_ "PF_Sig_Name" SG_ 898 VID_Obj_01_InvTTC "BV1_Obj_01_InvTTCBildeb";
BA_ "GenSigStartValue" SG_ 898 VID_Obj_01_StdD_InvTTC 127;
BA_ "GenSigSendType" SG_ 898 VID_Obj_01_StdD_InvTTC 0;
BA_ "PF_Sig_Name" SG_ 898 VID_Obj_01_StdD_InvTTC "BV1_Obj_01_InvTTCBildebStdA";
BA_ "GenSigStartValue" SG_ 898 VID_Obj_01_Ang_Overlap_EgoLane_R 511;
BA_ "GenSigSendType" SG_ 898 VID_Obj_01_Ang_Overlap_EgoLane_R 0;
BA_ "PF_Sig_Name" SG_ 898 VID_Obj_01_Ang_Overlap_EgoLane_R "BV1_Obj_01_UeberdWnklEgoSpurR";
BA_ "GenSigStartValue" SG_ 898 VID_Obj_01_Ang_Overlap_EgoLane_L 511;
BA_ "GenSigSendType" SG_ 898 VID_Obj_01_Ang_Overlap_EgoLane_L 0;
BA_ "PF_Sig_Name" SG_ 898 VID_Obj_01_Ang_Overlap_EgoLane_L "BV1_Obj_01_UeberdWnklEgoSpurL";
BA_ "GenSigStartValue" SG_ 898 VID_Obj_01_Obj_Age 4095;
BA_ "GenSigSendType" SG_ 898 VID_Obj_01_Obj_Age 0;
BA_ "PF_Sig_Name" SG_ 898 VID_Obj_01_Obj_Age "BV1_Obj_01_Alter";
BA_ "GenSigSendType" SG_ 898 VID_Obj_01_BrakeLight 0;
BA_ "PF_Sig_Name" SG_ 898 VID_Obj_01_BrakeLight "BV1_Obj_01_BremsLicht";
BA_ "GenSigFuncType" SG_ 899 VID_Obj_01_D_ChkSum 2;
BA_ "GenSigSendType" SG_ 899 VID_Obj_01_D_ChkSum 0;
BA_ "PF_Sig_Name" SG_ 899 VID_Obj_01_D_ChkSum "BV_Obj_01_D_CRC";
BA_ "GenSigFuncType" SG_ 899 VID_Obj_01_D_MsgCnt 1;
BA_ "GenSigSendType" SG_ 899 VID_Obj_01_D_MsgCnt 0;
BA_ "PF_Sig_Name" SG_ 899 VID_Obj_01_D_MsgCnt "BV_Obj_01_D_BZ";
BA_ "GenSigSendType" SG_ 899 VID_Obj_01_D_BlockCnt 3;
BA_ "PF_Sig_Name" SG_ 899 VID_Obj_01_D_BlockCnt "BV1_Obj_01_D_BlockZaehler";
BA_ "GenSigStartValue" SG_ 899 VID_Obj_01_Ang_Edge_L 1024;
BA_ "GenSigSendType" SG_ 899 VID_Obj_01_Ang_Edge_L 0;
BA_ "PF_Sig_Name" SG_ 899 VID_Obj_01_Ang_Edge_L "BV_Objekt_01_phi_left";
BA_ "GenSigStartValue" SG_ 899 VID_Obj_01_Ang_Edge_R 1024;
BA_ "GenSigSendType" SG_ 899 VID_Obj_01_Ang_Edge_R 0;
BA_ "PF_Sig_Name" SG_ 899 VID_Obj_01_Ang_Edge_R "BV_Objekt_01_phi_right";
BA_ "GenSigStartValue" SG_ 899 VID_Obj_01_StdD_Ang_Edge_L 512;
BA_ "GenSigSendType" SG_ 899 VID_Obj_01_StdD_Ang_Edge_L 0;
BA_ "PF_Sig_Name" SG_ 899 VID_Obj_01_StdD_Ang_Edge_L "BV_Objekt_01_sdv_phi_left";
BA_ "GenSigStartValue" SG_ 899 VID_Obj_01_Obj_ID 255;
BA_ "GenSigSendType" SG_ 899 VID_Obj_01_Obj_ID 0;
BA_ "PF_Sig_Name" SG_ 899 VID_Obj_01_Obj_ID "BV1_Obj_01_ID";
BA_ "GenSigFuncType" SG_ 968 VID_Obj_01_E_ChkSum 2;
BA_ "GenSigSendType" SG_ 968 VID_Obj_01_E_ChkSum 0;
BA_ "PF_Sig_Name" SG_ 968 VID_Obj_01_E_ChkSum "BV_Obj_01_E_CRC";
BA_ "GenSigFuncType" SG_ 968 VID_Obj_01_E_MsgCnt 1;
BA_ "GenSigSendType" SG_ 968 VID_Obj_01_E_MsgCnt 0;
BA_ "PF_Sig_Name" SG_ 968 VID_Obj_01_E_MsgCnt "BV_Obj_01_E_BZ";
BA_ "GenSigSendType" SG_ 968 VID_Obj_01_E_BlockCnt 3;
BA_ "PF_Sig_Name" SG_ 968 VID_Obj_01_E_BlockCnt "BV1_Obj_01_E_BlockZaehler";
BA_ "GenSigStartValue" SG_ 968 VID_Obj_01_Velocity_longitudinal 2046;
BA_ "GenSigSendType" SG_ 968 VID_Obj_01_Velocity_longitudinal 0;
BA_ "PF_Sig_Name" SG_ 968 VID_Obj_01_Velocity_longitudinal "BV1_Obj_01_RadialGeschw";
BA_ "GenSigStartValue" SG_ 968 VID_Obj_01_StdD_Velocity_longitu 1022;
BA_ "GenSigSendType" SG_ 968 VID_Obj_01_StdD_Velocity_longitu 0;
BA_ "PF_Sig_Name" SG_ 968 VID_Obj_01_StdD_Velocity_longitu "BV1_Obj_01_RadialGeschw_StdA";
BA_ "SystemSignalLongSymbol" SG_ 968 VID_Obj_01_StdD_Velocity_longitu "VID_Obj_01_StdD_Velocity_longitudinal";
BA_ "GenSigStartValue" SG_ 968 VID_Obj_01_StdD_Ang_Edge_R 512;
BA_ "GenSigSendType" SG_ 968 VID_Obj_01_StdD_Ang_Edge_R 0;
BA_ "PF_Sig_Name" SG_ 968 VID_Obj_01_StdD_Ang_Edge_R "BV_Objekt_01_sdv_phi_right";
BA_ "GenSigStartValue" SG_ 968 VID_Obj_01_ScaleChange 500;
BA_ "GenSigSendType" SG_ 968 VID_Obj_01_ScaleChange 0;
BA_ "PF_Sig_Name" SG_ 968 VID_Obj_01_ScaleChange "BV_Obj_01_ScaleChange";
BA_ "GenSigFuncType" SG_ 900 VID_Obj_02_A_ChkSum 2;
BA_ "GenSigSendType" SG_ 900 VID_Obj_02_A_ChkSum 0;
BA_ "PF_Sig_Name" SG_ 900 VID_Obj_02_A_ChkSum "BV_Obj_02_A_CRC";
BA_ "GenSigFuncType" SG_ 900 VID_Obj_02_A_MsgCnt 1;
BA_ "GenSigSendType" SG_ 900 VID_Obj_02_A_MsgCnt 0;
BA_ "PF_Sig_Name" SG_ 900 VID_Obj_02_A_MsgCnt "BV_Obj_02_A_BZ";
BA_ "GenSigSendType" SG_ 900 VID_Obj_02_A_BlockCnt 3;
BA_ "PF_Sig_Name" SG_ 900 VID_Obj_02_A_BlockCnt "BV1_Obj_02_A_BlockZaehler";
BA_ "GenSigStartValue" SG_ 900 VID_Obj_02_Dist_longitude 4095;
BA_ "GenSigSendType" SG_ 900 VID_Obj_02_Dist_longitude 0;
BA_ "PF_Sig_Name" SG_ 900 VID_Obj_02_Dist_longitude "BV1_Obj_02_Dist_longitude";
BA_ "GenSigStartValue" SG_ 900 VID_Obj_02_StdD_Dist_longitude 127;
BA_ "GenSigSendType" SG_ 900 VID_Obj_02_StdD_Dist_longitude 0;
BA_ "PF_Sig_Name" SG_ 900 VID_Obj_02_StdD_Dist_longitude "BV1_Obj_02_Dist_longitudeStdA";
BA_ "GenSigStartValue" SG_ 900 VID_Obj_02_Ang_Center 2047;
BA_ "GenSigSendType" SG_ 900 VID_Obj_02_Ang_Center 0;
BA_ "PF_Sig_Name" SG_ 900 VID_Obj_02_Ang_Center "BV1_Obj_02_WnklMitte";
BA_ "GenSigSendType" SG_ 900 VID_Obj_02_Stat_Measure 0;
BA_ "PF_Sig_Name" SG_ 900 VID_Obj_02_Stat_Measure "BV1_Obj_02_Gemessen";
BA_ "GenSigStartValue" SG_ 900 VID_Obj_02_StdD_Ang_Center 255;
BA_ "GenSigSendType" SG_ 900 VID_Obj_02_StdD_Ang_Center 0;
BA_ "PF_Sig_Name" SG_ 900 VID_Obj_02_StdD_Ang_Center "BV1_Obj_02_WnklMitteStdA";
BA_ "GenSigStartValue" SG_ 900 VID_Obj_02_Class 15;
BA_ "GenSigSendType" SG_ 900 VID_Obj_02_Class 0;
BA_ "PF_Sig_Name" SG_ 900 VID_Obj_02_Class "BV1_Obj_02_Klasse";
BA_ "GenSigStartValue" SG_ 900 VID_Obj_02_RefPoint 15;
BA_ "GenSigSendType" SG_ 900 VID_Obj_02_RefPoint 0;
BA_ "PF_Sig_Name" SG_ 900 VID_Obj_02_RefPoint "BV1_Obj_02_Bezugspunkt";
BA_ "GenSigFuncType" SG_ 901 VID_Obj_02_B_ChkSum 2;
BA_ "GenSigSendType" SG_ 901 VID_Obj_02_B_ChkSum 0;
BA_ "PF_Sig_Name" SG_ 901 VID_Obj_02_B_ChkSum "BV_Obj_02_B_CRC";
BA_ "GenSigFuncType" SG_ 901 VID_Obj_02_B_MsgCnt 1;
BA_ "GenSigSendType" SG_ 901 VID_Obj_02_B_MsgCnt 0;
BA_ "PF_Sig_Name" SG_ 901 VID_Obj_02_B_MsgCnt "BV_Obj_02_B_BZ";
BA_ "GenSigSendType" SG_ 901 VID_Obj_02_B_BlockCnt 3;
BA_ "PF_Sig_Name" SG_ 901 VID_Obj_02_B_BlockCnt "BV1_Obj_02_B_BlockZaehler";
BA_ "GenSigStartValue" SG_ 901 VID_Obj_02_Ang_Width 2047;
BA_ "GenSigSendType" SG_ 901 VID_Obj_02_Ang_Width 0;
BA_ "PF_Sig_Name" SG_ 901 VID_Obj_02_Ang_Width "BV1_Obj_02_WnklBreite";
BA_ "GenSigStartValue" SG_ 901 VID_Obj_02_ProbExist 127;
BA_ "GenSigSendType" SG_ 901 VID_Obj_02_ProbExist 0;
BA_ "PF_Sig_Name" SG_ 901 VID_Obj_02_ProbExist "BV1_Obj_02_ExistenzMass";
BA_ "GenSigStartValue" SG_ 901 VID_Obj_02_StdD_dAng_longitude 63;
BA_ "GenSigSendType" SG_ 901 VID_Obj_02_StdD_dAng_longitude 0;
BA_ "PF_Sig_Name" SG_ 901 VID_Obj_02_StdD_dAng_longitude "BV1_Obj_02_WnklGeschwStdA";
BA_ "GenSigStartValue" SG_ 901 VID_Obj_02_dAng_longitude 511;
BA_ "GenSigSendType" SG_ 901 VID_Obj_02_dAng_longitude 0;
BA_ "PF_Sig_Name" SG_ 901 VID_Obj_02_dAng_longitude "BV1_Obj_02_WnklGeschw";
BA_ "GenSigStartValue" SG_ 901 VID_Obj_02_StdD_Ang_Width 255;
BA_ "GenSigSendType" SG_ 901 VID_Obj_02_StdD_Ang_Width 0;
BA_ "PF_Sig_Name" SG_ 901 VID_Obj_02_StdD_Ang_Width "BV1_Obj_02_WnklBreiteStdA";
BA_ "GenSigFuncType" SG_ 902 VID_Obj_02_C_ChkSum 2;
BA_ "GenSigSendType" SG_ 902 VID_Obj_02_C_ChkSum 0;
BA_ "PF_Sig_Name" SG_ 902 VID_Obj_02_C_ChkSum "BV_Obj_02_C_CRC";
BA_ "GenSigFuncType" SG_ 902 VID_Obj_02_C_MsgCnt 1;
BA_ "GenSigSendType" SG_ 902 VID_Obj_02_C_MsgCnt 0;
BA_ "PF_Sig_Name" SG_ 902 VID_Obj_02_C_MsgCnt "BV_Obj_02_C_BZ";
BA_ "GenSigSendType" SG_ 902 VID_Obj_02_C_BlockCnt 3;
BA_ "PF_Sig_Name" SG_ 902 VID_Obj_02_C_BlockCnt "BV1_Obj_02_C_BlockZaehler";
BA_ "GenSigStartValue" SG_ 902 VID_Obj_02_InvTTC 1023;
BA_ "GenSigSendType" SG_ 902 VID_Obj_02_InvTTC 0;
BA_ "PF_Sig_Name" SG_ 902 VID_Obj_02_InvTTC "BV1_Obj_02_InvTTCBildeb";
BA_ "GenSigStartValue" SG_ 902 VID_Obj_02_StdD_InvTTC 127;
BA_ "GenSigSendType" SG_ 902 VID_Obj_02_StdD_InvTTC 0;
BA_ "PF_Sig_Name" SG_ 902 VID_Obj_02_StdD_InvTTC "BV1_Obj_02_InvTTCBildebStdA";
BA_ "GenSigStartValue" SG_ 902 VID_Obj_02_Ang_Overlap_EgoLane_R 511;
BA_ "GenSigSendType" SG_ 902 VID_Obj_02_Ang_Overlap_EgoLane_R 0;
BA_ "PF_Sig_Name" SG_ 902 VID_Obj_02_Ang_Overlap_EgoLane_R "BV1_Obj_02_UeberdWnklEgoSpurR";
BA_ "GenSigStartValue" SG_ 902 VID_Obj_02_Ang_Overlap_EgoLane_L 511;
BA_ "GenSigSendType" SG_ 902 VID_Obj_02_Ang_Overlap_EgoLane_L 0;
BA_ "PF_Sig_Name" SG_ 902 VID_Obj_02_Ang_Overlap_EgoLane_L "BV1_Obj_02_UeberdWnklEgoSpurL";
BA_ "GenSigStartValue" SG_ 902 VID_Obj_02_Obj_Age 4095;
BA_ "GenSigSendType" SG_ 902 VID_Obj_02_Obj_Age 0;
BA_ "PF_Sig_Name" SG_ 902 VID_Obj_02_Obj_Age "BV1_Obj_02_Alter";
BA_ "GenSigSendType" SG_ 902 VID_Obj_02_BrakeLight 0;
BA_ "PF_Sig_Name" SG_ 902 VID_Obj_02_BrakeLight "BV1_Obj_02_BremsLicht";
BA_ "GenSigFuncType" SG_ 903 VID_Obj_02_D_ChkSum 2;
BA_ "GenSigSendType" SG_ 903 VID_Obj_02_D_ChkSum 0;
BA_ "PF_Sig_Name" SG_ 903 VID_Obj_02_D_ChkSum "BV_Obj_02_D_CRC";
BA_ "GenSigFuncType" SG_ 903 VID_Obj_02_D_MsgCnt 1;
BA_ "GenSigSendType" SG_ 903 VID_Obj_02_D_MsgCnt 0;
BA_ "PF_Sig_Name" SG_ 903 VID_Obj_02_D_MsgCnt "BV_Obj_02_D_BZ";
BA_ "GenSigSendType" SG_ 903 VID_Obj_02_D_BlockCnt 3;
BA_ "PF_Sig_Name" SG_ 903 VID_Obj_02_D_BlockCnt "BV1_Obj_02_D_BlockZaehler";
BA_ "GenSigStartValue" SG_ 903 VID_Obj_02_Ang_Edge_L 1024;
BA_ "GenSigSendType" SG_ 903 VID_Obj_02_Ang_Edge_L 0;
BA_ "PF_Sig_Name" SG_ 903 VID_Obj_02_Ang_Edge_L "BV_Objekt_02_phi_left";
BA_ "GenSigStartValue" SG_ 903 VID_Obj_02_Ang_Edge_R 1024;
BA_ "GenSigSendType" SG_ 903 VID_Obj_02_Ang_Edge_R 0;
BA_ "PF_Sig_Name" SG_ 903 VID_Obj_02_Ang_Edge_R "BV_Objekt_02_phi_right";
BA_ "GenSigStartValue" SG_ 903 VID_Obj_02_StdD_Ang_Edge_L 512;
BA_ "GenSigSendType" SG_ 903 VID_Obj_02_StdD_Ang_Edge_L 0;
BA_ "PF_Sig_Name" SG_ 903 VID_Obj_02_StdD_Ang_Edge_L "BV_Objekt_02_sdv_phi_left";
BA_ "GenSigStartValue" SG_ 903 VID_Obj_02_Obj_ID 255;
BA_ "GenSigSendType" SG_ 903 VID_Obj_02_Obj_ID 0;
BA_ "PF_Sig_Name" SG_ 903 VID_Obj_02_Obj_ID "BV1_Obj_02_ID";
BA_ "GenSigFuncType" SG_ 969 VID_Obj_02_E_ChkSum 2;
BA_ "GenSigSendType" SG_ 969 VID_Obj_02_E_ChkSum 0;
BA_ "PF_Sig_Name" SG_ 969 VID_Obj_02_E_ChkSum "BV_Obj_02_E_CRC";
BA_ "GenSigFuncType" SG_ 969 VID_Obj_02_E_MsgCnt 1;
BA_ "GenSigSendType" SG_ 969 VID_Obj_02_E_MsgCnt 0;
BA_ "PF_Sig_Name" SG_ 969 VID_Obj_02_E_MsgCnt "BV_Obj_02_E_BZ";
BA_ "GenSigSendType" SG_ 969 VID_Obj_02_E_BlockCnt 3;
BA_ "PF_Sig_Name" SG_ 969 VID_Obj_02_E_BlockCnt "BV1_Obj_02_E_BlockZaehler";
BA_ "GenSigStartValue" SG_ 969 VID_Obj_02_Velocity_longitudinal 2046;
BA_ "GenSigSendType" SG_ 969 VID_Obj_02_Velocity_longitudinal 0;
BA_ "PF_Sig_Name" SG_ 969 VID_Obj_02_Velocity_longitudinal "BV1_Obj_02_RadialGeschw";
BA_ "GenSigStartValue" SG_ 969 VID_Obj_02_StdD_Velocity_longitu 1022;
BA_ "GenSigSendType" SG_ 969 VID_Obj_02_StdD_Velocity_longitu 0;
BA_ "PF_Sig_Name" SG_ 969 VID_Obj_02_StdD_Velocity_longitu "BV1_Obj_02_RadialGeschw_StdA";
BA_ "SystemSignalLongSymbol" SG_ 969 VID_Obj_02_StdD_Velocity_longitu "VID_Obj_02_StdD_Velocity_longitudinal";
BA_ "GenSigStartValue" SG_ 969 VID_Obj_02_StdD_Ang_Edge_R 512;
BA_ "GenSigSendType" SG_ 969 VID_Obj_02_StdD_Ang_Edge_R 0;
BA_ "PF_Sig_Name" SG_ 969 VID_Obj_02_StdD_Ang_Edge_R "BV_Objekt_02_sdv_phi_right";
BA_ "GenSigSendType" SG_ 969 VID_Obj_02_ScaleChange 0;
BA_ "PF_Sig_Name" SG_ 969 VID_Obj_02_ScaleChange "BV_Obj_02_ScaleChange";
BA_ "GenSigFuncType" SG_ 904 VID_Obj_03_A_ChkSum 2;
BA_ "GenSigSendType" SG_ 904 VID_Obj_03_A_ChkSum 0;
BA_ "PF_Sig_Name" SG_ 904 VID_Obj_03_A_ChkSum "BV_Obj_03_A_CRC";
BA_ "GenSigFuncType" SG_ 904 VID_Obj_03_A_MsgCnt 1;
BA_ "GenSigSendType" SG_ 904 VID_Obj_03_A_MsgCnt 0;
BA_ "PF_Sig_Name" SG_ 904 VID_Obj_03_A_MsgCnt "BV_Obj_03_A_BZ";
BA_ "GenSigSendType" SG_ 904 VID_Obj_03_A_BlockCnt 3;
BA_ "PF_Sig_Name" SG_ 904 VID_Obj_03_A_BlockCnt "BV1_Obj_03_A_BlockZaehler";
BA_ "GenSigStartValue" SG_ 904 VID_Obj_03_Dist_longitude 4095;
BA_ "GenSigSendType" SG_ 904 VID_Obj_03_Dist_longitude 0;
BA_ "PF_Sig_Name" SG_ 904 VID_Obj_03_Dist_longitude "BV1_Obj_03_Dist_longitude";
BA_ "GenSigStartValue" SG_ 904 VID_Obj_03_StdD_Dist_longitude 127;
BA_ "GenSigSendType" SG_ 904 VID_Obj_03_StdD_Dist_longitude 0;
BA_ "PF_Sig_Name" SG_ 904 VID_Obj_03_StdD_Dist_longitude "BV1_Obj_03_Dist_longitudeStdA";
BA_ "GenSigStartValue" SG_ 904 VID_Obj_03_Ang_Center 2047;
BA_ "GenSigSendType" SG_ 904 VID_Obj_03_Ang_Center 0;
BA_ "PF_Sig_Name" SG_ 904 VID_Obj_03_Ang_Center "BV1_Obj_03_WnklMitte";
BA_ "GenSigSendType" SG_ 904 VID_Obj_03_Stat_Measure 0;
BA_ "PF_Sig_Name" SG_ 904 VID_Obj_03_Stat_Measure "BV1_Obj_03_Gemessen";
BA_ "GenSigStartValue" SG_ 904 VID_Obj_03_StdD_Ang_Center 255;
BA_ "GenSigSendType" SG_ 904 VID_Obj_03_StdD_Ang_Center 0;
BA_ "PF_Sig_Name" SG_ 904 VID_Obj_03_StdD_Ang_Center "BV1_Obj_03_WnklMitteStdA";
BA_ "GenSigStartValue" SG_ 904 VID_Obj_03_Class 15;
BA_ "GenSigSendType" SG_ 904 VID_Obj_03_Class 0;
BA_ "PF_Sig_Name" SG_ 904 VID_Obj_03_Class "BV1_Obj_03_Klasse";
BA_ "GenSigStartValue" SG_ 904 VID_Obj_03_RefPoint 15;
BA_ "GenSigSendType" SG_ 904 VID_Obj_03_RefPoint 0;
BA_ "PF_Sig_Name" SG_ 904 VID_Obj_03_RefPoint "BV1_Obj_03_Bezugspunkt";
BA_ "GenSigFuncType" SG_ 905 VID_Obj_03_B_ChkSum 2;
BA_ "GenSigSendType" SG_ 905 VID_Obj_03_B_ChkSum 0;
BA_ "PF_Sig_Name" SG_ 905 VID_Obj_03_B_ChkSum "BV_Obj_03_B_CRC";
BA_ "GenSigFuncType" SG_ 905 VID_Obj_03_B_MsgCnt 1;
BA_ "GenSigSendType" SG_ 905 VID_Obj_03_B_MsgCnt 0;
BA_ "PF_Sig_Name" SG_ 905 VID_Obj_03_B_MsgCnt "BV_Obj_03_B_BZ";
BA_ "GenSigSendType" SG_ 905 VID_Obj_03_B_BlockCnt 3;
BA_ "PF_Sig_Name" SG_ 905 VID_Obj_03_B_BlockCnt "BV1_Obj_03_B_BlockZaehler";
BA_ "GenSigStartValue" SG_ 905 VID_Obj_03_Ang_Width 2047;
BA_ "GenSigSendType" SG_ 905 VID_Obj_03_Ang_Width 0;
BA_ "PF_Sig_Name" SG_ 905 VID_Obj_03_Ang_Width "BV1_Obj_03_WnklBreite";
BA_ "GenSigStartValue" SG_ 905 VID_Obj_03_ProbExist 127;
BA_ "GenSigSendType" SG_ 905 VID_Obj_03_ProbExist 0;
BA_ "PF_Sig_Name" SG_ 905 VID_Obj_03_ProbExist "BV1_Obj_03_ExistenzMass";
BA_ "GenSigStartValue" SG_ 905 VID_Obj_03_StdD_dAng_longitude 63;
BA_ "GenSigSendType" SG_ 905 VID_Obj_03_StdD_dAng_longitude 0;
BA_ "PF_Sig_Name" SG_ 905 VID_Obj_03_StdD_dAng_longitude "BV1_Obj_03_WnklGeschwStdA";
BA_ "GenSigStartValue" SG_ 905 VID_Obj_03_dAng_longitude 511;
BA_ "GenSigSendType" SG_ 905 VID_Obj_03_dAng_longitude 0;
BA_ "PF_Sig_Name" SG_ 905 VID_Obj_03_dAng_longitude "BV1_Obj_03_WnklGeschw";
BA_ "GenSigStartValue" SG_ 905 VID_Obj_03_StdD_Ang_Width 255;
BA_ "GenSigSendType" SG_ 905 VID_Obj_03_StdD_Ang_Width 0;
BA_ "PF_Sig_Name" SG_ 905 VID_Obj_03_StdD_Ang_Width "BV1_Obj_03_WnklBreiteStdA";
BA_ "GenSigFuncType" SG_ 906 VID_Obj_03_C_ChkSum 2;
BA_ "GenSigSendType" SG_ 906 VID_Obj_03_C_ChkSum 0;
BA_ "PF_Sig_Name" SG_ 906 VID_Obj_03_C_ChkSum "BV_Obj_03_C_CRC";
BA_ "GenSigFuncType" SG_ 906 VID_Obj_03_C_MsgCnt 1;
BA_ "GenSigSendType" SG_ 906 VID_Obj_03_C_MsgCnt 0;
BA_ "PF_Sig_Name" SG_ 906 VID_Obj_03_C_MsgCnt "BV_Obj_03_C_BZ";
BA_ "GenSigSendType" SG_ 906 VID_Obj_03_C_BlockCnt 3;
BA_ "PF_Sig_Name" SG_ 906 VID_Obj_03_C_BlockCnt "BV1_Obj_03_C_BlockZaehler";
BA_ "GenSigStartValue" SG_ 906 VID_Obj_03_InvTTC 1023;
BA_ "GenSigSendType" SG_ 906 VID_Obj_03_InvTTC 0;
BA_ "PF_Sig_Name" SG_ 906 VID_Obj_03_InvTTC "BV1_Obj_03_InvTTCBildeb";
BA_ "GenSigStartValue" SG_ 906 VID_Obj_03_StdD_InvTTC 127;
BA_ "GenSigSendType" SG_ 906 VID_Obj_03_StdD_InvTTC 0;
BA_ "PF_Sig_Name" SG_ 906 VID_Obj_03_StdD_InvTTC "BV1_Obj_03_InvTTCBildebStdA";
BA_ "GenSigStartValue" SG_ 906 VID_Obj_03_Ang_Overlap_EgoLane_R 511;
BA_ "GenSigSendType" SG_ 906 VID_Obj_03_Ang_Overlap_EgoLane_R 0;
BA_ "PF_Sig_Name" SG_ 906 VID_Obj_03_Ang_Overlap_EgoLane_R "BV1_Obj_03_UeberdWnklEgoSpurR";
BA_ "GenSigStartValue" SG_ 906 VID_Obj_03_Ang_Overlap_EgoLane_L 511;
BA_ "GenSigSendType" SG_ 906 VID_Obj_03_Ang_Overlap_EgoLane_L 0;
BA_ "PF_Sig_Name" SG_ 906 VID_Obj_03_Ang_Overlap_EgoLane_L "BV1_Obj_03_UeberdWnklEgoSpurL";
BA_ "GenSigStartValue" SG_ 906 VID_Obj_03_Obj_Age 4095;
BA_ "GenSigSendType" SG_ 906 VID_Obj_03_Obj_Age 0;
BA_ "PF_Sig_Name" SG_ 906 VID_Obj_03_Obj_Age "BV1_Obj_03_Alter";
BA_ "GenSigSendType" SG_ 906 VID_Obj_03_BrakeLight 0;
BA_ "PF_Sig_Name" SG_ 906 VID_Obj_03_BrakeLight "BV1_Obj_03_BremsLicht";
BA_ "GenSigFuncType" SG_ 907 VID_Obj_03_D_ChkSum 2;
BA_ "GenSigSendType" SG_ 907 VID_Obj_03_D_ChkSum 0;
BA_ "PF_Sig_Name" SG_ 907 VID_Obj_03_D_ChkSum "BV_Obj_03_D_CRC";
BA_ "GenSigFuncType" SG_ 907 VID_Obj_03_D_MsgCnt 1;
BA_ "GenSigSendType" SG_ 907 VID_Obj_03_D_MsgCnt 0;
BA_ "PF_Sig_Name" SG_ 907 VID_Obj_03_D_MsgCnt "BV_Obj_03_D_BZ";
BA_ "GenSigSendType" SG_ 907 VID_Obj_03_D_BlockCnt 3;
BA_ "PF_Sig_Name" SG_ 907 VID_Obj_03_D_BlockCnt "BV1_Obj_03_D_BlockZaehler";
BA_ "GenSigStartValue" SG_ 907 VID_Obj_03_Ang_Edge_L 1024;
BA_ "GenSigSendType" SG_ 907 VID_Obj_03_Ang_Edge_L 0;
BA_ "PF_Sig_Name" SG_ 907 VID_Obj_03_Ang_Edge_L "BV_Objekt_03_phi_left";
BA_ "GenSigStartValue" SG_ 907 VID_Obj_03_Ang_Edge_R 1024;
BA_ "GenSigSendType" SG_ 907 VID_Obj_03_Ang_Edge_R 0;
BA_ "PF_Sig_Name" SG_ 907 VID_Obj_03_Ang_Edge_R "BV_Objekt_03_phi_right";
BA_ "GenSigStartValue" SG_ 907 VID_Obj_03_StdD_Ang_Edge_L 512;
BA_ "GenSigSendType" SG_ 907 VID_Obj_03_StdD_Ang_Edge_L 0;
BA_ "PF_Sig_Name" SG_ 907 VID_Obj_03_StdD_Ang_Edge_L "BV_Objekt_03_sdv_phi_left";
BA_ "GenSigStartValue" SG_ 907 VID_Obj_03_Obj_ID 255;
BA_ "GenSigSendType" SG_ 907 VID_Obj_03_Obj_ID 0;
BA_ "PF_Sig_Name" SG_ 907 VID_Obj_03_Obj_ID "BV1_Obj_03_ID";
BA_ "GenSigFuncType" SG_ 970 VID_Obj_03_E_ChkSum 2;
BA_ "GenSigSendType" SG_ 970 VID_Obj_03_E_ChkSum 0;
BA_ "PF_Sig_Name" SG_ 970 VID_Obj_03_E_ChkSum "BV_Obj_03_E_CRC";
BA_ "GenSigFuncType" SG_ 970 VID_Obj_03_E_MsgCnt 1;
BA_ "GenSigSendType" SG_ 970 VID_Obj_03_E_MsgCnt 0;
BA_ "PF_Sig_Name" SG_ 970 VID_Obj_03_E_MsgCnt "BV_Obj_03_E_BZ";
BA_ "GenSigSendType" SG_ 970 VID_Obj_03_E_BlockCnt 3;
BA_ "PF_Sig_Name" SG_ 970 VID_Obj_03_E_BlockCnt "BV1_Obj_03_E_BlockZaehler";
BA_ "GenSigStartValue" SG_ 970 VID_Obj_03_Velocity_longitudinal 2046;
BA_ "GenSigSendType" SG_ 970 VID_Obj_03_Velocity_longitudinal 0;
BA_ "PF_Sig_Name" SG_ 970 VID_Obj_03_Velocity_longitudinal "BV1_Obj_03_RadialGeschw";
BA_ "GenSigStartValue" SG_ 970 VID_Obj_03_StdD_Velocity_longitu 1022;
BA_ "GenSigSendType" SG_ 970 VID_Obj_03_StdD_Velocity_longitu 0;
BA_ "PF_Sig_Name" SG_ 970 VID_Obj_03_StdD_Velocity_longitu "BV1_Obj_03_RadialGeschw_StdA";
BA_ "SystemSignalLongSymbol" SG_ 970 VID_Obj_03_StdD_Velocity_longitu "VID_Obj_03_StdD_Velocity_longitudinal";
BA_ "GenSigStartValue" SG_ 970 VID_Obj_03_StdD_Ang_Edge_R 512;
BA_ "GenSigSendType" SG_ 970 VID_Obj_03_StdD_Ang_Edge_R 0;
BA_ "PF_Sig_Name" SG_ 970 VID_Obj_03_StdD_Ang_Edge_R "BV_Objekt_03_sdv_phi_right";
BA_ "GenSigSendType" SG_ 970 VID_Obj_03_ScaleChange 0;
BA_ "PF_Sig_Name" SG_ 970 VID_Obj_03_ScaleChange "BV_Obj_03_ScaleChange";
BA_ "GenSigFuncType" SG_ 908 VID_Obj_04_A_ChkSum 2;
BA_ "GenSigSendType" SG_ 908 VID_Obj_04_A_ChkSum 0;
BA_ "PF_Sig_Name" SG_ 908 VID_Obj_04_A_ChkSum "BV_Obj_04_A_CRC";
BA_ "GenSigFuncType" SG_ 908 VID_Obj_04_A_MsgCnt 1;
BA_ "GenSigSendType" SG_ 908 VID_Obj_04_A_MsgCnt 0;
BA_ "PF_Sig_Name" SG_ 908 VID_Obj_04_A_MsgCnt "BV_Obj_04_A_BZ";
BA_ "GenSigSendType" SG_ 908 VID_Obj_04_A_BlockCnt 3;
BA_ "PF_Sig_Name" SG_ 908 VID_Obj_04_A_BlockCnt "BV1_Obj_04_A_BlockZaehler";
BA_ "GenSigStartValue" SG_ 908 VID_Obj_04_Dist_longitude 4095;
BA_ "GenSigSendType" SG_ 908 VID_Obj_04_Dist_longitude 0;
BA_ "PF_Sig_Name" SG_ 908 VID_Obj_04_Dist_longitude "BV1_Obj_04_Dist_longitude";
BA_ "GenSigStartValue" SG_ 908 VID_Obj_04_StdD_Dist_longitude 127;
BA_ "GenSigSendType" SG_ 908 VID_Obj_04_StdD_Dist_longitude 0;
BA_ "PF_Sig_Name" SG_ 908 VID_Obj_04_StdD_Dist_longitude "BV1_Obj_04_Dist_longitudeStdA";
BA_ "GenSigStartValue" SG_ 908 VID_Obj_04_Ang_Center 2047;
BA_ "GenSigSendType" SG_ 908 VID_Obj_04_Ang_Center 0;
BA_ "PF_Sig_Name" SG_ 908 VID_Obj_04_Ang_Center "BV1_Obj_04_WnklMitte";
BA_ "GenSigSendType" SG_ 908 VID_Obj_04_Stat_Measure 0;
BA_ "PF_Sig_Name" SG_ 908 VID_Obj_04_Stat_Measure "BV1_Obj_04_Gemessen";
BA_ "GenSigStartValue" SG_ 908 VID_Obj_04_StdD_Ang_Center 255;
BA_ "GenSigSendType" SG_ 908 VID_Obj_04_StdD_Ang_Center 0;
BA_ "PF_Sig_Name" SG_ 908 VID_Obj_04_StdD_Ang_Center "BV1_Obj_04_WnklMitteStdA";
BA_ "GenSigStartValue" SG_ 908 VID_Obj_04_Class 15;
BA_ "GenSigSendType" SG_ 908 VID_Obj_04_Class 0;
BA_ "PF_Sig_Name" SG_ 908 VID_Obj_04_Class "BV1_Obj_04_Klasse";
BA_ "GenSigStartValue" SG_ 908 VID_Obj_04_RefPoint 15;
BA_ "GenSigSendType" SG_ 908 VID_Obj_04_RefPoint 0;
BA_ "PF_Sig_Name" SG_ 908 VID_Obj_04_RefPoint "BV1_Obj_04_Bezugspunkt";
BA_ "GenSigFuncType" SG_ 909 VID_Obj_04_B_ChkSum 2;
BA_ "GenSigSendType" SG_ 909 VID_Obj_04_B_ChkSum 0;
BA_ "PF_Sig_Name" SG_ 909 VID_Obj_04_B_ChkSum "BV_Obj_04_B_CRC";
BA_ "GenSigFuncType" SG_ 909 VID_Obj_04_B_MsgCnt 1;
BA_ "GenSigSendType" SG_ 909 VID_Obj_04_B_MsgCnt 0;
BA_ "PF_Sig_Name" SG_ 909 VID_Obj_04_B_MsgCnt "BV_Obj_04_B_BZ";
BA_ "GenSigSendType" SG_ 909 VID_Obj_04_B_BlockCnt 3;
BA_ "PF_Sig_Name" SG_ 909 VID_Obj_04_B_BlockCnt "BV1_Obj_04_B_BlockZaehler";
BA_ "GenSigStartValue" SG_ 909 VID_Obj_04_Ang_Width 2047;
BA_ "GenSigSendType" SG_ 909 VID_Obj_04_Ang_Width 0;
BA_ "PF_Sig_Name" SG_ 909 VID_Obj_04_Ang_Width "BV1_Obj_04_WnklBreite";
BA_ "GenSigStartValue" SG_ 909 VID_Obj_04_ProbExist 127;
BA_ "GenSigSendType" SG_ 909 VID_Obj_04_ProbExist 0;
BA_ "PF_Sig_Name" SG_ 909 VID_Obj_04_ProbExist "BV1_Obj_04_ExistenzMass";
BA_ "GenSigStartValue" SG_ 909 VID_Obj_04_StdD_dAng_longitude 63;
BA_ "GenSigSendType" SG_ 909 VID_Obj_04_StdD_dAng_longitude 0;
BA_ "PF_Sig_Name" SG_ 909 VID_Obj_04_StdD_dAng_longitude "BV1_Obj_04_WnklGeschwStdA";
BA_ "GenSigStartValue" SG_ 909 VID_Obj_04_dAng_longitude 511;
BA_ "GenSigSendType" SG_ 909 VID_Obj_04_dAng_longitude 0;
BA_ "PF_Sig_Name" SG_ 909 VID_Obj_04_dAng_longitude "BV1_Obj_04_WnklGeschw";
BA_ "GenSigStartValue" SG_ 909 VID_Obj_04_StdD_Ang_Width 255;
BA_ "GenSigSendType" SG_ 909 VID_Obj_04_StdD_Ang_Width 0;
BA_ "PF_Sig_Name" SG_ 909 VID_Obj_04_StdD_Ang_Width "BV1_Obj_04_WnklBreiteStdA";
BA_REL_ "GenSigTimeoutTime" BU_SG_REL_ Radar SG_ 769 VID_Stat_ChkSum 1000;
BA_REL_ "GenSigTimeoutTime" BU_SG_REL_ Radar SG_ 769 VID_Stat_MsgCnt 1000;
BA_REL_ "GenSigTimeoutTime" BU_SG_REL_ Radar SG_ 769 VID_Stat_BlockCnt 1000;
BA_REL_ "GenSigTimeoutTime" BU_SG_REL_ Radar SG_ 769 VID_Stat_ObjDataAge 1000;
BA_REL_ "GenSigTimeoutTime" BU_SG_REL_ Radar SG_ 769 VID_Stat_Upd_Cnt 1000;
BA_REL_ "GenSigTimeoutTime" BU_SG_REL_ Radar SG_ 769 VID_Stat_Intruder 1000;
BA_REL_ "GenSigTimeoutTime" BU_SG_REL_ Radar SG_ 769 VID_Stat_PED_Warning 1000;
BA_REL_ "GenSigTimeoutTime" BU_SG_REL_ Radar SG_ 769 VID_Stat_RFD_notAvail 1000;
BA_REL_ "GenSigTimeoutTime" BU_SG_REL_ Radar SG_ 769 VID_Stat_PED_Config 1000;
BA_REL_ "GenSigTimeoutTime" BU_SG_REL_ Radar SG_ 769 VID_Stat_LaneDataAge 1000;
BA_REL_ "GenSigTimeoutTime" BU_SG_REL_ Radar SG_ 769 VID_Stat_blindness_det 1000;
BA_REL_ "GenSigTimeoutTime" BU_SG_REL_ Radar SG_ 769 VID_Stat_Freesight_nOK 1000;
BA_REL_ "GenSigTimeoutTime" BU_SG_REL_ Radar SG_ 769 VID_Stat_Error 1000;
BA_REL_ "GenSigTimeoutTime" BU_SG_REL_ Radar SG_ 769 VID_Stat_NotAvail 1000;
BA_REL_ "GenSigTimeoutTime" BU_SG_REL_ Radar SG_ 832 VID_Lin_01_A_ChkSum 1000;
BA_REL_ "GenSigTimeoutTime" BU_SG_REL_ Radar SG_ 832 VID_Lin_01_A_MsgCnt 1000;
BA_REL_ "GenSigTimeoutTime" BU_SG_REL_ Radar SG_ 832 VID_Lin_01_A_BlockCnt 1000;
BA_REL_ "GenSigTimeoutTime" BU_SG_REL_ Radar SG_ 832 VID_Lin_01_dx_Start 1000;
BA_REL_ "GenSigTimeoutTime" BU_SG_REL_ Radar SG_ 832 VID_Lin_01_dx_Lookahead 1000;
BA_REL_ "GenSigTimeoutTime" BU_SG_REL_ Radar SG_ 832 VID_Lin_01_dy 1000;
BA_REL_ "GenSigTimeoutTime" BU_SG_REL_ Radar SG_ 832 VID_Lin_01_ProbExists 1000;
BA_REL_ "GenSigTimeoutTime" BU_SG_REL_ Radar SG_ 832 VID_Lin_01_DiffYawAng 1000;
BA_REL_ "GenSigTimeoutTime" BU_SG_REL_ Radar SG_ 833 VID_Lin_01_B_ChkSum 1000;
BA_REL_ "GenSigTimeoutTime" BU_SG_REL_ Radar SG_ 833 VID_Lin_01_B_MsgCnt 1000;
BA_REL_ "GenSigTimeoutTime" BU_SG_REL_ Radar SG_ 833 VID_Lin_01_B_BlockCnt 1000;
BA_REL_ "GenSigTimeoutTime" BU_SG_REL_ Radar SG_ 833 VID_Lin_01_hor_curve_change 1000;
BA_REL_ "GenSigTimeoutTime" BU_SG_REL_ Radar SG_ 833 VID_Lin_01_hor_curve 1000;
BA_REL_ "GenSigTimeoutTime" BU_SG_REL_ Radar SG_ 833 VID_Lin_01_Line_Width 1000;
BA_REL_ "GenSigTimeoutTime" BU_SG_REL_ Radar SG_ 833 VID_Lin_01_Line_ID 1000;
BA_REL_ "GenSigTimeoutTime" BU_SG_REL_ Radar SG_ 833 VID_Lin_01_Line_Type 1000;
BA_REL_ "GenSigTimeoutTime" BU_SG_REL_ Radar SG_ 833 VID_Lin_01_Line_Colour 1000;
BA_REL_ "GenSigTimeoutTime" BU_SG_REL_ Radar SG_ 835 VID_Lin_02_A_ChkSum 1000;
BA_REL_ "GenSigTimeoutTime" BU_SG_REL_ Radar SG_ 835 VID_Lin_02_A_MsgCnt 1000;
BA_REL_ "GenSigTimeoutTime" BU_SG_REL_ Radar SG_ 835 VID_Lin_02_A_BlockCnt 1000;
BA_REL_ "GenSigTimeoutTime" BU_SG_REL_ Radar SG_ 835 VID_Lin_02_dx_Start 1000;
BA_REL_ "GenSigTimeoutTime" BU_SG_REL_ Radar SG_ 835 VID_Lin_02_dx_Lookahead 1000;
BA_REL_ "GenSigTimeoutTime" BU_SG_REL_ Radar SG_ 835 VID_Lin_02_dy 1000;
BA_REL_ "GenSigTimeoutTime" BU_SG_REL_ Radar SG_ 835 VID_Lin_02_ProbExists 1000;
BA_REL_ "GenSigTimeoutTime" BU_SG_REL_ Radar SG_ 835 VID_Lin_02_DiffYawAng 1000;
BA_REL_ "GenSigTimeoutTime" BU_SG_REL_ Radar SG_ 836 VID_Lin_02_B_ChkSum 1000;
BA_REL_ "GenSigTimeoutTime" BU_SG_REL_ Radar SG_ 836 VID_Lin_02_B_MsgCnt 1000;
BA_REL_ "GenSigTimeoutTime" BU_SG_REL_ Radar SG_ 836 VID_Lin_02_B_BlockCnt 1000;
BA_REL_ "GenSigTimeoutTime" BU_SG_REL_ Radar SG_ 836 VID_Lin_02_hor_curve_change 1000;
BA_REL_ "GenSigTimeoutTime" BU_SG_REL_ Radar SG_ 836 VID_Lin_02_hor_curve 1000;
BA_REL_ "GenSigTimeoutTime" BU_SG_REL_ Radar SG_ 836 VID_Lin_02_Line_Width 1000;
BA_REL_ "GenSigTimeoutTime" BU_SG_REL_ Radar SG_ 836 VID_Lin_02_Line_ID 1000;
BA_REL_ "GenSigTimeoutTime" BU_SG_REL_ Radar SG_ 836 VID_Lin_02_Line_Type 1000;
BA_REL_ "GenSigTimeoutTime" BU_SG_REL_ Radar SG_ 836 VID_Lin_02_Line_Colour 1000;
BA_REL_ "GenSigTimeoutTime" BU_SG_REL_ Radar SG_ 838 VID_Lin_03_A_ChkSum 1000;
BA_REL_ "GenSigTimeoutTime" BU_SG_REL_ Radar SG_ 838 VID_Lin_03_A_MsgCnt 1000;
BA_REL_ "GenSigTimeoutTime" BU_SG_REL_ Radar SG_ 838 VID_Lin_03_A_BlockCnt 1000;
BA_REL_ "GenSigTimeoutTime" BU_SG_REL_ Radar SG_ 838 VID_Lin_03_dx_Start 1000;
BA_REL_ "GenSigTimeoutTime" BU_SG_REL_ Radar SG_ 838 VID_Lin_03_dx_Lookahead 1000;
BA_REL_ "GenSigTimeoutTime" BU_SG_REL_ Radar SG_ 838 VID_Lin_03_dy 1000;
BA_REL_ "GenSigTimeoutTime" BU_SG_REL_ Radar SG_ 838 VID_Lin_03_ProbExists 1000;
BA_REL_ "GenSigTimeoutTime" BU_SG_REL_ Radar SG_ 838 VID_Lin_03_DiffYawAng 1000;
BA_REL_ "GenSigTimeoutTime" BU_SG_REL_ Radar SG_ 839 VID_Lin_03_B_ChkSum 1000;
BA_REL_ "GenSigTimeoutTime" BU_SG_REL_ Radar SG_ 839 VID_Lin_03_B_MsgCnt 1000;
BA_REL_ "GenSigTimeoutTime" BU_SG_REL_ Radar SG_ 839 VID_Lin_03_B_BlockCnt 1000;
BA_REL_ "GenSigTimeoutTime" BU_SG_REL_ Radar SG_ 839 VID_Lin_03_hor_curve_change 1000;
BA_REL_ "GenSigTimeoutTime" BU_SG_REL_ Radar SG_ 839 VID_Lin_03_hor_curve 1000;
BA_REL_ "GenSigTimeoutTime" BU_SG_REL_ Radar SG_ 839 VID_Lin_03_Line_Width 1000;
BA_REL_ "GenSigTimeoutTime" BU_SG_REL_ Radar SG_ 839 VID_Lin_03_Line_ID 1000;
BA_REL_ "GenSigTimeoutTime" BU_SG_REL_ Radar SG_ 839 VID_Lin_03_Line_Type 1000;
BA_REL_ "GenSigTimeoutTime" BU_SG_REL_ Radar SG_ 839 VID_Lin_03_Line_Colour 1000;
BA_REL_ "GenSigTimeoutTime" BU_SG_REL_ Radar SG_ 841 VID_Lin_04_A_ChkSum 1000;
BA_REL_ "GenSigTimeoutTime" BU_SG_REL_ Radar SG_ 841 VID_Lin_04_A_MsgCnt 1000;
BA_REL_ "GenSigTimeoutTime" BU_SG_REL_ Radar SG_ 841 VID_Lin_04_A_BlockCnt 1000;
BA_REL_ "GenSigTimeoutTime" BU_SG_REL_ Radar SG_ 841 VID_Lin_04_dx_Start 1000;
BA_REL_ "GenSigTimeoutTime" BU_SG_REL_ Radar SG_ 841 VID_Lin_04_dx_Lookahead 1000;
BA_REL_ "GenSigTimeoutTime" BU_SG_REL_ Radar SG_ 841 VID_Lin_04_dy 1000;
BA_REL_ "GenSigTimeoutTime" BU_SG_REL_ Radar SG_ 841 VID_Lin_04_ProbExists 1000;
BA_REL_ "GenSigTimeoutTime" BU_SG_REL_ Radar SG_ 841 VID_Lin_04_DiffYawAng 1000;
BA_REL_ "GenSigTimeoutTime" BU_SG_REL_ Radar SG_ 842 VID_Lin_04_B_ChkSum 1000;
BA_REL_ "GenSigTimeoutTime" BU_SG_REL_ Radar SG_ 842 VID_Lin_04_B_MsgCnt 1000;
BA_REL_ "GenSigTimeoutTime" BU_SG_REL_ Radar SG_ 842 VID_Lin_04_B_BlockCnt 1000;
BA_REL_ "GenSigTimeoutTime" BU_SG_REL_ Radar SG_ 842 VID_Lin_04_hor_curve_change 1000;
BA_REL_ "GenSigTimeoutTime" BU_SG_REL_ Radar SG_ 842 VID_Lin_04_hor_curve 1000;
BA_REL_ "GenSigTimeoutTime" BU_SG_REL_ Radar SG_ 842 VID_Lin_04_Line_Width 1000;
BA_REL_ "GenSigTimeoutTime" BU_SG_REL_ Radar SG_ 842 VID_Lin_04_Line_ID 1000;
BA_REL_ "GenSigTimeoutTime" BU_SG_REL_ Radar SG_ 842 VID_Lin_04_Line_Type 1000;
BA_REL_ "GenSigTimeoutTime" BU_SG_REL_ Radar SG_ 842 VID_Lin_04_Line_Colour 1000;
BA_REL_ "GenSigTimeoutTime" BU_SG_REL_ Radar SG_ 1385 VID_MountPos_x 5000;
BA_REL_ "GenSigTimeoutTime" BU_SG_REL_ Radar SG_ 1385 VID_MountPos_y 5000;
BA_REL_ "GenSigTimeoutTime" BU_SG_REL_ Radar SG_ 1385 VID_MountPos_z 5000;
BA_REL_ "GenSigTimeoutTime" BU_SG_REL_ Radar SG_ 896 VID_Obj_01_A_ChkSum 1000;
BA_REL_ "GenSigTimeoutTime" BU_SG_REL_ Radar SG_ 896 VID_Obj_01_A_MsgCnt 1000;
BA_REL_ "GenSigTimeoutTime" BU_SG_REL_ Radar SG_ 896 VID_Obj_01_A_BlockCnt 1000;
BA_REL_ "GenSigTimeoutTime" BU_SG_REL_ Radar SG_ 896 VID_Obj_01_Dist_longitude 1000;
BA_REL_ "GenSigTimeoutTime" BU_SG_REL_ Radar SG_ 896 VID_Obj_01_StdD_Dist_longitude 1000;
BA_REL_ "GenSigTimeoutTime" BU_SG_REL_ Radar SG_ 896 VID_Obj_01_Ang_Center 1000;
BA_REL_ "GenSigTimeoutTime" BU_SG_REL_ Radar SG_ 896 VID_Obj_01_Stat_Measure 1000;
BA_REL_ "GenSigTimeoutTime" BU_SG_REL_ Radar SG_ 896 VID_Obj_01_StdD_Ang_Center 1000;
BA_REL_ "GenSigTimeoutTime" BU_SG_REL_ Radar SG_ 896 VID_Obj_01_Class 1000;
BA_REL_ "GenSigTimeoutTime" BU_SG_REL_ Radar SG_ 896 VID_Obj_01_RefPoint 1000;
BA_REL_ "GenSigTimeoutTime" BU_SG_REL_ Radar SG_ 897 VID_Obj_01_B_ChkSum 1000;
BA_REL_ "GenSigTimeoutTime" BU_SG_REL_ Radar SG_ 897 VID_Obj_01_B_MsgCnt 1000;
BA_REL_ "GenSigTimeoutTime" BU_SG_REL_ Radar SG_ 897 VID_Obj_01_B_BlockCnt 1000;
BA_REL_ "GenSigTimeoutTime" BU_SG_REL_ Radar SG_ 897 VID_Obj_01_Ang_Width 1000;
BA_REL_ "GenSigTimeoutTime" BU_SG_REL_ Radar SG_ 897 VID_Obj_01_ProbExist 1000;
BA_REL_ "GenSigTimeoutTime" BU_SG_REL_ Radar SG_ 897 VID_Obj_01_StdD_dAng_longitude 1000;
BA_REL_ "GenSigTimeoutTime" BU_SG_REL_ Radar SG_ 897 VID_Obj_01_dAng_longitude 1000;
BA_REL_ "GenSigTimeoutTime" BU_SG_REL_ Radar SG_ 897 VID_Obj_01_StdD_Ang_Width 1000;
BA_REL_ "GenSigTimeoutTime" BU_SG_REL_ Radar SG_ 898 VID_Obj_01_C_ChkSum 1000;
BA_REL_ "GenSigTimeoutTime" BU_SG_REL_ Radar SG_ 898 VID_Obj_01_C_MsgCnt 1000;
BA_REL_ "GenSigTimeoutTime" BU_SG_REL_ Radar SG_ 898 VID_Obj_01_C_BlockCnt 1000;
BA_REL_ "GenSigTimeoutTime" BU_SG_REL_ Radar SG_ 898 VID_Obj_01_InvTTC 1000;
BA_REL_ "GenSigTimeoutTime" BU_SG_REL_ Radar SG_ 898 VID_Obj_01_StdD_InvTTC 1000;
BA_REL_ "GenSigTimeoutTime" BU_SG_REL_ Radar SG_ 898 VID_Obj_01_Ang_Overlap_EgoLane_R 1000;
BA_REL_ "GenSigTimeoutTime" BU_SG_REL_ Radar SG_ 898 VID_Obj_01_Ang_Overlap_EgoLane_L 1000;
BA_REL_ "GenSigTimeoutTime" BU_SG_REL_ Radar SG_ 898 VID_Obj_01_Obj_Age 1000;
BA_REL_ "GenSigTimeoutTime" BU_SG_REL_ Radar SG_ 898 VID_Obj_01_BrakeLight 1000;
BA_REL_ "GenSigTimeoutTime" BU_SG_REL_ Radar SG_ 899 VID_Obj_01_D_ChkSum 1000;
BA_REL_ "GenSigTimeoutTime" BU_SG_REL_ Radar SG_ 899 VID_Obj_01_D_MsgCnt 1000;
BA_REL_ "GenSigTimeoutTime" BU_SG_REL_ Radar SG_ 899 VID_Obj_01_D_BlockCnt 1000;
BA_REL_ "GenSigTimeoutTime" BU_SG_REL_ Radar SG_ 899 VID_Obj_01_Ang_Edge_L 1000;
BA_REL_ "GenSigTimeoutTime" BU_SG_REL_ Radar SG_ 899 VID_Obj_01_Ang_Edge_R 1000;
BA_REL_ "GenSigTimeoutTime" BU_SG_REL_ Radar SG_ 899 VID_Obj_01_StdD_Ang_Edge_L 1000;
BA_REL_ "GenSigTimeoutTime" BU_SG_REL_ Radar SG_ 899 VID_Obj_01_Obj_ID 1000;
BA_REL_ "GenSigTimeoutTime" BU_SG_REL_ Radar SG_ 968 VID_Obj_01_E_ChkSum 1000;
BA_REL_ "GenSigTimeoutTime" BU_SG_REL_ Radar SG_ 968 VID_Obj_01_E_MsgCnt 1000;
BA_REL_ "GenSigTimeoutTime" BU_SG_REL_ Radar SG_ 968 VID_Obj_01_E_BlockCnt 1000;
BA_REL_ "GenSigTimeoutTime" BU_SG_REL_ Radar SG_ 968 VID_Obj_01_Velocity_longitudinal 1000;
BA_REL_ "GenSigTimeoutTime" BU_SG_REL_ Radar SG_ 968 VID_Obj_01_StdD_Velocity_longitu 1000;
BA_REL_ "GenSigTimeoutTime" BU_SG_REL_ Radar SG_ 968 VID_Obj_01_StdD_Ang_Edge_R 1000;
BA_REL_ "GenSigTimeoutTime" BU_SG_REL_ Radar SG_ 968 VID_Obj_01_ScaleChange 1000;
BA_REL_ "GenSigTimeoutTime" BU_SG_REL_ Radar SG_ 900 VID_Obj_02_A_ChkSum 1000;
BA_REL_ "GenSigTimeoutTime" BU_SG_REL_ Radar SG_ 900 VID_Obj_02_A_MsgCnt 1000;
BA_REL_ "GenSigTimeoutTime" BU_SG_REL_ Radar SG_ 900 VID_Obj_02_A_BlockCnt 1000;
BA_REL_ "GenSigTimeoutTime" BU_SG_REL_ Radar SG_ 900 VID_Obj_02_Dist_longitude 1000;
BA_REL_ "GenSigTimeoutTime" BU_SG_REL_ Radar SG_ 900 VID_Obj_02_StdD_Dist_longitude 1000;
BA_REL_ "GenSigTimeoutTime" BU_SG_REL_ Radar SG_ 900 VID_Obj_02_Ang_Center 1000;
BA_REL_ "GenSigTimeoutTime" BU_SG_REL_ Radar SG_ 900 VID_Obj_02_Stat_Measure 1000;
BA_REL_ "GenSigTimeoutTime" BU_SG_REL_ Radar SG_ 900 VID_Obj_02_StdD_Ang_Center 1000;
BA_REL_ "GenSigTimeoutTime" BU_SG_REL_ Radar SG_ 900 VID_Obj_02_Class 1000;
BA_REL_ "GenSigTimeoutTime" BU_SG_REL_ Radar SG_ 900 VID_Obj_02_RefPoint 1000;
BA_REL_ "GenSigTimeoutTime" BU_SG_REL_ Radar SG_ 901 VID_Obj_02_B_ChkSum 1000;
BA_REL_ "GenSigTimeoutTime" BU_SG_REL_ Radar SG_ 901 VID_Obj_02_B_MsgCnt 1000;
BA_REL_ "GenSigTimeoutTime" BU_SG_REL_ Radar SG_ 901 VID_Obj_02_B_BlockCnt 1000;
BA_REL_ "GenSigTimeoutTime" BU_SG_REL_ Radar SG_ 901 VID_Obj_02_Ang_Width 1000;
BA_REL_ "GenSigTimeoutTime" BU_SG_REL_ Radar SG_ 901 VID_Obj_02_ProbExist 1000;
BA_REL_ "GenSigTimeoutTime" BU_SG_REL_ Radar SG_ 901 VID_Obj_02_StdD_dAng_longitude 1000;
BA_REL_ "GenSigTimeoutTime" BU_SG_REL_ Radar SG_ 901 VID_Obj_02_dAng_longitude 1000;
BA_REL_ "GenSigTimeoutTime" BU_SG_REL_ Radar SG_ 901 VID_Obj_02_StdD_Ang_Width 1000;
BA_REL_ "GenSigTimeoutTime" BU_SG_REL_ Radar SG_ 902 VID_Obj_02_C_ChkSum 1000;
BA_REL_ "GenSigTimeoutTime" BU_SG_REL_ Radar SG_ 902 VID_Obj_02_C_MsgCnt 1000;
BA_REL_ "GenSigTimeoutTime" BU_SG_REL_ Radar SG_ 902 VID_Obj_02_C_BlockCnt 1000;
BA_REL_ "GenSigTimeoutTime" BU_SG_REL_ Radar SG_ 902 VID_Obj_02_InvTTC 1000;
BA_REL_ "GenSigTimeoutTime" BU_SG_REL_ Radar SG_ 902 VID_Obj_02_StdD_InvTTC 1000;
BA_REL_ "GenSigTimeoutTime" BU_SG_REL_ Radar SG_ 902 VID_Obj_02_Ang_Overlap_EgoLane_R 1000;
BA_REL_ "GenSigTimeoutTime" BU_SG_REL_ Radar SG_ 902 VID_Obj_02_Ang_Overlap_EgoLane_L 1000;
BA_REL_ "GenSigTimeoutTime" BU_SG_REL_ Radar SG_ 902 VID_Obj_02_Obj_Age 1000;
BA_REL_ "GenSigTimeoutTime" BU_SG_REL_ Radar SG_ 902 VID_Obj_02_BrakeLight 1000;
BA_REL_ "GenSigTimeoutTime" BU_SG_REL_ Radar SG_ 903 VID_Obj_02_D_ChkSum 1000;
BA_REL_ "GenSigTimeoutTime" BU_SG_REL_ Radar SG_ 903 VID_Obj_02_D_MsgCnt 1000;
BA_REL_ "GenSigTimeoutTime" BU_SG_REL_ Radar SG_ 903 VID_Obj_02_D_BlockCnt 1000;
BA_REL_ "GenSigTimeoutTime" BU_SG_REL_ Radar SG_ 903 VID_Obj_02_Ang_Edge_L 1000;
BA_REL_ "GenSigTimeoutTime" BU_SG_REL_ Radar SG_ 903 VID_Obj_02_Ang_Edge_R 1000;
BA_REL_ "GenSigTimeoutTime" BU_SG_REL_ Radar SG_ 903 VID_Obj_02_StdD_Ang_Edge_L 1000;
BA_REL_ "GenSigTimeoutTime" BU_SG_REL_ Radar SG_ 903 VID_Obj_02_Obj_ID 1000;
BA_REL_ "GenSigTimeoutTime" BU_SG_REL_ Radar SG_ 969 VID_Obj_02_E_ChkSum 1000;
BA_REL_ "GenSigTimeoutTime" BU_SG_REL_ Radar SG_ 969 VID_Obj_02_E_MsgCnt 1000;
BA_REL_ "GenSigTimeoutTime" BU_SG_REL_ Radar SG_ 969 VID_Obj_02_E_BlockCnt 1000;
BA_REL_ "GenSigTimeoutTime" BU_SG_REL_ Radar SG_ 969 VID_Obj_02_Velocity_longitudinal 1000;
BA_REL_ "GenSigTimeoutTime" BU_SG_REL_ Radar SG_ 969 VID_Obj_02_StdD_Velocity_longitu 1000;
BA_REL_ "GenSigTimeoutTime" BU_SG_REL_ Radar SG_ 969 VID_Obj_02_StdD_Ang_Edge_R 1000;
BA_REL_ "GenSigTimeoutTime" BU_SG_REL_ Radar SG_ 969 VID_Obj_02_ScaleChange 1000;
BA_REL_ "GenSigTimeoutTime" BU_SG_REL_ Radar SG_ 904 VID_Obj_03_A_ChkSum 1000;
BA_REL_ "GenSigTimeoutTime" BU_SG_REL_ Radar SG_ 904 VID_Obj_03_A_MsgCnt 1000;
BA_REL_ "GenSigTimeoutTime" BU_SG_REL_ Radar SG_ 904 VID_Obj_03_A_BlockCnt 1000;
BA_REL_ "GenSigTimeoutTime" BU_SG_REL_ Radar SG_ 904 VID_Obj_03_Dist_longitude 1000;
BA_REL_ "GenSigTimeoutTime" BU_SG_REL_ Radar SG_ 904 VID_Obj_03_StdD_Dist_longitude 1000;
BA_REL_ "GenSigTimeoutTime" BU_SG_REL_ Radar SG_ 904 VID_Obj_03_Ang_Center 1000;
BA_REL_ "GenSigTimeoutTime" BU_SG_REL_ Radar SG_ 904 VID_Obj_03_Stat_Measure 1000;
BA_REL_ "GenSigTimeoutTime" BU_SG_REL_ Radar SG_ 904 VID_Obj_03_StdD_Ang_Center 1000;
BA_REL_ "GenSigTimeoutTime" BU_SG_REL_ Radar SG_ 904 VID_Obj_03_Class 1000;
BA_REL_ "GenSigTimeoutTime" BU_SG_REL_ Radar SG_ 904 VID_Obj_03_RefPoint 1000;
BA_REL_ "GenSigTimeoutTime" BU_SG_REL_ Radar SG_ 905 VID_Obj_03_B_ChkSum 1000;
BA_REL_ "GenSigTimeoutTime" BU_SG_REL_ Radar SG_ 905 VID_Obj_03_B_MsgCnt 1000;
BA_REL_ "GenSigTimeoutTime" BU_SG_REL_ Radar SG_ 905 VID_Obj_03_B_BlockCnt 1000;
BA_REL_ "GenSigTimeoutTime" BU_SG_REL_ Radar SG_ 905 VID_Obj_03_Ang_Width 1000;
BA_REL_ "GenSigTimeoutTime" BU_SG_REL_ Radar SG_ 905 VID_Obj_03_ProbExist 1000;
BA_REL_ "GenSigTimeoutTime" BU_SG_REL_ Radar SG_ 905 VID_Obj_03_StdD_dAng_longitude 1000;
BA_REL_ "GenSigTimeoutTime" BU_SG_REL_ Radar SG_ 905 VID_Obj_03_dAng_longitude 1000;
BA_REL_ "GenSigTimeoutTime" BU_SG_REL_ Radar SG_ 905 VID_Obj_03_StdD_Ang_Width 1000;
BA_REL_ "GenSigTimeoutTime" BU_SG_REL_ Radar SG_ 906 VID_Obj_03_C_ChkSum 1000;
BA_REL_ "GenSigTimeoutTime" BU_SG_REL_ Radar SG_ 906 VID_Obj_03_C_MsgCnt 1000;
BA_REL_ "GenSigTimeoutTime" BU_SG_REL_ Radar SG_ 906 VID_Obj_03_C_BlockCnt 1000;
BA_REL_ "GenSigTimeoutTime" BU_SG_REL_ Radar SG_ 906 VID_Obj_03_InvTTC 1000;
BA_REL_ "GenSigTimeoutTime" BU_SG_REL_ Radar SG_ 906 VID_Obj_03_StdD_InvTTC 1000;
BA_REL_ "GenSigTimeoutTime" BU_SG_REL_ Radar SG_ 906 VID_Obj_03_Ang_Overlap_EgoLane_R 1000;
BA_REL_ "GenSigTimeoutTime" BU_SG_REL_ Radar SG_ 906 VID_Obj_03_Ang_Overlap_EgoLane_L 1000;
BA_REL_ "GenSigTimeoutTime" BU_SG_REL_ Radar SG_ 906 VID_Obj_03_Obj_Age 1000;
BA_REL_ "GenSigTimeoutTime" BU_SG_REL_ Radar SG_ 906 VID_Obj_03_BrakeLight 1000;
BA_REL_ "GenSigTimeoutTime" BU_SG_REL_ Radar SG_ 907 VID_Obj_03_D_ChkSum 1000;
BA_REL_ "GenSigTimeoutTime" BU_SG_REL_ Radar SG_ 907 VID_Obj_03_D_MsgCnt 1000;
BA_REL_ "GenSigTimeoutTime" BU_SG_REL_ Radar SG_ 907 VID_Obj_03_D_BlockCnt 1000;
BA_REL_ "GenSigTimeoutTime" BU_SG_REL_ Radar SG_ 907 VID_Obj_03_Ang_Edge_L 1000;
BA_REL_ "GenSigTimeoutTime" BU_SG_REL_ Radar SG_ 907 VID_Obj_03_Ang_Edge_R 1000;
BA_REL_ "GenSigTimeoutTime" BU_SG_REL_ Radar SG_ 907 VID_Obj_03_StdD_Ang_Edge_L 1000;
BA_REL_ "GenSigTimeoutTime" BU_SG_REL_ Radar SG_ 907 VID_Obj_03_Obj_ID 1000;
BA_REL_ "GenSigTimeoutTime" BU_SG_REL_ Radar SG_ 970 VID_Obj_03_E_ChkSum 1000;
BA_REL_ "GenSigTimeoutTime" BU_SG_REL_ Radar SG_ 970 VID_Obj_03_E_MsgCnt 1000;
BA_REL_ "GenSigTimeoutTime" BU_SG_REL_ Radar SG_ 970 VID_Obj_03_E_BlockCnt 1000;
BA_REL_ "GenSigTimeoutTime" BU_SG_REL_ Radar SG_ 970 VID_Obj_03_Velocity_longitudinal 1000;
BA_REL_ "GenSigTimeoutTime" BU_SG_REL_ Radar SG_ 970 VID_Obj_03_StdD_Velocity_longitu 1000;
BA_REL_ "GenSigTimeoutTime" BU_SG_REL_ Radar SG_ 970 VID_Obj_03_StdD_Ang_Edge_R 1000;
BA_REL_ "GenSigTimeoutTime" BU_SG_REL_ Radar SG_ 970 VID_Obj_03_ScaleChange 1000;
BA_REL_ "GenSigTimeoutTime" BU_SG_REL_ Radar SG_ 908 VID_Obj_04_A_ChkSum 1000;
BA_REL_ "GenSigTimeoutTime" BU_SG_REL_ Radar SG_ 908 VID_Obj_04_A_MsgCnt 1000;
BA_REL_ "GenSigTimeoutTime" BU_SG_REL_ Radar SG_ 908 VID_Obj_04_A_BlockCnt 1000;
BA_REL_ "GenSigTimeoutTime" BU_SG_REL_ Radar SG_ 908 VID_Obj_04_Dist_longitude 1000;
BA_REL_ "GenSigTimeoutTime" BU_SG_REL_ Radar SG_ 908 VID_Obj_04_StdD_Dist_longitude 1000;
BA_REL_ "GenSigTimeoutTime" BU_SG_REL_ Radar SG_ 908 VID_Obj_04_Ang_Center 1000;
BA_REL_ "GenSigTimeoutTime" BU_SG_REL_ Radar SG_ 908 VID_Obj_04_Stat_Measure 1000;
BA_REL_ "GenSigTimeoutTime" BU_SG_REL_ Radar SG_ 908 VID_Obj_04_StdD_Ang_Center 1000;
BA_REL_ "GenSigTimeoutTime" BU_SG_REL_ Radar SG_ 908 VID_Obj_04_Class 1000;
BA_REL_ "GenSigTimeoutTime" BU_SG_REL_ Radar SG_ 908 VID_Obj_04_RefPoint 1000;
BA_REL_ "GenSigTimeoutTime" BU_SG_REL_ Radar SG_ 909 VID_Obj_04_B_ChkSum 1000;
BA_REL_ "GenSigTimeoutTime" BU_SG_REL_ Radar SG_ 909 VID_Obj_04_B_MsgCnt 1000;
BA_REL_ "GenSigTimeoutTime" BU_SG_REL_ Radar SG_ 909 VID_Obj_04_B_BlockCnt 1000;
BA_REL_ "GenSigTimeoutTime" BU_SG_REL_ Radar SG_ 909 VID_Obj_04_Ang_Width 1000;
BA_REL_ "GenSigTimeoutTime" BU_SG_REL_ Radar SG_ 909 VID_Obj_04_ProbExist 1000;
BA_REL_ "GenSigTimeoutTime" BU_SG_REL_ Radar SG_ 909 VID_Obj_04_StdD_dAng_longitude 1000;
BA_REL_ "GenSigTimeoutTime" BU_SG_REL_ Radar SG_ 909 VID_Obj_04_dAng_longitude 1000;
BA_REL_ "GenSigTimeoutTime" BU_SG_REL_ Radar SG_ 909 VID_Obj_04_StdD_Ang_Width 1000;
VAL_ 855 RDR_Obj_07_RFF 0 "not_fused" ;
VAL_ 854 RDR_Obj_06_RFF 0 "no fuse" ;
VAL_ 853 RDR_Obj_05_RFF 0 "not_fused" ;
VAL_ 2617145882 BV_Tramo_Yaw 8191 "Error" 8190 "Init" ;
VAL_ 2617145882 BV_Tramo_Roll 8191 "Error" 8190 "Init" ;
VAL_ 2617145882 BV_Tramo_Pitch 8191 "Error" 8190 "Init" ;
VAL_ 770 HU_navCurrentRoadType 7 "Reserved" 6 "Reserved" 5 "road type class5:highway,national road ,speed road" 4 "road type class4:province road ,mainly road" 3 "road type class3:mainly road in city,normal provinceroad,mainly street" 2 "road type class2:mainly road in city" 1 "road type class1:Secondary roads" 0 "road type unknown:small road,walking Street" ;
VAL_ 770 SpeedLimitationValue 255 "Invalid" ;
VAL_ 770 HandsOffL4Warning 3 "reserved" 2 "reserved" 1 "warning" 0 "No warning" ;
VAL_ 770 VID_Stat2_Camera_State 3 "Camera_Error" 2 "Camera_Shut_down" 1 "Camera_Init" 0 "Camera_Normal" ;
VAL_ 256 RDR1ObjectDataAge 1023 "Daten_aelter_als_Maximum" ;
VAL_ 256 StatusACC 0 "OFF MODE" 1 "PASSIVE MODE" 2 "STANDBY MODE" 3 "ACTIVE CONTROL MODE" 4 "Brake_Only Mode" 5 "Override" 6 "Stand Wait" 7 "Failure mode" ;
VAL_ 256 TjaFID 0 "no TJA related errors detected" 1 "TJA related errors detected. TJA feature needs to go to error state." ;
VAL_ 256 FRS_ALOD_ControlType 0 "None" 1 "CC(Reserved)" 2 "ACC" 3 "ICC" 4 "Reserved" 5 "Reserved" 6 "Reserved" 7 "Reserved" ;
VAL_ 769 VID_Stat_ObjDataAge 1023 "data_expired" ;
VAL_ 769 VID_Stat_Intruder 0 "no_intruder_detected" 1 "intruders_detected" ;
VAL_ 769 VID_Stat_PED_Warning 0 "off" 1 "on" 2 "not_available" 3 "error" ;
VAL_ 769 VID_Stat_RFD_notAvail 0 "Intruder_available" 1 "Intruder_not_available" 3 "error" ;
VAL_ 769 VID_Stat_PED_Config 0 "off" 1 "on" ;
VAL_ 769 VID_Stat_LaneDataAge 1023 "data_expired" ;
VAL_ 769 VID_Stat_blindness_det 0 "no_blindness_detected" 1 "blindness_detected" ;
VAL_ 769 VID_Stat_Freesight_nOK 0 "freesight_ok" 1 "freesight_not_ok" ;
VAL_ 769 VID_Stat_Error 0 "no_stat_error" 1 "error" ;
VAL_ 769 VID_Stat_NotAvail 0 "available" 1 "not_available" ;
VAL_ 769 VID_Stat_TJAICAStatus 0 "OFF" 1 "ON_Standby" 2 "ON_Active" 3 "FAULT" 4 "Reserved" 5 "Reserved" 6 "IACC_State_ON_Suspend" 7 "IACC_State_ON_NotTIPL" ;
VAL_ 833 VID_Lin_01_Line_ID 0 "no_line" ;
VAL_ 833 VID_Lin_01_Line_Type 0 "no_line" 1 "solid_line" 2 "dashed_line" 3 "curb" 4 "lawn" 5 "Botts_dot" 6 "other" 7 "undefined" ;
VAL_ 833 VID_Lin_01_Line_Colour 0 "no_line" 1 "white" 2 "red" 3 "yellow" 4 "other" 5 "undefined" 6 "undefined" 7 "undefined" ;
VAL_ 836 VID_Lin_02_Line_ID 0 "no_line" ;
VAL_ 836 VID_Lin_02_Line_Type 0 "no_line" 1 "solid_line" 2 "dashed_line" 3 "curb" 4 "lawn" 5 "Botts_dot" 6 "other" 7 "undefined" ;
VAL_ 836 VID_Lin_02_Line_Colour 0 "no_line" 1 "white" 2 "red" 3 "yellow" 4 "other" 5 "undefined" 6 "undefined" 7 "undefined" ;
VAL_ 839 VID_Lin_03_Line_ID 0 "no_line" ;
VAL_ 839 VID_Lin_03_Line_Type 0 "no_line" 1 "solid_line" 2 "dashed_line" 3 "curb" 4 "lawn" 5 "Botts_dot" 6 "other" 7 "undefined" ;
VAL_ 839 VID_Lin_03_Line_Colour 0 "no_line" 1 "white" 2 "red" 3 "yellow" 4 "other" 5 "undefined" 6 "undefined" 7 "undefined" ;
VAL_ 842 VID_Lin_04_Line_ID 0 "no_line" ;
VAL_ 842 VID_Lin_04_Line_Type 0 "no_line" 1 "solid_line" 2 "dashed_line" 3 "curb" 4 "lawn" 5 "Botts_dot" 6 "other" 7 "undefined" ;
VAL_ 842 VID_Lin_04_Line_Colour 0 "no_line" 1 "white" 2 "red" 3 "yellow" 4 "other" 5 "undefined" 6 "undefined" 7 "undefined" ;
VAL_ 1385 VID_MountPos_x 4095 "error" ;
VAL_ 1385 VID_MountPos_y 4095 "error" ;
VAL_ 1385 VID_MountPos_z 4095 "error" ;
VAL_ 896 VID_Obj_01_Dist_longitude 4095 "init" ;
VAL_ 896 VID_Obj_01_StdD_Dist_longitude 127 "init" ;
VAL_ 896 VID_Obj_01_Ang_Center 2047 "init" ;
VAL_ 896 VID_Obj_01_Stat_Measure 0 "obj_predicted" 1 "obj_measured" 2 "obj_featuretracked" 3 "NR_intruder_or_overtakeing" ;
VAL_ 896 VID_Obj_01_StdD_Ang_Center 255 "init" ;
VAL_ 896 VID_Obj_01_Class 0 "unknown" 1 "overrideable" 2 "underridable" 3 "pedestrian" 4 "pedestrian_multiple" 5 "bicycle" 6 "motorcycle" 7 "passengercar" 8 "van" 9 "heavy_truck" 10 "stationary" 11 "animal" 12 "retroreflector" 15 "init" ;
VAL_ 896 VID_Obj_01_RefPoint 0 "unclassified" 1 "front_left" 2 "front_center" 3 "front_right" 4 "right_side_center" 5 "rear_right" 6 "rear_center" 7 "rear_left" 8 "left_side_center" 9 "center" 15 "init" ;
VAL_ 897 VID_Obj_01_Ang_Width 2047 "init" ;
VAL_ 897 VID_Obj_01_ProbExist 127 "init" ;
VAL_ 897 VID_Obj_01_StdD_dAng_longitude 63 "init" ;
VAL_ 897 VID_Obj_01_dAng_longitude 511 "init" ;
VAL_ 897 VID_Obj_01_StdD_Ang_Width 255 "init" ;
VAL_ 898 VID_Obj_01_InvTTC 1023 "init" ;
VAL_ 898 VID_Obj_01_StdD_InvTTC 127 "init" ;
VAL_ 898 VID_Obj_01_Ang_Overlap_EgoLane_R 511 "init" ;
VAL_ 898 VID_Obj_01_Ang_Overlap_EgoLane_L 511 "init" ;
VAL_ 898 VID_Obj_01_Obj_Age 4095 "init" ;
VAL_ 898 VID_Obj_01_BrakeLight 0 "no_brakelight_detected" 1 "brakelight_detected" ;
VAL_ 899 VID_Obj_01_Obj_ID 0 "no_valid_object" 255 "init" ;
VAL_ 968 VID_Obj_01_Velocity_longitudinal 2046 "init" ;
VAL_ 968 VID_Obj_01_StdD_Velocity_longitu 1022 "init" ;
VAL_ 968 VID_Obj_01_ScaleChange 1023 "undefined" ;
VAL_ 900 VID_Obj_02_Dist_longitude 4095 "init" ;
VAL_ 900 VID_Obj_02_StdD_Dist_longitude 127 "init" ;
VAL_ 900 VID_Obj_02_Ang_Center 2047 "init" ;
VAL_ 900 VID_Obj_02_Stat_Measure 0 "obj_predicted" 1 "obj_measured" 2 "obj_featuretracked" 3 "NR_intruder_or_overtakeing" ;
VAL_ 900 VID_Obj_02_StdD_Ang_Center 255 "init" ;
VAL_ 900 VID_Obj_02_Class 0 "unknown" 1 "overrideable" 2 "underridable" 3 "pedestrian" 4 "pedestrian_multiple" 5 "bicycle" 6 "motorcycle" 7 "passengercar" 8 "van" 9 "heavy_truck" 10 "stationary" 11 "animal" 12 "retroreflector" 15 "init" ;
VAL_ 900 VID_Obj_02_RefPoint 0 "unclassified" 1 "front_left" 2 "front_center" 3 "front_right" 4 "right_side_center" 5 "rear_right" 6 "rear_center" 7 "rear_left" 8 "left_side_center" 9 "center" 15 "init" ;
VAL_ 901 VID_Obj_02_Ang_Width 2047 "init" ;
VAL_ 901 VID_Obj_02_ProbExist 127 "init" ;
VAL_ 901 VID_Obj_02_StdD_dAng_longitude 63 "init" ;
VAL_ 901 VID_Obj_02_dAng_longitude 511 "init" ;
VAL_ 901 VID_Obj_02_StdD_Ang_Width 255 "init" ;
VAL_ 902 VID_Obj_02_InvTTC 1023 "init" ;
VAL_ 902 VID_Obj_02_StdD_InvTTC 127 "init" ;
VAL_ 902 VID_Obj_02_Ang_Overlap_EgoLane_R 511 "init" ;
VAL_ 902 VID_Obj_02_Ang_Overlap_EgoLane_L 511 "init" ;
VAL_ 902 VID_Obj_02_Obj_Age 4095 "init" ;
VAL_ 902 VID_Obj_02_BrakeLight 0 "no_brakelight_detected" 1 "brakelight_detected" ;
VAL_ 903 VID_Obj_02_Obj_ID 0 "no_valid_object" 255 "init" ;
VAL_ 969 VID_Obj_02_Velocity_longitudinal 2046 "init" ;
VAL_ 969 VID_Obj_02_StdD_Velocity_longitu 1022 "init" ;
VAL_ 969 VID_Obj_02_ScaleChange 1023 "undefined" ;
VAL_ 904 VID_Obj_03_Dist_longitude 4095 "init" ;
VAL_ 904 VID_Obj_03_StdD_Dist_longitude 127 "init" ;
VAL_ 904 VID_Obj_03_Ang_Center 2047 "init" ;
VAL_ 904 VID_Obj_03_Stat_Measure 0 "obj_predicted" 1 "obj_measured" 2 "obj_featuretracked" 3 "NR_intruder_or_overtakeing" ;
VAL_ 904 VID_Obj_03_StdD_Ang_Center 255 "init" ;
VAL_ 904 VID_Obj_03_Class 0 "unknown" 1 "overrideable" 2 "underridable" 3 "pedestrian" 4 "pedestrian_multiple" 5 "bicycle" 6 "motorcycle" 7 "passengercar" 8 "van" 9 "heavy_truck" 10 "stationary" 11 "animal" 12 "retroreflector" 15 "init" ;
VAL_ 904 VID_Obj_03_RefPoint 0 "unclassified" 1 "front_left" 2 "front_center" 3 "front_right" 4 "right_side_center" 5 "rear_right" 6 "rear_center" 7 "rear_left" 8 "left_side_center" 9 "center" 15 "init" ;
VAL_ 905 VID_Obj_03_Ang_Width 2047 "init" ;
VAL_ 905 VID_Obj_03_ProbExist 127 "init" ;
VAL_ 905 VID_Obj_03_StdD_dAng_longitude 63 "init" ;
VAL_ 905 VID_Obj_03_dAng_longitude 511 "init" ;
VAL_ 905 VID_Obj_03_StdD_Ang_Width 255 "init" ;
VAL_ 906 VID_Obj_03_InvTTC 1023 "init" ;
VAL_ 906 VID_Obj_03_StdD_InvTTC 127 "init" ;
VAL_ 906 VID_Obj_03_Ang_Overlap_EgoLane_R 511 "init" ;
VAL_ 906 VID_Obj_03_Ang_Overlap_EgoLane_L 511 "init" ;
VAL_ 906 VID_Obj_03_Obj_Age 4095 "init" ;
VAL_ 906 VID_Obj_03_BrakeLight 0 "no_brakelight_detected" 1 "brakelight_detected" ;
VAL_ 907 VID_Obj_03_Obj_ID 0 "no_valid_object" 255 "init" ;
VAL_ 970 VID_Obj_03_Velocity_longitudinal 2046 "init" ;
VAL_ 970 VID_Obj_03_StdD_Velocity_longitu 1022 "init" ;
VAL_ 970 VID_Obj_03_ScaleChange 1023 "undefined" ;
VAL_ 908 VID_Obj_04_Dist_longitude 4095 "init" ;
VAL_ 908 VID_Obj_04_StdD_Dist_longitude 127 "init" ;
VAL_ 908 VID_Obj_04_Ang_Center 2047 "init" ;
VAL_ 908 VID_Obj_04_Stat_Measure 0 "obj_predicted" 1 "obj_measured" 2 "obj_featuretracked" 3 "NR_intruder_or_overtakeing" ;
VAL_ 908 VID_Obj_04_StdD_Ang_Center 255 "init" ;
VAL_ 908 VID_Obj_04_Class 0 "unknown" 1 "overrideable" 2 "underridable" 3 "pedestrian" 4 "pedestrian_multiple" 5 "bicycle" 6 "motorcycle" 7 "passengercar" 8 "van" 9 "heavy_truck" 10 "stationary" 11 "animal" 12 "retroreflector" 15 "init" ;
VAL_ 908 VID_Obj_04_RefPoint 0 "unclassified" 1 "front_left" 2 "front_center" 3 "front_right" 4 "right_side_center" 5 "rear_right" 6 "rear_center" 7 "rear_left" 8 "left_side_center" 9 "center" 15 "init" ;
VAL_ 909 VID_Obj_04_Ang_Width 2047 "init" ;
VAL_ 909 VID_Obj_04_ProbExist 127 "init" ;
VAL_ 909 VID_Obj_04_StdD_dAng_longitude 63 "init" ;
VAL_ 909 VID_Obj_04_dAng_longitude 511 "init" ;
VAL_ 909 VID_Obj_04_StdD_Ang_Width 255 "init" ;
